VERSION ""

NS_ :

BS_:

BU_: DSAU vHS_M SHVU_RR DPSS AMP ICC RLPSM APSM RWPC RRHV RRPSM CGW_CCU APSS ATS RLHV FPM RDC PSM ASAU

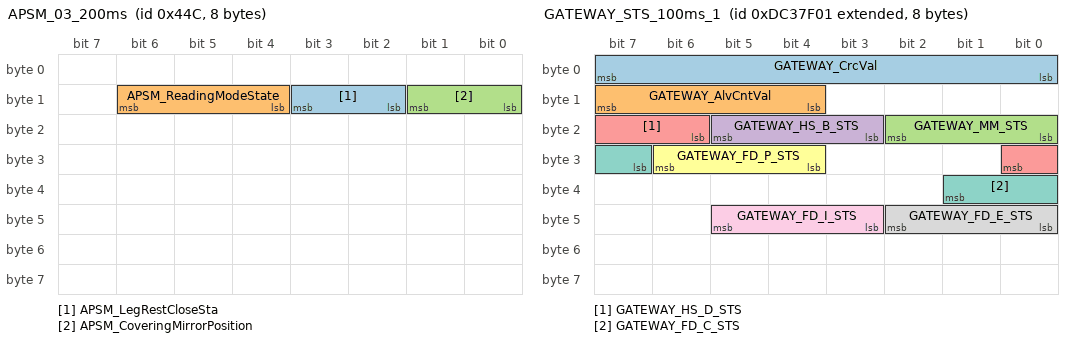
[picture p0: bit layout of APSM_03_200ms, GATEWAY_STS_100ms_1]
BO_ 1100 APSM_03_200ms: 8 APSM
 SG_ APSM_LegRestCloseSta : 10|2@1+ (1,0) [0|0] ""  RRPSM
 SG_ APSM_ReadingModeState : 12|3@1+ (1,0) [0|0] ""  RRPSM
 SG_ APSM_CoveringMirrorPosition : 8|2@1+ (1,0) [0|0] ""  CGW_CCU

BO_ 2378399489 GATEWAY_STS_100ms_1: 8 CGW_CCU
 SG_ GATEWAY_CrcVal : 0|8@1+ (1,0) [0|0] ""  vHS_M
 SG_ GATEWAY_AlvCntVal : 12|4@1+ (1,0) [0|0] ""  Vector__XXX
 SG_ GATEWAY_MM_STS : 16|3@1+ (1,0) [0|0] ""  Vector__XXX
 SG_ GATEWAY_HS_B_STS : 19|3@1+ (1,0) [0|0] ""  Vector__XXX
 SG_ GATEWAY_HS_D_STS : 22|3@1+ (1,0) [0|0] ""  Vector__XXX
 SG_ GATEWAY_FD_P_STS : 28|3@1+ (1,0) [0|0] ""  Vector__XXX
 SG_ GATEWAY_FD_C_STS : 31|3@1+ (1,0) [0|0] ""  Vector__XXX
 SG_ GATEWAY_FD_E_STS : 40|3@1+ (1,0) [0|0] ""  Vector__XXX
 SG_ GATEWAY_FD_I_STS : 43|3@1+ (1,0) [0|0] ""  Vector__XXX

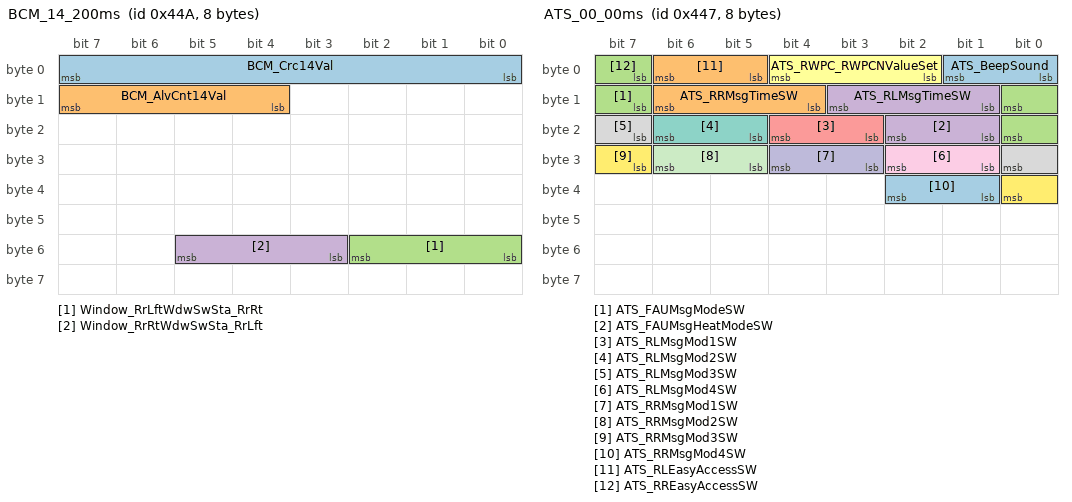
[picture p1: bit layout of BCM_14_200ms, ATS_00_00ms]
BO_ 1098 BCM_14_200ms: 8 CGW_CCU
 SG_ BCM_Crc14Val : 0|8@1+ (1,0) [0|0] ""  Vector__XXX
 SG_ BCM_AlvCnt14Val : 12|4@1+ (1,0) [0|0] ""  Vector__XXX
 SG_ Window_RrLftWdwSwSta_RrRt : 48|3@1+ (1,0) [0|0] ""  RDC
 SG_ Window_RrRtWdwSwSta_RrLft : 51|3@1+ (1,0) [0|0] ""  RDC

BO_ 1092 SMK_02_200ms: 8 CGW_CCU
 SG_ SMK_Crc2Val : 0|8@1+ (1,0) [0|0] ""  Vector__XXX
 SG_ SMK_AlvCnt2Val : 12|4@1+ (1,0) [0|0] ""  Vector__XXX
 SG_ SSB_StrtStpBtnSw1Sta : 16|2@1+ (1,0) [0|0] ""  Vector__XXX
 SG_ SSB_StrtStpBtnSw2Sta : 18|2@1+ (1,0) [0|0] ""  Vector__XXX
 SG_ SMK_TrmnlCtrlSta : 20|4@1+ (1,0) [0|0] ""  Vector__XXX
 SG_ SMK_TrmnlMngrSta : 24|5@1+ (1,0) [0|0] ""  FPM
 SG_ SMK_AuthSta : 29|3@1+ (1,0) [0|0] ""  PSM,APSM,RLPSM,RRPSM
 SG_ SMK_Ign1InSta : 32|2@1+ (1,0) [0|0] ""  Vector__XXX
 SG_ SMK_Ign1RlySta : 34|2@1+ (1,0) [0|0] ""  Vector__XXX
 SG_ SMK_Ign2InSta : 36|2@1+ (1,0) [0|0] ""  Vector__XXX
 SG_ SMK_Ign2RlySta : 38|2@1+ (1,0) [0|0] ""  Vector__XXX
 SG_ SMK_StrtFdbckSta : 40|2@1+ (1,0) [0|0] ""  Vector__XXX
 SG_ SMK_StrtrRlyOutSta : 42|2@1+ (1,0) [0|0] ""  Vector__XXX
 SG_ SMK_AccInSta : 44|2@1+ (1,0) [0|0] ""  Vector__XXX
 SG_ SMK_AccRlySta : 46|2@1+ (1,0) [0|0] ""  Vector__XXX
 SG_ SMK_CLUAccIndOnReq : 48|2@1+ (1,0) [0|0] ""  Vector__XXX
 SG_ SMK_TlEngRunSta : 56|2@1+ (1,0) [0|0] ""  PSM,APSM,RLPSM,RRPSM,RLHV,RRHV,SHVU_RR,DPSS,FPM,ATS,DSAU,ASAU
 SG_ SMK_TlCrnkModSta : 58|2@1+ (1,0) [0|0] ""  PSM,APSM,RLPSM,RRPSM,DPSS,ATS,DSAU,ASAU
 SG_ SMK_RmtKeyEngRunSta : 60|2@1+ (1,0) [0|0] ""  Vector__XXX

BO_ 1093 SMK_06_200ms: 8 CGW_CCU
 SG_ SMK_Crc6Val : 0|8@1+ (1,0) [0|0] ""  Vector__XXX
 SG_ SMK_AlvCnt6Val : 12|4@1+ (1,0) [0|0] ""  Vector__XXX
 SG_ Lamp_HzrdBlnkngSta : 16|3@1+ (1,0) [0|0] ""  Vector__XXX
 SG_ RSPA_LearntSta : 19|2@1+ (1,0) [0|0] ""  Vector__XXX
 SG_ Lamp_SmrtWlcmLtOnReq : 21|2@1+ (1,0) [0|0] ""  Vector__XXX
 SG_ Fob_BattStaInfo : 24|2@1+ (1,0) [0|0] ""  Vector__XXX
 SG_ Fob_FoundDrvWlcmArea : 26|2@1+ (1,0) [0|0] ""  Vector__XXX
 SG_ Fob_FoundAsstWlcmArea : 28|2@1+ (1,0) [0|0] ""  Vector__XXX
 SG_ Fob_FoundExtrnlArea : 30|2@1+ (1,0) [0|0] ""  Vector__XXX
 SG_ Fob_FoundIntArea : 32|2@1+ (1,0) [0|0] ""  Vector__XXX
 SG_ Fob_LearntSta : 34|2@1+ (1,0) [0|0] ""  Vector__XXX
 SG_ RSPA_RFSigErrSta : 36|2@1+ (1,0) [0|0] ""  Vector__XXX
 SG_ RSPA_CanErrSta : 38|2@1+ (1,0) [0|0] ""  Vector__XXX
 SG_ LFAnt_FltSta : 40|2@1+ (1,0) [0|0] ""  Vector__XXX
 SG_ LFAnt_SrchSta : 42|2@1+ (1,0) [0|0] ""  RWPC
 SG_ Auth_ISKLearnSta : 44|3@1+ (1,0) [0|0] ""  Vector__XXX
 SG_ RSPA_ModSta_SMK : 48|3@1+ (1,0) [0|0] ""  PSM
 SG_ RSPA_FobBattSta : 51|3@1+ (1,0) [0|0] ""  Vector__XXX
 SG_ Fob_BtnReleasedSta : 54|2@1+ (1,0) [0|0] ""  Vector__XXX
 SG_ USM_SmrtTrnkTlgtModSta : 56|3@1+ (1,0) [0|0] ""  Vector__XXX
 SG_ USM_WALModSta : 59|3@1+ (1,0) [0|0] ""  Vector__XXX
 SG_ Fob_FoundWlcmArea : 62|2@1+ (1,0) [0|0] ""  Vector__XXX

BO_ 1095 ATS_00_00ms: 8 ATS
 SG_ ATS_BeepSound : 0|2@1+ (1,0) [0|0] ""  AMP
 SG_ ATS_RRMsgTimeSW : 12|3@1+ (1,0) [0|0] ""  RLPSM,RRPSM
 SG_ ATS_FAUMsgModeSW : 15|2@1+ (1,0) [0|0] ""  APSM,ASAU,RLPSM,RRPSM
 SG_ ATS_FAUMsgHeatModeSW : 17|2@1+ (1,0) [0|0] ""  APSM,ASAU,RLPSM,RRPSM
 SG_ ATS_RLMsgMod1SW : 19|2@1+ (1,0) [0|0] ""  RLPSM
 SG_ ATS_RWPC_RWPCNValueSet : 2|3@1+ (1,0) [0|0] ""  RWPC
 SG_ ATS_RLMsgMod2SW : 21|2@1+ (1,0) [0|0] ""  RLPSM
 SG_ ATS_RLMsgMod3SW : 23|2@1+ (1,0) [0|0] ""  RLPSM
 SG_ ATS_RLMsgMod4SW : 25|2@1+ (1,0) [0|0] ""  RLPSM
 SG_ ATS_RRMsgMod1SW : 27|2@1+ (1,0) [0|0] ""  RLPSM
 SG_ ATS_RRMsgMod2SW : 29|2@1+ (1,0) [0|0] ""  RLPSM
 SG_ ATS_RRMsgMod3SW : 31|2@1+ (1,0) [0|0] ""  RLPSM
 SG_ ATS_RRMsgMod4SW : 33|2@1+ (1,0) [0|0] ""  RLPSM
 SG_ ATS_RLEasyAccessSW : 5|2@1+ (1,0) [0|0] ""  RLPSM
 SG_ ATS_RREasyAccessSW : 7|2@1+ (1,0) [0|0] ""  RRPSM
 SG_ ATS_RLMsgTimeSW : 9|3@1+ (1,0) [0|0] ""  RLPSM,RRPSM

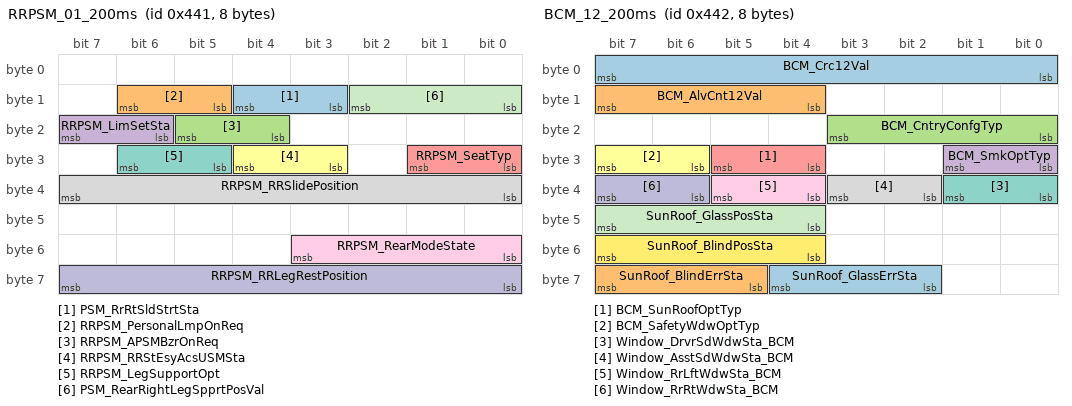
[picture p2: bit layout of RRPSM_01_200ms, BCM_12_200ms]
BO_ 1089 RRPSM_01_200ms: 8 RRPSM
 SG_ PSM_RrRtSldStrtSta : 11|2@1+ (1,0) [0|0] ""  APSM
 SG_ RRPSM_PersonalLmpOnReq : 13|2@1+ (1,0) [0|0] ""  ATS
 SG_ RRPSM_APSMBzrOnReq : 20|2@1+ (1,0) [0|0] ""  APSM,ATS
 SG_ RRPSM_LimSetSta : 22|2@1+ (1,0) [0|0] ""  ATS
 SG_ RRPSM_SeatTyp : 24|2@1+ (1,0) [0|0] ""  APSM,PSM
 SG_ RRPSM_RRStEsyAcsUSMSta : 27|2@1+ (1,0) [0|0] ""  ATS,CGW_CCU
 SG_ RRPSM_LegSupportOpt : 29|2@1+ (1,0) [0|0] ""  ATS,CGW_CCU
 SG_ RRPSM_RRSlidePosition : 32|8@1+ (1,0) [0|0] ""  APSM
 SG_ RRPSM_RearModeState : 48|4@1+ (1,0) [0|0] ""  APSM,ATS,RDC,CGW_CCU
 SG_ RRPSM_RRLegRestPosition : 56|8@1+ (1,0) [0|0] ""  APSM
 SG_ PSM_RearRightLegSpprtPosVal : 8|3@1+ (1,0) [0|0] ""  APSM

BO_ 1090 BCM_12_200ms: 8 CGW_CCU
 SG_ BCM_Crc12Val : 0|8@1+ (1,0) [0|0] ""  Vector__XXX
 SG_ BCM_AlvCnt12Val : 12|4@1+ (1,0) [0|0] ""  Vector__XXX
 SG_ BCM_CntryConfgTyp : 16|4@1+ (1,0) [0|0] ""  RWPC,PSM,APSM,RLPSM,RRPSM,SHVU_RR,RDC,DPSS,APSS,ATS
 SG_ BCM_SmkOptTyp : 24|2@1+ (1,0) [0|0] ""  Vector__XXX
 SG_ BCM_SunRoofOptTyp : 28|2@1+ (1,0) [0|0] ""  AMP,ATS
 SG_ BCM_SafetyWdwOptTyp : 30|2@1+ (1,0) [0|0] ""  Vector__XXX
 SG_ Window_DrvrSdWdwSta_BCM : 32|2@1+ (1,0) [0|0] ""  AMP
 SG_ Window_AsstSdWdwSta_BCM : 34|2@1+ (1,0) [0|0] ""  AMP
 SG_ Window_RrLftWdwSta_BCM : 36|2@1+ (1,0) [0|0] ""  RDC,AMP,ATS
 SG_ Window_RrRtWdwSta_BCM : 38|2@1+ (1,0) [0|0] ""  RDC,AMP,ATS
 SG_ SunRoof_GlassPosSta : 44|4@1+ (1,0) [0|0] ""  Vector__XXX
 SG_ SunRoof_BlindPosSta : 52|4@1+ (1,0) [0|0] ""  Vector__XXX
 SG_ SunRoof_GlassErrSta : 58|3@1+ (1,0) [0|0] ""  Vector__XXX
 SG_ SunRoof_BlindErrSta : 61|3@1+ (1,0) [0|0] ""  Vector__XXX

BO_ 2563128577 HU_AMP_P_01_1: 8 CGW_CCU
 SG_ AMP_SetMaxMainVolStep : 14|2@1+ (1,0) [0|0] ""  AMP

BO_ 2315420673 HU_FPM_E_04_1: 8 CGW_CCU
 SG_ AVN_Encrypted_Result4 : 0|64@1+ (1,0) [0|0] ""  FPM

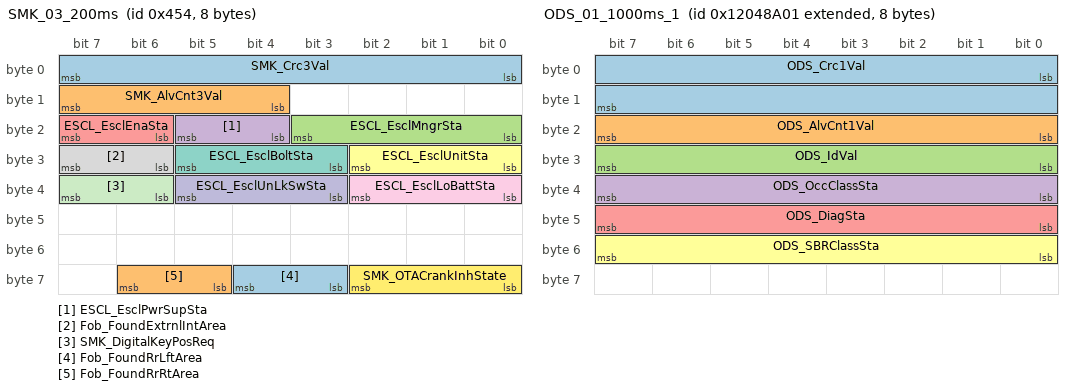
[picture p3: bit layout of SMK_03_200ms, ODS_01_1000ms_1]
BO_ 1108 SMK_03_200ms: 8 CGW_CCU
 SG_ SMK_Crc3Val : 0|8@1+ (1,0) [0|0] ""  Vector__XXX
 SG_ SMK_AlvCnt3Val : 12|4@1+ (1,0) [0|0] ""  Vector__XXX
 SG_ ESCL_EsclMngrSta : 16|4@1+ (1,0) [0|0] ""  Vector__XXX
 SG_ ESCL_EsclPwrSupSta : 20|2@1+ (1,0) [0|0] ""  Vector__XXX
 SG_ ESCL_EsclEnaSta : 22|2@1+ (1,0) [0|0] ""  Vector__XXX
 SG_ ESCL_EsclUnitSta : 24|3@1+ (1,0) [0|0] ""  Vector__XXX
 SG_ ESCL_EsclBoltSta : 27|3@1+ (1,0) [0|0] ""  Vector__XXX
 SG_ Fob_FoundExtrnlIntArea : 30|2@1+ (1,0) [0|0] ""  Vector__XXX
 SG_ ESCL_EsclLoBattSta : 32|3@1+ (1,0) [0|0] ""  Vector__XXX
 SG_ ESCL_EsclUnLkSwSta : 35|3@1+ (1,0) [0|0] ""  Vector__XXX
 SG_ SMK_DigitalKeyPosReq : 38|2@1+ (1,0) [0|0] ""  Vector__XXX
 SG_ SMK_OTACrankInhState : 56|3@1+ (1,0) [0|0] ""  AMP
 SG_ Fob_FoundRrLftArea : 59|2@1+ (1,0) [0|0] ""  Vector__XXX
 SG_ Fob_FoundRrRtArea : 61|2@1+ (1,0) [0|0] ""  Vector__XXX

BO_ 2449771009 ODS_01_1000ms_1: 8 CGW_CCU
 SG_ ODS_Crc1Val : 0|16@1+ (1,0) [0|0] ""  Vector__XXX
 SG_ ODS_AlvCnt1Val : 16|8@1+ (1,0) [0|0] ""  Vector__XXX
 SG_ ODS_IdVal : 24|8@1+ (1,0) [0|0] ""  Vector__XXX
 SG_ ODS_OccClassSta : 32|8@1+ (1,0) [0|0] ""  APSM,ATS
 SG_ ODS_DiagSta : 40|8@1+ (1,0) [0|0] ""  Vector__XXX
 SG_ ODS_SBRClassSta : 48|8@1+ (1,0) [0|0] ""  Vector__XXX

BO_ 2449771010 ODS_01_1000ms_2: 8 CGW_CCU

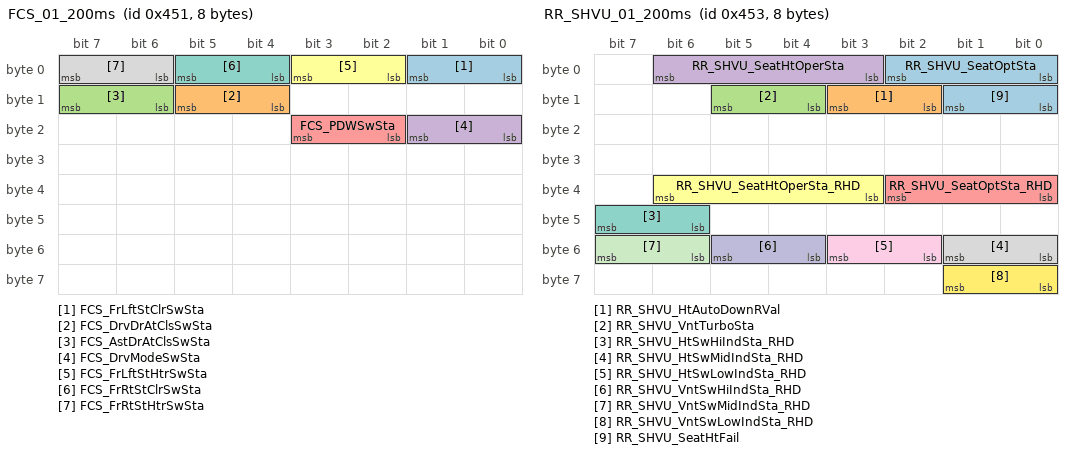
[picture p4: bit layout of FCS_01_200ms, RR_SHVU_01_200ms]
BO_ 1105 FCS_01_200ms: 8 CGW_CCU
 SG_ FCS_FrLftStClrSwSta : 0|2@1+ (1,0) [0|0] ""  PSM,APSM
 SG_ FCS_DrvDrAtClsSwSta : 12|2@1+ (1,0) [0|0] ""  Vector__XXX
 SG_ FCS_AstDrAtClsSwSta : 14|2@1+ (1,0) [0|0] ""  Vector__XXX
 SG_ FCS_DrvModeSwSta : 16|2@1+ (1,0) [0|0] ""  Vector__XXX
 SG_ FCS_PDWSwSta : 18|2@1+ (1,0) [0|0] ""  Vector__XXX
 SG_ FCS_FrLftStHtrSwSta : 2|2@1+ (1,0) [0|0] ""  PSM,APSM
 SG_ FCS_FrRtStClrSwSta : 4|2@1+ (1,0) [0|0] ""  PSM,APSM
 SG_ FCS_FrRtStHtrSwSta : 6|2@1+ (1,0) [0|0] ""  PSM,APSM

BO_ 1107 RR_SHVU_01_200ms: 8 SHVU_RR
 SG_ RR_SHVU_SeatOptSta : 0|3@1+ (1,0) [0|0] ""  ASAU,ATS,CGW_CCU,ATS,CGW_CCU
 SG_ RR_SHVU_HtAutoDownRVal : 10|2@1+ (1,0) [0|0] ""  ASAU,ATS,ASAU,ATS,CGW_CCU,CGW_CCU
 SG_ RR_SHVU_VntTurboSta : 12|2@1+ (1,0) [0|0] ""  ASAU,ATS,ASAU,ATS,CGW_CCU,CGW_CCU
 SG_ RR_SHVU_SeatHtOperSta : 3|4@1+ (1,0) [0|0] ""  APSM,ASAU,ATS,CGW_CCU,ASAU,ATS,CGW_CCU,ATS,CGW_CCU
 SG_ RR_SHVU_SeatOptSta_RHD : 32|3@1+ (1,0) [0|0] ""  ASAU,ATS,CGW_CCU,ATS,CGW_CCU
 SG_ RR_SHVU_SeatHtOperSta_RHD : 35|4@1+ (1,0) [0|0] ""  ASAU,ATS,CGW_CCU,ATS,CGW_CCU
 SG_ RR_SHVU_HtSwHiIndSta_RHD : 46|2@1+ (1,0) [0|0] ""  ASAU,ATS,CGW_CCU,ATS,CGW_CCU
 SG_ RR_SHVU_HtSwMidIndSta_RHD : 48|2@1+ (1,0) [0|0] ""  ASAU,ATS,CGW_CCU,ATS,CGW_CCU
 SG_ RR_SHVU_HtSwLowIndSta_RHD : 50|2@1+ (1,0) [0|0] ""  ASAU,ATS,CGW_CCU,ATS,CGW_CCU
 SG_ RR_SHVU_VntSwHiIndSta_RHD : 52|2@1+ (1,0) [0|0] ""  ASAU,ATS,CGW_CCU,ATS,CGW_CCU
 SG_ RR_SHVU_VntSwMidIndSta_RHD : 54|2@1+ (1,0) [0|0] ""  ASAU,ATS,CGW_CCU,ATS,CGW_CCU
 SG_ RR_SHVU_VntSwLowIndSta_RHD : 56|2@1+ (1,0) [0|0] ""  ASAU,ATS,CGW_CCU,ATS,CGW_CCU
 SG_ RR_SHVU_SeatHtFail : 8|2@1+ (1,0) [0|0] ""  ASAU,ATS,CGW_CCU,CGW_CCU

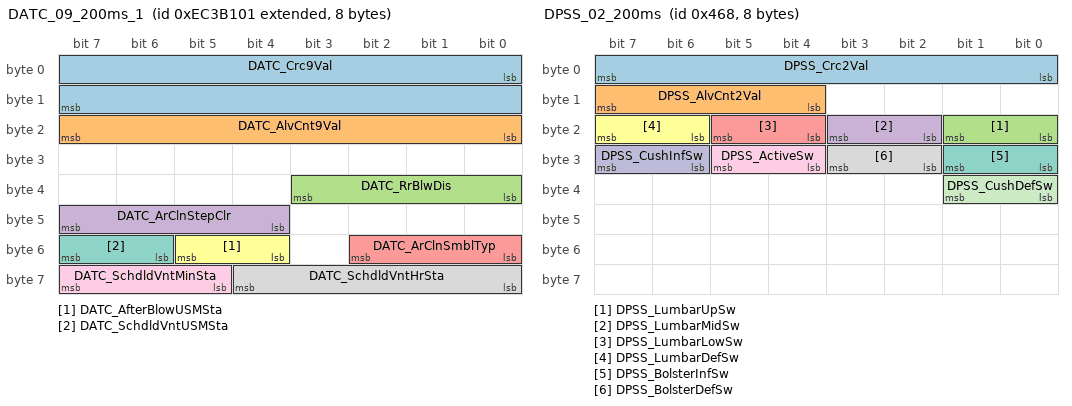
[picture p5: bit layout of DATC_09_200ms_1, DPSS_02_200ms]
BO_ 2395189505 DATC_09_200ms_1: 8 CGW_CCU
 SG_ DATC_Crc9Val : 0|16@1+ (1,0) [0|0] ""  Vector__XXX
 SG_ DATC_AlvCnt9Val : 16|8@1+ (1,0) [0|0] ""  Vector__XXX
 SG_ DATC_RrBlwDis : 32|4@1+ (1,0) [0|0] ""  ATS
 SG_ DATC_ArClnStepClr : 44|4@1+ (1,0) [0|0] ""  ATS
 SG_ DATC_ArClnSmblTyp : 48|3@1+ (1,0) [0|0] ""  ATS
 SG_ DATC_AfterBlowUSMSta : 52|2@1+ (1,0) [0|0] ""  Vector__XXX
 SG_ DATC_SchdldVntUSMSta : 54|2@1+ (1,0) [0|0] ""  Vector__XXX
 SG_ DATC_SchdldVntHrSta : 56|5@1+ (1,0) [0|0] ""  Vector__XXX
 SG_ DATC_SchdldVntMinSta : 61|3@1+ (1,0) [0|0] ""  Vector__XXX

BO_ 1128 DPSS_02_200ms: 8 DPSS
 SG_ DPSS_Crc2Val : 0|8@1+ (1,0) [0|0] ""  DSAU
 SG_ DPSS_AlvCnt2Val : 12|4@1+ (1,0) [0|0] ""  DSAU
 SG_ DPSS_LumbarUpSw : 16|2@1+ (1,0) [0|0] ""  DSAU
 SG_ DPSS_LumbarMidSw : 18|2@1+ (1,0) [0|0] ""  DSAU
 SG_ DPSS_LumbarLowSw : 20|2@1+ (1,0) [0|0] ""  DSAU
 SG_ DPSS_LumbarDefSw : 22|2@1+ (1,0) [0|0] ""  DSAU
 SG_ DPSS_BolsterInfSw : 24|2@1+ (1,0) [0|0] ""  DSAU
 SG_ DPSS_BolsterDefSw : 26|2@1+ (1,0) [0|0] ""  DSAU
 SG_ DPSS_ActiveSw : 28|2@1+ (1,0) [0|0] ""  DSAU
 SG_ DPSS_CushInfSw : 30|2@1+ (1,0) [0|0] ""  DSAU
 SG_ DPSS_CushDefSw : 32|2@1+ (1,0) [0|0] ""  DSAU

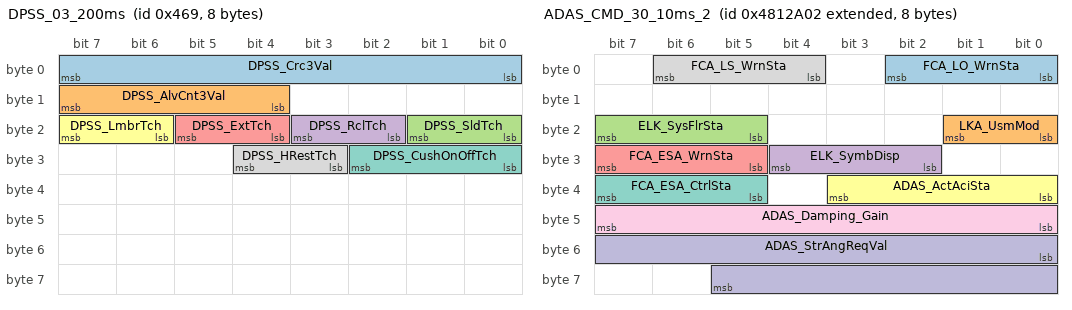
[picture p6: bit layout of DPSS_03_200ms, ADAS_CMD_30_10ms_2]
BO_ 1129 DPSS_03_200ms: 8 DPSS
 SG_ DPSS_Crc3Val : 0|8@1+ (1,0) [0|0] ""  CGW_CCU
 SG_ DPSS_AlvCnt3Val : 12|4@1+ (1,0) [0|0] ""  CGW_CCU
 SG_ DPSS_SldTch : 16|2@1+ (1,0) [0|0] ""  CGW_CCU
 SG_ DPSS_RclTch : 18|2@1+ (1,0) [0|0] ""  CGW_CCU
 SG_ DPSS_ExtTch : 20|2@1+ (1,0) [0|0] ""  CGW_CCU
 SG_ DPSS_LmbrTch : 22|2@1+ (1,0) [0|0] ""  CGW_CCU
 SG_ DPSS_CushOnOffTch : 24|3@1+ (1,0) [0|0] ""  CGW_CCU
 SG_ DPSS_HRestTch : 27|2@1+ (1,0) [0|0] ""  CGW_CCU

BO_ 2223057410 ADAS_CMD_30_10ms_2: 8 CGW_CCU
 SG_ FCA_LO_WrnSta : 0|3@1+ (1,0) [0|0] ""  Vector__XXX
 SG_ LKA_UsmMod : 16|2@1+ (1,0) [0|0] ""  Vector__XXX
 SG_ ELK_SysFlrSta : 21|3@1+ (1,0) [0|0] ""  Vector__XXX
 SG_ ELK_SymbDisp : 26|3@1+ (1,0) [0|0] ""  Vector__XXX
 SG_ FCA_ESA_WrnSta : 29|3@1+ (1,0) [0|0] ""  Vector__XXX
 SG_ ADAS_ActAciSta : 32|4@1+ (1,0) [0|0] ""  Vector__XXX
 SG_ FCA_ESA_CtrlSta : 37|3@1+ (1,0) [0|0] ""  Vector__XXX
 SG_ FCA_LS_WrnSta : 4|3@1+ (1,0) [0|0] ""  Vector__XXX
 SG_ ADAS_Damping_Gain : 40|8@1+ (1,0) [0|0] ""  Vector__XXX
 SG_ ADAS_StrAngReqVal : 48|14@1- (0.1,0) [0|0] "Deg"  Vector__XXX

BO_ 1127 DPSS_01_200ms: 8 DPSS
 SG_ DPSS_Crc1Val : 0|8@1+ (1,0) [0|0] ""  PSM
 SG_ DPSS_AlvCnt1Val : 12|4@1+ (1,0) [0|0] ""  PSM
 SG_ DPSS_StExtFwdMvBtn : 16|2@1+ (1,0) [0|0] ""  PSM
 SG_ DPSS_StExtBwdMvBtn : 18|2@1+ (1,0) [0|0] ""  PSM
 SG_ DPSS_StSldFwdMvBtn : 20|2@1+ (1,0) [0|0] ""  PSM,RLPSM
 SG_ DPSS_StSldBwdMvBtn : 24|2@1+ (1,0) [0|0] ""  PSM,RLPSM
 SG_ DPSS_StRclFwdMvBtn : 26|2@1+ (1,0) [0|0] ""  PSM,RLPSM
 SG_ DPSS_StRclBwdMvBtn : 28|2@1+ (1,0) [0|0] ""  PSM,RLPSM
 SG_ DPSS_StHgtUpMvBtn : 30|2@1+ (1,0) [0|0] ""  PSM,RLPSM
 SG_ DPSS_StHgtDnMvBtn : 32|2@1+ (1,0) [0|0] ""  PSM,RLPSM
 SG_ DPSS_StTltUpMvBtn : 34|2@1+ (1,0) [0|0] ""  PSM
 SG_ DPSS_StTltDnMvBtn : 36|2@1+ (1,0) [0|0] ""  PSM
 SG_ DPSS_StHRestUpMvBtn : 38|2@1+ (1,0) [0|0] ""  PSM
 SG_ DPSS_StHRestDnMvBtn : 40|2@1+ (1,0) [0|0] ""  PSM
 SG_ DPSS_StHRestFwdMvBtn : 42|2@1+ (1,0) [0|0] ""  PSM
 SG_ DPSS_StHRestBwdMvBtn : 44|2@1+ (1,0) [0|0] ""  PSM
 SG_ DPSS_StLegUpMvBtn : 46|2@1+ (1,0) [0|0] ""  PSM
 SG_ DPSS_StLegDnMvBtn : 48|2@1+ (1,0) [0|0] ""  PSM
 SG_ DPSS_StRlxModeBtn : 50|2@1+ (1,0) [0|0] ""  Vector__XXX
 SG_ DPSS_StRlxReturnBtn : 52|2@1+ (1,0) [0|0] ""  Vector__XXX
 SG_ DPSS_RlxStTltUpMvBtn : 54|2@1+ (1,0) [0|0] ""  Vector__XXX
 SG_ DPSS_RlxStTltDnMvBtn : 56|2@1+ (1,0) [0|0] ""  Vector__XXX

BO_ 1124 BCM_15_200ms: 8 CGW_CCU
 SG_ BCM_Crc15Val : 0|8@1+ (1,0) [0|0] ""  Vector__XXX
 SG_ BCM_AlvCnt15Val : 12|4@1+ (1,0) [0|0] ""  Vector__XXX
 SG_ Window_DrvrSdWdwActSta : 16|4@1+ (1,0) [0|0] ""  Vector__XXX
 SG_ Window_AsstSdWdwActSta : 20|4@1+ (1,0) [0|0] ""  Vector__XXX
 SG_ Window_RrLftWdwActSta : 24|4@1+ (1,0) [0|0] ""  Vector__XXX
 SG_ Window_RrRtWdwActSta : 28|4@1+ (1,0) [0|0] ""  Vector__XXX
 SG_ Window_DrvrSdWdwDetailOpnSta : 32|3@1+ (1,0) [0|0] ""  Vector__XXX
 SG_ Window_AsstSdWdwDetailOpnSta : 35|3@1+ (1,0) [0|0] ""  Vector__XXX
 SG_ Window_DrvrSdWdwErrAntPinch : 38|2@1+ (1,0) [0|0] ""  Vector__XXX
 SG_ Window_RrLftWdwDetailOpnSta : 40|3@1+ (1,0) [0|0] ""  Vector__XXX
 SG_ Window_RrRtWdwDetailOpnSta : 43|3@1+ (1,0) [0|0] ""  Vector__XXX
 SG_ Window_AsstSdWdwErrAntPinch : 46|2@1+ (1,0) [0|0] ""  Vector__XXX
 SG_ Window_RrLftWdwErrAntPinch : 48|2@1+ (1,0) [0|0] ""  Vector__XXX
 SG_ Window_RrRtWdwErrAntPinch : 50|2@1+ (1,0) [0|0] ""  Vector__XXX
 SG_ SunRoof_RrBlindPosSta : 52|4@1+ (1,0) [0|0] ""  ATS
 SG_ Window_RrLftWdwSwSta : 56|3@1+ (1,0) [0|0] ""  RDC
 SG_ Window_RrRtWdwSwSta : 59|3@1+ (1,0) [0|0] ""  RDC

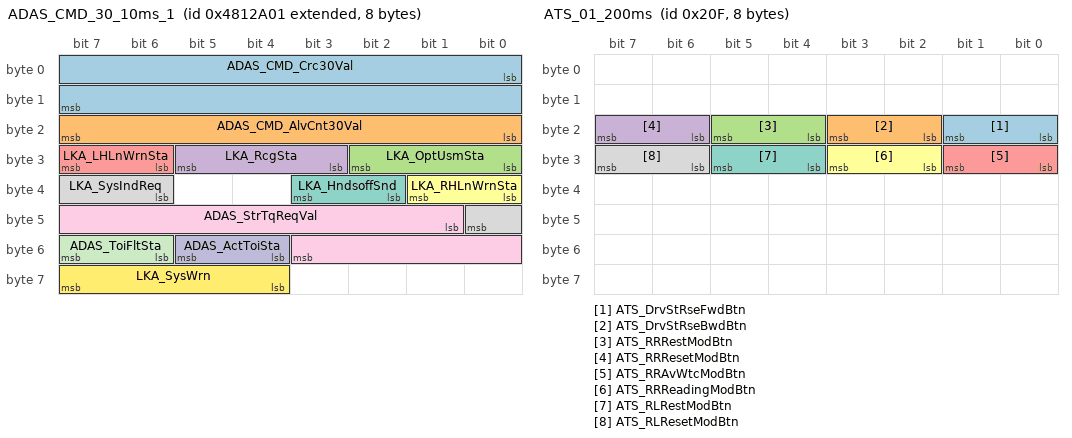
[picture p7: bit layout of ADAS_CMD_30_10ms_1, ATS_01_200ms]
BO_ 2223057409 ADAS_CMD_30_10ms_1: 8 CGW_CCU
 SG_ ADAS_CMD_Crc30Val : 0|16@1+ (1,0) [0|0] ""  Vector__XXX
 SG_ ADAS_CMD_AlvCnt30Val : 16|8@1+ (1,0) [0|0] ""  Vector__XXX
 SG_ LKA_OptUsmSta : 24|3@1+ (1,0) [0|0] ""  Vector__XXX
 SG_ LKA_RcgSta : 27|3@1+ (1,0) [0|0] ""  Vector__XXX
 SG_ LKA_LHLnWrnSta : 30|2@1+ (1,0) [0|0] ""  AMP,DSAU
 SG_ LKA_RHLnWrnSta : 32|2@1+ (1,0) [0|0] ""  AMP,DSAU
 SG_ LKA_HndsoffSnd : 34|2@1+ (1,0) [0|0] ""  AMP
 SG_ LKA_SysIndReq : 38|3@1+ (1,0) [0|0] ""  Vector__XXX
 SG_ ADAS_StrTqReqVal : 41|11@1+ (0.0078125,-8) [0|0] "Nm"  Vector__XXX
 SG_ ADAS_ActToiSta : 52|2@1+ (1,0) [0|0] ""  Vector__XXX
 SG_ ADAS_ToiFltSta : 54|2@1+ (1,0) [0|0] ""  Vector__XXX
 SG_ LKA_SysWrn : 60|4@1+ (1,0) [0|0] ""  Vector__XXX

BO_ 527 ATS_01_200ms: 8 ATS
 SG_ ATS_DrvStRseFwdBtn : 16|2@1+ (1,0) [0|0] ""  PSM
 SG_ ATS_DrvStRseBwdBtn : 18|2@1+ (1,0) [0|0] ""  PSM
 SG_ ATS_RRRestModBtn : 20|2@1+ (1,0) [0|0] ""  APSM,RRPSM
 SG_ ATS_RRResetModBtn : 22|2@1+ (1,0) [0|0] ""  APSM,RRPSM
 SG_ ATS_RRAvWtcModBtn : 24|2@1+ (1,0) [0|0] ""  APSM,RRPSM
 SG_ ATS_RRReadingModBtn : 26|2@1+ (1,0) [0|0] ""  APSM,RRPSM,CGW_CCU
 SG_ ATS_RLRestModBtn : 28|2@1+ (1,0) [0|0] ""  PSM,RLPSM
 SG_ ATS_RLResetModBtn : 30|2@1+ (1,0) [0|0] ""  PSM,RLPSM

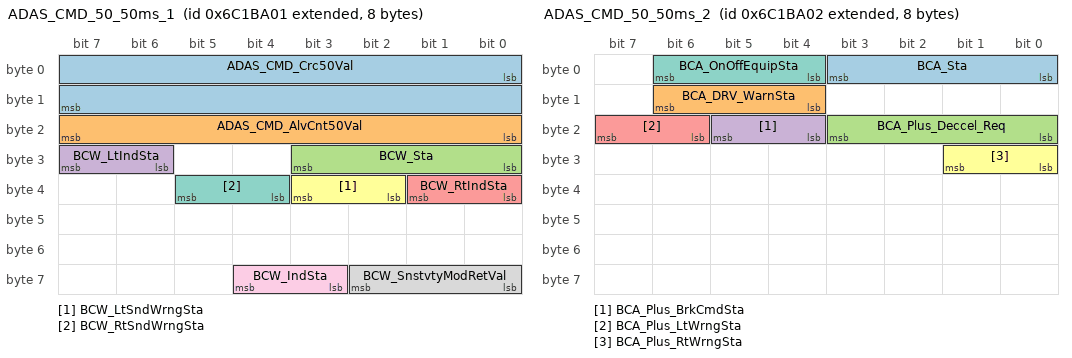
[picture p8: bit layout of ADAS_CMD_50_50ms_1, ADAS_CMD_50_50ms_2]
BO_ 2260843009 ADAS_CMD_50_50ms_1: 8 CGW_CCU
 SG_ ADAS_CMD_Crc50Val : 0|16@1+ (1,0) [0|0] ""  Vector__XXX
 SG_ ADAS_CMD_AlvCnt50Val : 16|8@1+ (1,0) [0|0] ""  Vector__XXX
 SG_ BCW_Sta : 24|4@1+ (1,0) [0|0] ""  Vector__XXX
 SG_ BCW_LtIndSta : 30|2@1+ (1,0) [0|0] ""  Vector__XXX
 SG_ BCW_RtIndSta : 32|2@1+ (1,0) [0|0] ""  Vector__XXX
 SG_ BCW_LtSndWrngSta : 34|2@1+ (1,0) [0|0] ""  AMP
 SG_ BCW_RtSndWrngSta : 36|2@1+ (1,0) [0|0] ""  AMP
 SG_ BCW_SnstvtyModRetVal : 56|3@1+ (1,0) [0|0] ""  Vector__XXX
 SG_ BCW_IndSta : 59|2@1+ (1,0) [0|0] ""  Vector__XXX

BO_ 2260843010 ADAS_CMD_50_50ms_2: 8 CGW_CCU
 SG_ BCA_Sta : 0|4@1+ (1,0) [0|0] ""  Vector__XXX
 SG_ BCA_DRV_WarnSta : 12|3@1+ (1,0) [0|0] ""  Vector__XXX
 SG_ BCA_Plus_Deccel_Req : 16|4@1+ (0.04,0) [0|0] "g"  Vector__XXX
 SG_ BCA_Plus_BrkCmdSta : 20|2@1+ (1,0) [0|0] ""  Vector__XXX
 SG_ BCA_Plus_LtWrngSta : 22|2@1+ (1,0) [0|0] ""  Vector__XXX
 SG_ BCA_Plus_RtWrngSta : 24|2@1+ (1,0) [0|0] ""  Vector__XXX
 SG_ BCA_OnOffEquipSta : 4|3@1+ (1,0) [0|0] ""  Vector__XXX

BO_ 2260843011 ADAS_CMD_50_50ms_3: 8 CGW_CCU
 SG_ OSMrrLamp_LtIndSta : 0|2@1+ (1,0) [0|0] ""  Vector__XXX
 SG_ OSMrrLamp_RtIndSta : 2|2@1+ (1,0) [0|0] ""  Vector__XXX

BO_ 1150 IAU_38_00ms: 8 CGW_CCU
 SG_ IAU2FPM_EncryptedData1 : 0|64@1+ (1,0) [0|0] ""  FPM

BO_TX_BU_ 1107 : SHVU_RR,RRHV,RRPSM;
CM_ BO_ 2223057409 "[P] Periodic";
CM_ SG_ 2223057409 ADAS_CMD_Crc30Val "ADAS_CMD_CyclicRedundancyCheck30Value";
CM_ SG_ 2223057409 ADAS_CMD_AlvCnt30Val "ADAS_CMD_AliveCounter30Value";
CM_ SG_ 2223057409 LKA_OptUsmSta "LKA_OptionUsmStatus ##2G##LDW_LKA - LKA11 - CF_LKA_Opt_USM";
CM_ SG_ 2223057409 LKA_RcgSta "LKA_RecognitionStatus ##2G##LDW_LKA - LKA11 - CF_LKA_LaneRecogState";
CM_ SG_ 2223057409 LKA_LHLnWrnSta "LKA_LHLaneWarningStatus ##2G##LDW_LKA - LKA11 - CF_LKA_LHWarning";
CM_ SG_ 2223057409 LKA_RHLnWrnSta "LKA_RHLaneWarningStatus ##2G##LDW_LKA - LKA11 - CF_LKA_RHWarning";
CM_ SG_ 2223057409 LKA_HndsoffSnd "LKA_HandsoffSound ##2G##LDW_LKA - LKA11 - CF_LKA_HandsOff_Snd";
CM_ SG_ 2223057409 LKA_SysIndReq "LKA_SystemIndicatorRequest ##2G##LDW_LKA - LKA11 - CF_LKA_SymbolState";
CM_ SG_ 2223057409 ADAS_StrTqReqVal "LKA_SteeringTorqueRequestValue ##2G##LDW_LKA - LKA11 - CR_LKA_StrToqReq";
CM_ SG_ 2223057409 ADAS_ActToiSta "ADAS_ActiveTorqueOverlayInterfaceStatus ##2G##LDW_LKA - LKA11 - CF_LKA_ActToi";
CM_ SG_ 2223057409 ADAS_ToiFltSta "ADAS_TorqueOverlayInterfaceFaultStatus ##2G##LDW_LKA - LKA11 - CF_LKA_ToiFlt";
CM_ SG_ 2223057409 LKA_SysWrn "LKA_Additional_Info";
CM_ BO_ 2223057410 "[P] Periodic";
CM_ SG_ 2223057410 FCA_LO_WrnSta "FCA_LO_WarningStatus";
CM_ SG_ 2223057410 LKA_UsmMod "LKA_USM Mode ##2G##LDW_LKA-LKA11-CF_LKA_USM_Mode";
CM_ SG_ 2223057410 ELK_SysFlrSta "ELK System Failure State";
CM_ SG_ 2223057410 ELK_SymbDisp "ELK Symbol Display";
CM_ SG_ 2223057410 FCA_ESA_WrnSta "FCA w/ ESA HMI";
CM_ SG_ 2223057410 ADAS_ActAciSta "ADAS_ActiveAngleControlInterfaceStatus";
CM_ SG_ 2223057410 FCA_ESA_CtrlSta "FCA w/ ESA Control Status";
CM_ SG_ 2223057410 FCA_LS_WrnSta "FCA_LS_WarningStatus";
CM_ SG_ 2223057410 ADAS_Damping_Gain "ADAS_Damping_Gain";
CM_ SG_ 2223057410 ADAS_StrAngReqVal "ADAS_SteeringAngleRequestValue";
CM_ BO_ 2260843009 "[P] Periodic";
CM_ SG_ 2260843009 ADAS_CMD_Crc50Val "ADAS_CMD_CyclicRedundancyCheck50Value ##2G##BCW - BCA11 - Check_Sum";
CM_ SG_ 2260843009 ADAS_CMD_AlvCnt50Val "ADAS_CMD_AliveCounter50Value ##2G##BCW - BCA11 - AliveCounter";
CM_ SG_ 2260843009 BCW_Sta "BCW_Status ##2G##BCW - BCW11 - CF_BCW_Stat";
CM_ SG_ 2260843009 BCW_LtIndSta "BCW_LeftIndicatorStatus ##2G##BCW - BCW11 - CF_BCW_IndLeft";
CM_ SG_ 2260843009 BCW_RtIndSta "BCW_RightIndicatorStatus ##2G##BCW - BCW11 - CF_BCW_IndRight";
CM_ SG_ 2260843009 BCW_LtSndWrngSta "BCW_LeftSoundWarningStatus ##2G##BCW - BCW11 - CF_FL_SndWan";
CM_ SG_ 2260843009 BCW_RtSndWrngSta "BCW_RightSoundWarningStatus ##2G##BCW - BCW11 - CF_FR_SndWan";
CM_ SG_ 2260843009 BCW_SnstvtyModRetVal "BCW_SensitivityModeReturnValue ##2G##BCW - BCW12 - CF_BCW_DrvSetState";
CM_ BO_ 2260843010 "[P] Periodic";
CM_ SG_ 2260843010 BCA_Sta "BCA_Status ##2G##BCW - BCA11 - CF_BCA_State";
CM_ SG_ 2260843010 BCA_DRV_WarnSta "BCA Driving Situation Warning Status";
CM_ SG_ 2260843010 BCA_Plus_Deccel_Req "BCA_Plus_Deccel_Requirement";
CM_ SG_ 2260843010 BCA_Plus_BrkCmdSta "BCA_Plus_BrakeCommandStatus";
CM_ SG_ 2260843010 BCA_Plus_LtWrngSta "BCA_Plus_LeftWarningStatus";
CM_ SG_ 2260843010 BCA_Plus_RtWrngSta "BCA_Plus_RightWarningStatus";
CM_ SG_ 2260843010 BCA_OnOffEquipSta "BCA_OnOffEquipmentStatus ##2G##BCW - BCW12 - CF_BCA_USM";
CM_ BO_ 2260843011 "[P] Periodic";
CM_ SG_ 2260843011 OSMrrLamp_LtIndSta "Left Outside Mirror Indicator Control Signal";
CM_ SG_ 2260843011 OSMrrLamp_RtIndSta "Right Outside Mirror Indicator Control Signal";
CM_ BO_ 1100 "[PE] Periodic and On Event";
CM_ SG_ 1100 APSM_LegRestCloseSta "Rear Leg Rest Close State";
CM_ SG_ 1100 APSM_CoveringMirrorPosition "CoveringMirrorPosition";
CM_ BO_ 1095 "[EC] On Event and On Change";
CM_ SG_ 1095 ATS_BeepSound "ATS to AMP BEEP sound trigger";
CM_ SG_ 1095 ATS_RRMsgTimeSW "Rear Right Massage Time Button";
CM_ SG_ 1095 ATS_FAUMsgModeSW "Rear Right Foot Massage Mode Button";
CM_ SG_ 1095 ATS_FAUMsgHeatModeSW "Rear Right Foot Massage Heat Mode Button";
CM_ SG_ 1095 ATS_RLMsgMod1SW "Rear Left Massage Mode 1 Button";
CM_ SG_ 1095 ATS_RWPC_RWPCNValueSet "Rear Wireless Phone Charger ON/OFF Request";
CM_ SG_ 1095 ATS_RLMsgMod2SW "Rear Left Massage Mode 2 Button";
CM_ SG_ 1095 ATS_RLMsgMod3SW "Rear Left Massage Mode 3 Button";
CM_ SG_ 1095 ATS_RLMsgMod4SW "Rear Left Massage Mode 4 Button";
CM_ SG_ 1095 ATS_RRMsgMod1SW "Rear Right Massage Mode 1 Button";
CM_ SG_ 1095 ATS_RRMsgMod2SW "Rear Right Massage Mode 2 Button";
CM_ SG_ 1095 ATS_RRMsgMod3SW "Rear Right Massage Mode 3 Button";
CM_ SG_ 1095 ATS_RRMsgMod4SW "Rear Right Massage Mode 4 Button";
CM_ SG_ 1095 ATS_RLEasyAccessSW "ATS touch command for seat easy access (For Rear Left)";
CM_ SG_ 1095 ATS_RREasyAccessSW "ATS touch command for seat easy access (For Rear Right)";
CM_ SG_ 1095 ATS_RLMsgTimeSW "Rear Left Massage Time Button";
CM_ BO_ 527 "[PE] Periodic and On Event";
CM_ SG_ 527 ATS_DrvStRseFwdBtn "Drive Seat  RSE Forward Touch Button";
CM_ SG_ 527 ATS_DrvStRseBwdBtn "Drive Seat  RSE Backward Touch Button";
CM_ SG_ 527 ATS_RRRestModBtn "Rear Right Rest Mode Touch Button";
CM_ SG_ 527 ATS_RRResetModBtn "Rear Right Return Mode Touch Button";
CM_ SG_ 527 ATS_RRAvWtcModBtn "Rear Right AV Watching Mode Touch Button";
CM_ SG_ 527 ATS_RRReadingModBtn "Rear Right Reading Mode Touch Button";
CM_ SG_ 527 ATS_RLRestModBtn "Rear Left Rest Mode Touch Button";
CM_ SG_ 527 ATS_RLResetModBtn "Rear Left Return Mode Touch Button";
CM_ BO_ 1090 "[PE] Periodic and On Event";
CM_ SG_ 1090 BCM_Crc12Val "BCM_CyclicRedundancyCheck12Value";
CM_ SG_ 1090 BCM_AlvCnt12Val "BCM_AliveCounter12Value";
CM_ SG_ 1090 BCM_CntryConfgTyp "BCM_CountryConfigurationType ##2G##BCM - BCMmsg17 - C_CountryCfg";
CM_ SG_ 1090 BCM_SmkOptTyp "BCM_SmkOptionType ##2G##BCM - BCMmsg17 - C_SMKOption";
CM_ SG_ 1090 BCM_SunRoofOptTyp "BCM_SunRoofOptionType";
CM_ SG_ 1090 BCM_SafetyWdwOptTyp "BCM_SafetyWindowOptionType";
CM_ SG_ 1090 Window_DrvrSdWdwSta_BCM "Window_DriverSideWindowStatus ##2G##BCM - BCMmsg22 - C_DrvWindowOpenState";
CM_ SG_ 1090 Window_AsstSdWdwSta_BCM "Window_AssistantSideWindowStatus ##2G##BCM - BCMmsg22 - C_AstWindowOpenState";
CM_ SG_ 1090 Window_RrLftWdwSta_BCM "Window_RearLeftWindowStatus ##2G##BCM - BCMmsg22 - C_RLWindowOpenState";
CM_ SG_ 1090 Window_RrRtWdwSta_BCM "Window_RearRightPowerWindowStatus ##2G##BCM - BCMmsg22 - C_RRWindowOpenState";
CM_ SG_ 1090 SunRoof_GlassPosSta "SunRoof_GlassPositionStatus";
CM_ SG_ 1090 SunRoof_BlindPosSta "SunRoof_BlindPositionStatus";
CM_ SG_ 1090 SunRoof_GlassErrSta "SunRoof_GlassErrorStatus";
CM_ SG_ 1090 SunRoof_BlindErrSta "SunRoof_BlindErrorStatus";
CM_ BO_ 1098 "[PE] Periodic and On Event";
CM_ SG_ 1098 BCM_Crc14Val "BCM_CyclicRedundancyCheck14Value";
CM_ SG_ 1098 BCM_AlvCnt14Val "BCM_AliveCounter14Value";
CM_ SG_ 1098 Window_RrRtWdwSwSta_RrLft "Windiw_ReaRightWindowSwitchStatus ##2G##BCM - BCMmsg26 - C_RRWdwSwState";
CM_ BO_ 1124 "[PE] Periodic and On Event";
CM_ SG_ 1124 BCM_Crc15Val "BCM_CyclicRedundancyCheck15Value";
CM_ SG_ 1124 BCM_AlvCnt15Val "BCM_AliveCounter15Value";
CM_ SG_ 1124 Window_DrvrSdWdwActSta "Window_DriverSideWindowActionStatus ##2G##BCM - BCMmsg25 - C_DrvWindowActState";
CM_ SG_ 1124 Window_AsstSdWdwActSta "Window_AssistantSideWindowActionStatus ##2G##BCM - BCMmsg25 - C_AstWindowActState";
CM_ SG_ 1124 Window_RrLftWdwActSta "Window_RearLeftWindowActionStatus ##2G##BCM - BCMmsg25 - C_RLWindowActState";
CM_ SG_ 1124 Window_RrRtWdwActSta "Window_RearRightWindowActionStatus ##2G##BCM - BCMmsg25 - C_RRWindowActState";
CM_ SG_ 1124 Window_DrvrSdWdwDetailOpnSta "Window_DriverSideWindowDetailOpenStatus ##2G##BCM - BCMmsg26 - C_DrvWdwDetailOpenState";
CM_ SG_ 1124 Window_AsstSdWdwDetailOpnSta "Window_AssistantSideWindowDetailOpenStatus ##2G##BCM - BCMmsg26 - C_AstWdwDetailOpenState";
CM_ SG_ 1124 Window_DrvrSdWdwErrAntPinch "Window_DriverSideWindowErrorAntiPinch ##2G##BCM - BCMmsg26 - C_DrvWdwErrAntiPinch";
CM_ SG_ 1124 Window_RrLftWdwDetailOpnSta "Window_RearLeftWindowDetailOpenStatus ##2G##BCM - BCMmsg26 - C_RLWdwDetailOpenState";
CM_ SG_ 1124 Window_RrRtWdwDetailOpnSta "Window_RearRightWindowDetailOpenStatus ##2G##BCM - BCMmsg26 - C_RRWdwDetailOpenState";
CM_ SG_ 1124 Window_AsstSdWdwErrAntPinch "Window_AssistantSideWindowErrorAntiPinch ##2G##BCM - BCMmsg26 - C_AstWdwErrAntiPinch";
CM_ SG_ 1124 Window_RrLftWdwErrAntPinch "Window_RearLeftWindowErrorAntiPinch ##2G##BCM - BCMmsg26 - C_RLWdwErrAntiPinch";
CM_ SG_ 1124 Window_RrRtWdwErrAntPinch "Window_RearRightWindowErrorAntiPinch ##2G##BCM - BCMmsg26 - C_RRWdwErrAntiPinch";
CM_ SG_ 1124 SunRoof_RrBlindPosSta "SunRoof_RearBlindPositionStatus";
CM_ SG_ 1124 Window_RrLftWdwSwSta "Windiw_RearLeftWindowSwitchStatus ##2G##BCM - BCMmsg26 - C_RLWdwSwState";
CM_ SG_ 1124 Window_RrRtWdwSwSta "Windiw_ReaRightWindowSwitchStatus ##2G##BCM - BCMmsg26 - C_RRWdwSwState";
CM_ BO_ 2395189505 "[PE] Periodic and On Event";
CM_ SG_ 2395189505 DATC_Crc9Val "DATC_CyclicRedundancyCheck9Value";
CM_ SG_ 2395189505 DATC_AlvCnt9Val "DATC_AliveCounter9Value";
CM_ SG_ 2395189505 DATC_RrBlwDis "DATC_RearBlowerDisplay";
CM_ SG_ 2395189505 DATC_ArClnStepClr "DATC_AirCleaningStepColor";
CM_ SG_ 2395189505 DATC_ArClnSmblTyp "DATC_AirCleaningSymbolType";
CM_ SG_ 2395189505 DATC_AfterBlowUSMSta "DATC_AfterBlowUSMStatus";
CM_ SG_ 2395189505 DATC_SchdldVntUSMSta "DATC_ScheduledVentilationUSMStatus";
CM_ SG_ 2395189505 DATC_SchdldVntHrSta "DATC_ScheduledVentilationHourStatus";
CM_ SG_ 2395189505 DATC_SchdldVntMinSta "DATC_ScheduledVentilationMinutesStatus";
CM_ BO_ 1127 "[PE] Periodic and On Event";
CM_ SG_ 1127 DPSS_Crc1Val "DPSS_CyclicRedundancyCheck1Value";
CM_ SG_ 1127 DPSS_AlvCnt1Val "DPSS_AliveCounter1Value";
CM_ SG_ 1127 DPSS_StExtFwdMvBtn "DPSS_ExtensionForwardMoveButton";
CM_ SG_ 1127 DPSS_StExtBwdMvBtn "DPSS_ExtensionBackwardMoveButton";
CM_ SG_ 1127 DPSS_StSldFwdMvBtn "DPSS_SlideForwardMoveButton";
CM_ SG_ 1127 DPSS_StSldBwdMvBtn "DPSS_SlideBackwardMoveButton";
CM_ SG_ 1127 DPSS_StRclFwdMvBtn "DPSS_ReclinerForwardMoveButton";
CM_ SG_ 1127 DPSS_StRclBwdMvBtn "DPSS_ReclinerBackwardMoveButton";
CM_ SG_ 1127 DPSS_StHgtUpMvBtn "DPSS_HeightUpMoveButton";
CM_ SG_ 1127 DPSS_StHgtDnMvBtn "DPSS_HeightDownMoveButton";
CM_ SG_ 1127 DPSS_StTltUpMvBtn "DPSS_TiltUpMoveButton";
CM_ SG_ 1127 DPSS_StTltDnMvBtn "DPSS_TiltDownMoveButton";
CM_ SG_ 1127 DPSS_StHRestUpMvBtn "DPSS_StHRestUpMvBtn";
CM_ SG_ 1127 DPSS_StHRestDnMvBtn "DPSS_StHRestDnMvBtn";
CM_ SG_ 1127 DPSS_StHRestFwdMvBtn "DPSS_StHRestFwdMvBtn";
CM_ SG_ 1127 DPSS_StHRestBwdMvBtn "DPSS_StHRestBwdMvBtn";
CM_ SG_ 1127 DPSS_StLegUpMvBtn "DPSS_LegUpMoveButton";
CM_ SG_ 1127 DPSS_StLegDnMvBtn "DPSS_LegDownMoveButton";
CM_ SG_ 1127 DPSS_StRlxModeBtn "DPSS_RelaxModeButton";
CM_ SG_ 1127 DPSS_StRlxReturnBtn "DPSS_RelaxReturnButton";
CM_ SG_ 1127 DPSS_RlxStTltUpMvBtn "DPSS_RelaxTiltUpMoveButton";
CM_ SG_ 1127 DPSS_RlxStTltDnMvBtn "DPSS_RelaxTiltDownMoveButton";
CM_ BO_ 1128 "[PE] Periodic and On Event";
CM_ SG_ 1128 DPSS_Crc2Val "DPSS_CyclicRedundancyCheck2Value";
CM_ SG_ 1128 DPSS_AlvCnt2Val "DPSS_AliveCounter2Value";
CM_ SG_ 1128 DPSS_LumbarUpSw "DPSS_LumbarUpMoveSwitch";
CM_ SG_ 1128 DPSS_LumbarMidSw "DPSS_LumbarMiddleSwitch";
CM_ SG_ 1128 DPSS_LumbarLowSw "DPSS_LumbarLowerSwitch";
CM_ SG_ 1128 DPSS_LumbarDefSw "DPSS_LumbarDeflationSwitch";
CM_ SG_ 1128 DPSS_BolsterInfSw "DPSS_BolsterInflationSwitch";
CM_ SG_ 1128 DPSS_BolsterDefSw "DPSS_BolsterDeflationSwitch";
CM_ SG_ 1128 DPSS_ActiveSw "DPSS_ActiveSwitch";
CM_ SG_ 1128 DPSS_CushInfSw "DPSS_Cush Support Inflation Switch";
CM_ SG_ 1128 DPSS_CushDefSw "DPSS_Cush Support Deflation Switch";
CM_ BO_ 1129 "[PE] Periodic and On Event";
CM_ SG_ 1129 DPSS_Crc3Val "DPSS_CyclicRedundancyCheck3Value";
CM_ SG_ 1129 DPSS_AlvCnt3Val "DPSS_AliveCounter3Value";
CM_ SG_ 1129 DPSS_SldTch "DPSS_SlideTouch";
CM_ SG_ 1129 DPSS_RclTch "DPSS_ReclinerTouch";
CM_ SG_ 1129 DPSS_ExtTch "DPSS_ExtensionTouch";
CM_ SG_ 1129 DPSS_LmbrTch "DPSS_LumbarTouch";
CM_ SG_ 1129 DPSS_CushOnOffTch "DPSS_CushOnOffTouch";
CM_ SG_ 1129 DPSS_HRestTch "DPSS_HeadResetTouch";
CM_ BO_ 1105 "[PE] Periodic and On Event";
CM_ SG_ 1105 FCS_FrLftStClrSwSta "FCS_FrontLeftSeatCoolerSwitchStatus";
CM_ SG_ 1105 FCS_FrLftStHtrSwSta "FCS_FrontLeftSeatHeaterSwitchStatus";
CM_ SG_ 1105 FCS_FrRtStClrSwSta "FCS_FrontRightSeatCoolerSwitchStatus";
CM_ SG_ 1105 FCS_FrRtStHtrSwSta "FCS_FrontRightSeatHeaterSwitchStatus";
CM_ BO_ 2378399489 "[P] Periodic";
CM_ SG_ 2378399489 GATEWAY_CrcVal "GATEWAY_CyclicRedundancyCheckValue";
CM_ SG_ 2378399489 GATEWAY_AlvCntVal "GATEWAY_AliveCounterValue";
CM_ BO_ 2563128577 "[P] Periodic";
CM_ SG_ 2563128577 AMP_SetMaxMainVolStep "Command for Set AMP’s Main Volume max step";
CM_ BO_ 2315420673 "[EC] On Event and On Change";
CM_ BO_ 1150 "[EC] On Event and On Change";
CM_ SG_ 1150 IAU2FPM_EncryptedData1 "This signal is for a send enrypted result of IAU.";
CM_ BO_ 2449771009 "[P] Periodic";
CM_ SG_ 2449771009 ODS_Crc1Val "ODS_CyclicRedundancyCheck1Value";
CM_ SG_ 2449771009 ODS_AlvCnt1Val "ODS_AliveCounter1Value";
CM_ SG_ 2449771009 ODS_IdVal "ODS_IdValue ##2G##ODS - ODS13 - CR_Ods_ID";
CM_ SG_ 2449771009 ODS_OccClassSta "ODS_OccupantClassificationStatus ##2G##ODS - ODS11 - CR_Wcs_ClassStat";
CM_ SG_ 2449771009 ODS_DiagSta "ODS_SelfDiagnosticStatus ##2G##ODS - ODS11 - CR_Wcs_ErrStat";
CM_ SG_ 2449771009 ODS_SBRClassSta "ODS_SBRClassSta";
CM_ BO_ 2449771010 "[P] Periodic";
CM_ BO_ 1089 "[PE] Periodic and On Event";
CM_ SG_ 1089 PSM_RrRtSldStrtSta "PSM_RearRightSlidingStartStatus";
CM_ SG_ 1089 RRPSM_PersonalLmpOnReq "RL PERSONAL LAMP ON/OFF REQUEST";
CM_ SG_ 1089 RRPSM_APSMBzrOnReq "APSM buzzer on command";
CM_ SG_ 1089 RRPSM_LimSetSta "RRPSM  limit setting";
CM_ SG_ 1089 RRPSM_RRStEsyAcsUSMSta "USM_MovingValue";
CM_ SG_ 1089 RRPSM_LegSupportOpt "Leg Support Option Signal";
CM_ SG_ 1089 PSM_RearRightLegSpprtPosVal "PSM_RearRightLegSpportPositionValue";
CM_ BO_ 1107 "[PE] Periodic and On Event";
CM_ SG_ 1107 RR_SHVU_SeatOptSta "Rear RH Seat Heater/Vent option info";
CM_ SG_ 1107 RR_SHVU_HtAutoDownRVal "Rear RH Seat Heater AutoDown R Value";
CM_ SG_ 1107 RR_SHVU_VntTurboSta "Rear RH Seat Vent Turbo Mode Status";
CM_ SG_ 1107 RR_SHVU_SeatHtOperSta "Rear RH Seat Heater/Vent current operation state";
CM_ SG_ 1107 RR_SHVU_SeatOptSta_RHD "Rear RH Seat Heater/Vent option info";
CM_ SG_ 1107 RR_SHVU_SeatHtOperSta_RHD "Rear RH Seat Heater/Vent current operation state";
CM_ SG_ 1107 RR_SHVU_HtSwHiIndSta_RHD "Rear Right_Seat Heater Switch High Indicator Status";
CM_ SG_ 1107 RR_SHVU_HtSwMidIndSta_RHD "Rear Left_Seat Heater Switch Mid Indicator Status";
CM_ SG_ 1107 RR_SHVU_HtSwLowIndSta_RHD "Rear Right_Seat Heater Switch Low Indicator Status";
CM_ SG_ 1107 RR_SHVU_VntSwHiIndSta_RHD "Rear Right Seat Vent Switch High Indicator Status";
CM_ SG_ 1107 RR_SHVU_VntSwMidIndSta_RHD "Rear Right Seat Vent Switch Mid Indicator Status";
CM_ SG_ 1107 RR_SHVU_VntSwLowIndSta_RHD "Rear Right Seat Vent Switch Low Indicator Status";
CM_ SG_ 1107 RR_SHVU_SeatHtFail "Rear RH Seat Heater/Vent FailSafe State";
CM_ BO_ 1092 "[PE] Periodic and On Event";
CM_ SG_ 1092 SMK_Crc2Val "SMK_CyclicRedundancyCheck2Value";
CM_ SG_ 1092 SMK_AlvCnt2Val "SMK_AliveCounter2Value";
CM_ SG_ 1092 SSB_StrtStpBtnSw1Sta "SSB_StartStopButtonSwitch1Status ##2G##SMK - SMKmsg19 - C_SSBSW1";
CM_ SG_ 1092 SSB_StrtStpBtnSw2Sta "SSB_StartStopButtonSwitch2Status ##2G##SMK - SMKmsg19 - C_SSBSW2";
CM_ SG_ 1092 SMK_TrmnlCtrlSta "SMK_TerminalControlStatus ##2G##SMK - SMKmsg19 - C_TerminalControlState";
CM_ SG_ 1092 SMK_TrmnlMngrSta "SMK_TerminalManagerStatus ##2G##SMK - SMKmsg19 - C_TerminalsManagerState";
CM_ SG_ 1092 SMK_AuthSta "SMK_AuthentificationStatus ##2G##SMK - SMKmsg18 - C_AuthState";
CM_ SG_ 1092 SMK_Ign1InSta "SMK_Ign1InputStatus ##2G##SMK - SMKmsg19 - C_Ign1SMK";
CM_ SG_ 1092 SMK_Ign1RlySta "SMK_Ign1RelayStatus ##2G##SMK - SMKmsg19 - C_Ign1RelayState";
CM_ SG_ 1092 SMK_Ign2InSta "SMK_Ign2InputStatus ##2G##SMK - SMKmsg19 - C_Ign2SMK";
CM_ SG_ 1092 SMK_Ign2RlySta "SMK_Ign2RelayStatus ##2G##SMK - SMKmsg19 - C_Ign2RelayState";
CM_ SG_ 1092 SMK_StrtFdbckSta "SMK_StartFeedbackStatus ##2G##SMK - SMKmsg19 - C_StartFeedback";
CM_ SG_ 1092 SMK_StrtrRlyOutSta "SMK_StarterRelayOutputStatus ##2G##SMK - SMKmsg18 - C_StarterRlyState";
CM_ SG_ 1092 SMK_AccInSta "SMK_AccInputStatus ##2G##SMK - SMKmsg19 - C_AccSMK";
CM_ SG_ 1092 SMK_AccRlySta "SMK_AccRelayStatus ##2G##SMK - SMKmsg19 - C_AccRelayStatus";
CM_ SG_ 1092 SMK_CLUAccIndOnReq "SMK_ClusterACCIndicatorOnRequest ##2G##SMK - SMKmsg19 - C_AccINDforCLU";
CM_ SG_ 1092 SMK_TlEngRunSta "SMK_TeleEngineRunStatus ##2G##SMK - SMKmsg18 - C_SMKTeleEngineRunning";
CM_ SG_ 1092 SMK_TlCrnkModSta "SMK_TeleCrankingModeStatus ##2G##SMK - SMKmsg18 - C_SMKTeleCrankingState";
CM_ SG_ 1092 SMK_RmtKeyEngRunSta "SMK_RemoteKeyEngineRunStatus";
CM_ BO_ 1108 "[PE] Periodic and On Event";
CM_ SG_ 1108 SMK_Crc3Val "SMK_CyclicRedundancyCheck3Value";
CM_ SG_ 1108 SMK_AlvCnt3Val "SMK_AliveCounter3Value";
CM_ SG_ 1108 ESCL_EsclMngrSta "ESCL_EsclManagerStatus ##2G##SMK - SMKmsg19 - C_EsclManagerState";
CM_ SG_ 1108 ESCL_EsclPwrSupSta "ESCL_EsclPowerSupplyStatus ##2G##SMK - SMKmsg19 - C_EsclPowerSupplystatus";
CM_ SG_ 1108 ESCL_EsclEnaSta "ESCL_EsclEnableStatus ##2G##SMK - SMKmsg19 - C_EsclEnableStatus";
CM_ SG_ 1108 ESCL_EsclUnitSta "ESCL_EsclUnitStatus ##2G##SMK - SMKmsg19 - C_EsclUnitStatus";
CM_ SG_ 1108 ESCL_EsclBoltSta "ESCL_EsclBoltStatus ##2G##SMK - SMKmsg19 - C_EsclBoltStatus";
CM_ SG_ 1108 ESCL_EsclLoBattSta "ESCL_EsclLowBatteryStatus ##2G##SMK - SMKmsg19 - C_EsclLowBat";
CM_ SG_ 1108 ESCL_EsclUnLkSwSta "ESCL_UnLockSwitchStatus ##2G##SMK - SMKmsg19 - C_EsclUnlock";
CM_ BO_ 1093 "[PE] Periodic and On Event";
CM_ SG_ 1093 SMK_Crc6Val "SMK_CyclicRedundancyCheck6Value";
CM_ SG_ 1093 SMK_AlvCnt6Val "SMK_AliveCounter6Value";
CM_ SG_ 1093 Lamp_HzrdBlnkngSta "Lamp_HazardBlinkingStatus ##2G##SMK - SMKmsg17 - C_HazardFromSMK";
CM_ SG_ 1093 Lamp_SmrtWlcmLtOnReq "Lamp_SmartWelcomeLightOnRequest ##2G##SMK - SMKmsg17 - C_WlightOn";
CM_ SG_ 1093 Fob_BattStaInfo "Fob_BatteryStatusInformation ##2G##SMK - SMKmsg17 - C_FOBBatteryStatusInfo";
CM_ SG_ 1093 Fob_FoundDrvWlcmArea "Fob_FoundDriverWelcomeArea ##2G##SMK - SMKmsg17 - C_WelcomeFobFoundDrv";
CM_ SG_ 1093 Fob_FoundAsstWlcmArea "Fob_FoundAssistWelcomeArea ##2G##SMK - SMKmsg17 - C_WelcomeFobFoundAst";
CM_ SG_ 1093 Fob_FoundExtrnlArea "Fob_FoundExternalArea ##2G##SMK - SMKmsg18 - C_ExtFobPos";
CM_ SG_ 1093 Fob_FoundIntArea "Fob_FoundInternalArea ##2G##SMK - SMKmsg18 - C_IntFobPos";
CM_ SG_ 1093 Fob_LearntSta "Fob_LearntStatus ##2G##SMK - SMKmsg18 - C_FobLearntState";
CM_ SG_ 1093 RSPA_RFSigErrSta "RSPA_RFSignalErrorState";
CM_ SG_ 1093 RSPA_CanErrSta "RSPA_CANErrorState";
CM_ SG_ 1093 LFAnt_FltSta "LFAntenna_FaultSatus ##2G##SMK - SMKmsg18 - C_LFANTState";
CM_ SG_ 1093 LFAnt_SrchSta "LFAntenna_SearchingStatus ##2G##SMK - SMKmsg19 - C_LFSearchingOn";
CM_ SG_ 1093 Auth_ISKLearnSta "Fob_FoundAssistWelcomeArea ##2G##SMK - SMKmsg178 - C_IBUISKLearnState";
CM_ SG_ 1093 RSPA_ModSta_SMK "RSPA_ModeStatus ##2G##SMK - SMKmsg18 - C_SMKRSPAMode";
CM_ SG_ 1093 RSPA_FobBattSta "RSPA_FobBatteryStatus ##2G##SMK - SMKmsg18 - C_FobBATState";
CM_ SG_ 1093 USM_SmrtTrnkTlgtModSta "USM_SmartTunkTailgateModeStatus ##2G##SMK - SMKmsg20 - C_HfreeTrunkTgRValue";
CM_ SG_ 1093 USM_WALModSta "USM_WalkAwayLockModeStatus ##2G##SMK - SMKmsg20 - C_WALRValue";
CM_ SG_ 1093 Fob_FoundWlcmArea "Fob_FoundWlcmArea ##2G##SMK - SMKmsg17 -C_FobFoundWlcmArea";
BA_DEF_ BO_ "DiagState" ENUM "No","Yes" ;
BA_DEF_ BO_ "DiagResponse" ENUM "No","Yes" ;
BA_DEF_ BO_ "DiagRequest" ENUM "No","Yes" ;
BA_DEF_ BO_ "TpMessage" ENUM "No","Yes" ;
BA_DEF_ BO_ "UsrMsgIDSforwardDeviation" INT 0 100 ;
BA_DEF_ BO_ "UsrMsgIDSbackwardDeviation" INT 50 1000 ;
BA_DEF_ "BusType" STRING ;
BA_DEF_ "DBName" STRING ;
BA_DEF_ "Baudrate" INT 50000 1000000 ;
BA_DEF_ "GenEnvVarEndingDsp" STRING ;
BA_DEF_ "GenEnvVarEndingSnd" STRING ;
BA_DEF_ "GenEnvVarPrefix" STRING ;
BA_DEF_ "GenNWMApBusSleep" STRING ;
BA_DEF_ "GenNWMApCanNormal" STRING ;
BA_DEF_ "GenNWMApCanOff" STRING ;
BA_DEF_ "GenNWMApCanOn" STRING ;
BA_DEF_ "GenNWMApCanSleep" STRING ;
BA_DEF_ "GenNWMApCanWakeUp" STRING ;
BA_DEF_ "GenNWMGotoMode_Awake" STRING ;
BA_DEF_ "GenNWMGotoMode_BusSleep" STRING ;
BA_DEF_ "GenNWMSleepTime" INT 1375 1650 ;
BA_DEF_ "GenNWMTalkNM" STRING ;
BA_DEF_ "Manufacturer" STRING ;
BA_DEF_ "NmBaseAddress" HEX 0 2047 ;
BA_DEF_ "NmMessageCount" INT 0 128 ;
BA_DEF_ "NmType" STRING ;
BA_DEF_ "SamplePointMax" INT 50 85 ;
BA_DEF_ "SamplePointMin" INT 55 85 ;
BA_DEF_ "SyncJumpWidthMax" INT 1 8 ;
BA_DEF_ "SyncJumpWidthMin" INT 1 4 ;
BA_DEF_ "VersionDay" INT 1 31 ;
BA_DEF_ "VersionMonth" INT 1 12 ;
BA_DEF_ "VersionNumber" INT 0 999999 ;
BA_DEF_ "VersionNumberInternal" INT 0 9999 ;
BA_DEF_ "VersionWeek" INT 1 53 ;
BA_DEF_ "VersionYear" INT 0 9999 ;
BA_DEF_ BU_ "NmStationAddress" HEX 0 127 ;
BA_DEF_ BU_ "NmNode" ENUM "No","Yes" ;
BA_DEF_ BU_ "GenNodSleepTime" INT 1375 1650 ;
BA_DEF_ BU_ "ILUsed" ENUM "No","Yes" ;
BA_DEF_ BU_ "NmCAN" INT 1 2 ;
BA_DEF_ BU_ "NodeLayerModules" STRING ;
BA_DEF_ BU_ "NWM_Knoten" ENUM "No","Yes" ;
BA_DEF_ BO_ "GenMsgCycleTime" INT 0 2000 ;
BA_DEF_ BO_ "GenMsgStartDelayTime" INT 0 2000 ;
BA_DEF_ BO_ "GenMsgSendType" ENUM "Cyclic","NoMsgSendType" ;
BA_DEF_ BO_ "GenMsgCycleTimeFast" INT 0 500 ;
BA_DEF_ BO_ "GenMsgDelayTime" INT 0 20 ;
BA_DEF_ BO_ "GenMsgILSupport" ENUM "No","Yes" ;
BA_DEF_ BO_ "GenMsgNrOfRepetition" INT 0 3 ;
BA_DEF_ BO_ "NmMessage" ENUM "No","Yes" ;
BA_DEF_ BO_ "NWM-Botschaft" ENUM "No","Yes" ;
BA_DEF_ BO_ "TpTxIndex" INT 0 255 ;
BA_DEF_ BO_ "VFrameFormat" ENUM "StandardCAN","ExtendedCAN","reserved","reserved","reserved","reserved","reserved","reserved","reserved","reserved","reserved","reserved","reserved","reserved","StandardCAN_FD","ExtendedCAN_FD" ;
BA_DEF_ SG_ "UserSigValidity" ENUM "B+","ACC","IG","IG1","IG2","IG3","IG1 or IG2","IG1 or IG3","Undef" ;
BA_DEF_ SG_ "TimeoutValue" STRING ;
BA_DEF_ SG_ "UsrSigPurpose" ENUM "Undef","FN","DIAG","DIAG(Req)","DIAG(Res)","DIAG(Phy)","DEV","CCP(Req)","CCP(Res)","NM","TP" ;
BA_DEF_ SG_ "GenSigStartValue" INT 0 1215752192 ;
BA_DEF_ SG_ "NetworkRequest" ENUM "Yes","No" ;
BA_DEF_ SG_ "NetworkRequestHoldingTime" INT 0 65535 ;
BA_DEF_ SG_ "Description" STRING ;
BA_DEF_ SG_ "Version" STRING ;
BA_DEF_ SG_ "GenSigEnvVarType" ENUM "Int","Float","Undef" ;
BA_DEF_ SG_ "GenSigSendType" ENUM "Cyclic","OnWrite","OnWriteWithRepetition","OnChange","OnChangeWithRepetition","IfActive","IfActiveWithRepetition","NoSigSendType","OnChangeAndIfActive","OnChangeAndIfActiveWithRepetition" ;
BA_DEF_ SG_ "GwSigLatencyTime" INT 0 65536 ;
BA_DEF_ SG_ "GwSigMissingSourceType" ENUM "Undef","OldValue","DefaultValue","InitialValue" ;
BA_DEF_ SG_ "NWM-WakeupAllowed" ENUM "<n.a.>" ;
BA_DEF_ SG_ "RoutingFactor" INT 1 1215752192 ;
BA_DEF_REL_ BU_SG_REL_ "GenSigTimeoutTime" INT 0 7000 ;
BA_DEF_DEF_ "DiagState" "No" ;
BA_DEF_DEF_ "DiagResponse" "No" ;
BA_DEF_DEF_ "DiagRequest" "No" ;
BA_DEF_DEF_ "TpMessage" "No" ;
BA_DEF_DEF_ "UsrMsgIDSforwardDeviation" 10 ;
BA_DEF_DEF_ "UsrMsgIDSbackwardDeviation" 100 ;
BA_DEF_DEF_ "BusType" "CAN" ;
BA_DEF_DEF_ "DBName" "" ;
BA_DEF_DEF_ "Baudrate" 500000 ;
BA_DEF_DEF_ "GenEnvVarEndingDsp" "Dsp_" ;
BA_DEF_DEF_ "GenEnvVarEndingSnd" "_" ;
BA_DEF_DEF_ "GenEnvVarPrefix" "Env" ;
BA_DEF_DEF_ "GenNWMApBusSleep" "AppNmCanBusSleep()" ;
BA_DEF_DEF_ "GenNWMApCanNormal" "AppNmCanNormal()" ;
BA_DEF_DEF_ "GenNWMApCanOff" "ApplCanOffline()" ;
BA_DEF_DEF_ "GenNWMApCanOn" "ApplCanOnline()" ;
BA_DEF_DEF_ "GenNWMApCanSleep" "ApplNmCanSleep()" ;
BA_DEF_DEF_ "GenNWMApCanWakeUp" "ApplCanWakeUp()" ;
BA_DEF_DEF_ "GenNWMGotoMode_Awake" "GotoMode_Awake()" ;
BA_DEF_DEF_ "GenNWMGotoMode_BusSleep" "GotoMode_BusSleep()" ;
BA_DEF_DEF_ "GenNWMSleepTime" 1500 ;
BA_DEF_DEF_ "GenNWMTalkNM" "TalkNM()" ;
BA_DEF_DEF_ "Manufacturer" "HMC" ;
BA_DEF_DEF_ "NmBaseAddress" 1280 ;
BA_DEF_DEF_ "NmMessageCount" 128 ;
BA_DEF_DEF_ "NmType" "Vector" ;
BA_DEF_DEF_ "SamplePointMax" 80 ;
BA_DEF_DEF_ "SamplePointMin" 80 ;
BA_DEF_DEF_ "SyncJumpWidthMax" 3 ;
BA_DEF_DEF_ "SyncJumpWidthMin" 2 ;
BA_DEF_DEF_ "VersionDay" 1 ;
BA_DEF_DEF_ "VersionMonth" 1 ;
BA_DEF_DEF_ "VersionNumber" 0 ;
BA_DEF_DEF_ "VersionNumberInternal" 0 ;
BA_DEF_DEF_ "VersionWeek" 1 ;
BA_DEF_DEF_ "VersionYear" 0 ;
BA_DEF_DEF_ "NmStationAddress" 0 ;
BA_DEF_DEF_ "NmNode" "Yes" ;
BA_DEF_DEF_ "GenNodSleepTime" 1500 ;
BA_DEF_DEF_ "ILUsed" "Yes" ;
BA_DEF_DEF_ "NmCAN" 1 ;
BA_DEF_DEF_ "NodeLayerModules" "oseknm01.dll,CANoeILNLVector.dll" ;
BA_DEF_DEF_ "NWM_Knoten" "Yes" ;
BA_DEF_DEF_ "GenMsgCycleTime" 200 ;
BA_DEF_DEF_ "GenMsgStartDelayTime" 0 ;
BA_DEF_DEF_ "GenMsgSendType" "NoMsgSendType" ;
BA_DEF_DEF_ "GenMsgCycleTimeFast" 40 ;
BA_DEF_DEF_ "GenMsgDelayTime" 20 ;
BA_DEF_DEF_ "GenMsgILSupport" "Yes" ;
BA_DEF_DEF_ "GenMsgNrOfRepetition" 3 ;
BA_DEF_DEF_ "NmMessage" "No" ;
BA_DEF_DEF_ "NWM-Botschaft" "No" ;
BA_DEF_DEF_ "TpTxIndex" 0 ;
BA_DEF_DEF_ "VFrameFormat" "StandardCAN" ;
BA_DEF_DEF_ "UserSigValidity" "IG" ;
BA_DEF_DEF_ "TimeoutValue" "" ;
BA_DEF_DEF_ "UsrSigPurpose" "FN" ;
BA_DEF_DEF_ "GenSigStartValue" 0 ;
BA_DEF_DEF_ "NetworkRequest" "No" ;
BA_DEF_DEF_ "NetworkRequestHoldingTime" 0 ;
BA_DEF_DEF_ "Description" "" ;
BA_DEF_DEF_ "Version" "" ;
BA_DEF_DEF_ "GenSigEnvVarType" "Undef" ;
BA_DEF_DEF_ "GenSigSendType" "NoSigSendType" ;
BA_DEF_DEF_ "GwSigLatencyTime" 40 ;
BA_DEF_DEF_ "GwSigMissingSourceType" "Undef" ;
BA_DEF_DEF_ "NWM-WakeupAllowed" "<n.a.>" ;
BA_DEF_DEF_ "RoutingFactor" 1 ;
BA_DEF_DEF_REL_ "GenSigTimeoutTime" 500 ;
BA_ "DBName" "CAN";
BA_ "VersionYear" 1;
BA_ "VersionNumber" 210903;
BA_ "NmStationAddress" BU_ CGW_CCU 112;
BA_ "NmStationAddress" BU_ APSM 9;
BA_ "NmStationAddress" BU_ ATS 80;
BA_ "NmStationAddress" BU_ PSM 6;
BA_ "NmStationAddress" BU_ RLPSM 28;
BA_ "NmStationAddress" BU_ RRPSM 29;
BA_ "NmStationAddress" BU_ AMP 96;
BA_ "GenMsgSendType" BO_ 2223057409 0;
BA_ "GenMsgCycleTime" BO_ 2223057409 10;
BA_ "GenMsgCycleTimeFast" BO_ 2223057409 0;
BA_ "GenMsgNrOfRepetition" BO_ 2223057409 0;
BA_ "GenMsgDelayTime" BO_ 2223057409 0;
BA_ "VFrameFormat" BO_ 2223057409 1;
BA_ "Description" SG_ 2223057409 ADAS_CMD_Crc30Val "The data area for CRC calculation is based on the data length (DLC) of the message DB.

The CRC shall be calculated over the entire data block (excluding the CRC bytes) including the user data, alive counter and Data ID

 

- CRC Polynomial (0x1021) , Initial Value : 0xFFFF, XOR value : 0x0000, Data ID : Message ID + 0xF800 

- The initial value is for CRC calculation and the message should be sent with the calculated result value. 

- The mathematical expression to 16 bit CRC polynomial is given here. G(x) = x16 + x12 + x5 + 1";
BA_ "GenSigStartValue" SG_ 2223057409 ADAS_CMD_Crc30Val 65535;
BA_ "UserSigValidity" SG_ 2223057409 ADAS_CMD_Crc30Val 3;
BA_ "RoutingFactor" SG_ 2223057409 ADAS_CMD_Crc30Val 5;
BA_ "Version" SG_ 2223057409 ADAS_CMD_Crc30Val "18.11.08";
BA_ "Description" SG_ 2223057409 ADAS_CMD_AlvCnt30Val "For the first transmission request for a data element the counter shall be initialized with 0 and shall be incremented by 1 for every subsequent send request. 

When the counter reaches the maximum value(0xFF), then it shall restart with 0 for the next send request";
BA_ "UserSigValidity" SG_ 2223057409 ADAS_CMD_AlvCnt30Val 3;
BA_ "RoutingFactor" SG_ 2223057409 ADAS_CMD_AlvCnt30Val 5;
BA_ "Version" SG_ 2223057409 ADAS_CMD_AlvCnt30Val "18.11.08";
BA_ "UserSigValidity" SG_ 2223057409 LKA_OptUsmSta 3;
BA_ "RoutingFactor" SG_ 2223057409 LKA_OptUsmSta 5;
BA_ "Version" SG_ 2223057409 LKA_OptUsmSta "17.12.02";
BA_ "UserSigValidity" SG_ 2223057409 LKA_RcgSta 3;
BA_ "RoutingFactor" SG_ 2223057409 LKA_RcgSta 5;
BA_ "Version" SG_ 2223057409 LKA_RcgSta "18.10.12";
BA_ "NmStationAddress" BU_ DSAU 89;
BA_ "UserSigValidity" SG_ 2223057409 LKA_LHLnWrnSta 3;
BA_ "RoutingFactor" SG_ 2223057409 LKA_LHLnWrnSta 5;
BA_ "Version" SG_ 2223057409 LKA_LHLnWrnSta "19.02.05";
BA_ "UserSigValidity" SG_ 2223057409 LKA_RHLnWrnSta 3;
BA_ "RoutingFactor" SG_ 2223057409 LKA_RHLnWrnSta 5;
BA_ "Version" SG_ 2223057409 LKA_RHLnWrnSta "19.02.05";
BA_ "UserSigValidity" SG_ 2223057409 LKA_HndsoffSnd 3;
BA_ "RoutingFactor" SG_ 2223057409 LKA_HndsoffSnd 5;
BA_ "Version" SG_ 2223057409 LKA_HndsoffSnd "17.12.02";
BA_ "UserSigValidity" SG_ 2223057409 LKA_SysIndReq 3;
BA_ "RoutingFactor" SG_ 2223057409 LKA_SysIndReq 5;
BA_ "Version" SG_ 2223057409 LKA_SysIndReq "17.12.02";
BA_ "Description" SG_ 2223057409 ADAS_StrTqReqVal "This is the driver torque overlay demand value. A negative value represents a torque that would accelerate the steering wheel in a clockwise direction. This signal is always zero whilst the TOI is inactive.";
BA_ "GenSigStartValue" SG_ 2223057409 ADAS_StrTqReqVal 1024;
BA_ "UserSigValidity" SG_ 2223057409 ADAS_StrTqReqVal 3;
BA_ "RoutingFactor" SG_ 2223057409 ADAS_StrTqReqVal 5;
BA_ "Version" SG_ 2223057409 ADAS_StrTqReqVal "21.01.08";
BA_ "Description" SG_ 2223057409 ADAS_ActToiSta "This is a flag that is set to 1 when requesting the steering to activate the torque overlay interface (TOI).  This must be done before an attempt is made to request non-zero steering torque overlay.";
BA_ "UserSigValidity" SG_ 2223057409 ADAS_ActToiSta 3;
BA_ "RoutingFactor" SG_ 2223057409 ADAS_ActToiSta 5;
BA_ "Version" SG_ 2223057409 ADAS_ActToiSta "21.01.08";
BA_ "Description" SG_ 2223057409 ADAS_ToiFltSta "This fault flag is set when a fault in the LKA system has been detected by the LKA ECU such that LKA can no longer function. CAN failures, internal video ECU failures, hard-wired component (e.g. master switch) failures and other system logic failures are all reported by this flag. Failures reported by the MDPS are not looped back through this flag.";
BA_ "UserSigValidity" SG_ 2223057409 ADAS_ToiFltSta 3;
BA_ "RoutingFactor" SG_ 2223057409 ADAS_ToiFltSta 5;
BA_ "Version" SG_ 2223057409 ADAS_ToiFltSta "18.12.07";
BA_ "Description" SG_ 2223057409 LKA_SysWrn "A signal that provides additional information on the operation of the LKA system for the HMI to display to the driver. This includes additional fault information, reasons for unavailability of the system and additional warnings like the hands-off warning. Some of the information may be displayed for short periods, whilst others like the hands-off warning may be displayed for longer periods.";
BA_ "UserSigValidity" SG_ 2223057409 LKA_SysWrn 3;
BA_ "RoutingFactor" SG_ 2223057409 LKA_SysWrn 5;
BA_ "Version" SG_ 2223057409 LKA_SysWrn "18.10.09";
BA_ "GenMsgSendType" BO_ 2223057410 0;
BA_ "GenMsgCycleTime" BO_ 2223057410 10;
BA_ "GenMsgCycleTimeFast" BO_ 2223057410 0;
BA_ "GenMsgNrOfRepetition" BO_ 2223057410 0;
BA_ "GenMsgDelayTime" BO_ 2223057410 0;
BA_ "VFrameFormat" BO_ 2223057410 1;
BA_ "Description" SG_ 2223057410 FCA_LO_WrnSta "This signal indicates FCA-LO warning for display and sound.";
BA_ "UserSigValidity" SG_ 2223057410 FCA_LO_WrnSta 3;
BA_ "RoutingFactor" SG_ 2223057410 FCA_LO_WrnSta 5;
BA_ "Version" SG_ 2223057410 FCA_LO_WrnSta "17.11.00";
BA_ "Description" SG_ 2223057410 LKA_UsmMod "This signal indicates LKA USM Mode";
BA_ "UserSigValidity" SG_ 2223057410 LKA_UsmMod 3;
BA_ "RoutingFactor" SG_ 2223057410 LKA_UsmMod 5;
BA_ "Version" SG_ 2223057410 LKA_UsmMod "19.05.00";
BA_ "Description" SG_ 2223057410 ELK_SysFlrSta "ELK 작동 제한, 고장 팝업 신호";
BA_ "UserSigValidity" SG_ 2223057410 ELK_SysFlrSta 3;
BA_ "RoutingFactor" SG_ 2223057410 ELK_SysFlrSta 5;
BA_ "Version" SG_ 2223057410 ELK_SysFlrSta "20.09.00";
BA_ "Description" SG_ 2223057410 ELK_SymbDisp "This signal describes warning symbol about ELK system (FCA-LO/LS, w/ ESA).";
BA_ "UserSigValidity" SG_ 2223057410 ELK_SymbDisp 3;
BA_ "RoutingFactor" SG_ 2223057410 ELK_SymbDisp 5;
BA_ "Version" SG_ 2223057410 ELK_SymbDisp "20.12.04";
BA_ "Description" SG_ 2223057410 FCA_ESA_WrnSta "FCA w/ ESA HMI";
BA_ "UserSigValidity" SG_ 2223057410 FCA_ESA_WrnSta 3;
BA_ "RoutingFactor" SG_ 2223057410 FCA_ESA_WrnSta 5;
BA_ "Version" SG_ 2223057410 FCA_ESA_WrnSta "18.08.06";
BA_ "Description" SG_ 2223057410 ADAS_ActAciSta "State for angle control";
BA_ "UserSigValidity" SG_ 2223057410 ADAS_ActAciSta 3;
BA_ "RoutingFactor" SG_ 2223057410 ADAS_ActAciSta 5;
BA_ "Version" SG_ 2223057410 ADAS_ActAciSta "21.04.02";
BA_ "Description" SG_ 2223057410 FCA_ESA_CtrlSta "FCA w/ ESA Control Status for ECS Control";
BA_ "UserSigValidity" SG_ 2223057410 FCA_ESA_CtrlSta 3;
BA_ "RoutingFactor" SG_ 2223057410 FCA_ESA_CtrlSta 5;
BA_ "Version" SG_ 2223057410 FCA_ESA_CtrlSta "18.10.00";
BA_ "Description" SG_ 2223057410 FCA_LS_WrnSta "This signal indicates FCA-LS warning for display and sound.";
BA_ "UserSigValidity" SG_ 2223057410 FCA_LS_WrnSta 3;
BA_ "RoutingFactor" SG_ 2223057410 FCA_LS_WrnSta 5;
BA_ "Version" SG_ 2223057410 FCA_LS_WrnSta "17.11.00";
BA_ "Description" SG_ 2223057410 ADAS_Damping_Gain "ADAS Damping Gain for MDPS";
BA_ "GenSigStartValue" SG_ 2223057410 ADAS_Damping_Gain 100;
BA_ "UserSigValidity" SG_ 2223057410 ADAS_Damping_Gain 3;
BA_ "RoutingFactor" SG_ 2223057410 ADAS_Damping_Gain 5;
BA_ "Version" SG_ 2223057410 ADAS_Damping_Gain "18.12.01";
BA_ "Description" SG_ 2223057410 ADAS_StrAngReqVal "Request angle control value";
BA_ "UserSigValidity" SG_ 2223057410 ADAS_StrAngReqVal 3;
BA_ "RoutingFactor" SG_ 2223057410 ADAS_StrAngReqVal 5;
BA_ "Version" SG_ 2223057410 ADAS_StrAngReqVal "19.08.05";
BA_ "GenMsgSendType" BO_ 2260843009 0;
BA_ "GenMsgCycleTime" BO_ 2260843009 150;
BA_ "GenMsgCycleTimeFast" BO_ 2260843009 0;
BA_ "GenMsgNrOfRepetition" BO_ 2260843009 0;
BA_ "VFrameFormat" BO_ 2260843009 1;
BA_ "Description" SG_ 2260843009 ADAS_CMD_Crc50Val "The data area for CRC calculation is based on the data length (DLC) of the message DB.

The CRC shall be calculated over the entire data block (excluding the CRC bytes) including the user data, alive counter and Data ID

 

- CRC Polynomial (0x1021) , Initial Value : 0xFFFF, XOR value : 0x0000, Data ID : Message ID + 0xF800 

- The initial value is for CRC calculation and the message should be sent with the calculated result value. 

- The mathematical expression to 16 bit CRC polynomial is given here. G(x) = x16 + x12 + x5 + 1";
BA_ "GenSigStartValue" SG_ 2260843009 ADAS_CMD_Crc50Val 65535;
BA_ "UserSigValidity" SG_ 2260843009 ADAS_CMD_Crc50Val 3;
BA_ "RoutingFactor" SG_ 2260843009 ADAS_CMD_Crc50Val 3;
BA_ "Version" SG_ 2260843009 ADAS_CMD_Crc50Val "20.04.02";
BA_ "Description" SG_ 2260843009 ADAS_CMD_AlvCnt50Val "For the first transmission request for a data element the counter shall be initialized with 0 and shall be incremented by 1 for every subsequent send request. 

When the counter reaches the maximum value(0xFF), then it shall restart with 0 for the next send request";
BA_ "UserSigValidity" SG_ 2260843009 ADAS_CMD_AlvCnt50Val 3;
BA_ "RoutingFactor" SG_ 2260843009 ADAS_CMD_AlvCnt50Val 3;
BA_ "Version" SG_ 2260843009 ADAS_CMD_AlvCnt50Val "20.04.02";
BA_ "Description" SG_ 2260843009 BCW_Sta "This signal indicates the status of BCW";
BA_ "UserSigValidity" SG_ 2260843009 BCW_Sta 3;
BA_ "RoutingFactor" SG_ 2260843009 BCW_Sta 3;
BA_ "Version" SG_ 2260843009 BCW_Sta "20.03.06";
BA_ "Description" SG_ 2260843009 BCW_LtIndSta "This signal Indicates BCW Warning Indicator mode for Left side";
BA_ "UserSigValidity" SG_ 2260843009 BCW_LtIndSta 3;
BA_ "RoutingFactor" SG_ 2260843009 BCW_LtIndSta 3;
BA_ "Version" SG_ 2260843009 BCW_LtIndSta "21.01.08";
BA_ "Description" SG_ 2260843009 BCW_RtIndSta "This signal Indicates BCW Warning Indicator mode for Right side";
BA_ "UserSigValidity" SG_ 2260843009 BCW_RtIndSta 3;
BA_ "RoutingFactor" SG_ 2260843009 BCW_RtIndSta 3;
BA_ "Version" SG_ 2260843009 BCW_RtIndSta "21.01.08";
BA_ "Description" SG_ 2260843009 BCW_LtSndWrngSta "This signal indicates BCW Sound Warning for Front Left Speaker";
BA_ "UserSigValidity" SG_ 2260843009 BCW_LtSndWrngSta 3;
BA_REL_ "GenSigTimeoutTime" BU_SG_REL_ AMP SG_ 2260843009 BCW_LtSndWrngSta 1500;
BA_ "RoutingFactor" SG_ 2260843009 BCW_LtSndWrngSta 3;
BA_ "Version" SG_ 2260843009 BCW_LtSndWrngSta "20.03.06";
BA_ "Description" SG_ 2260843009 BCW_RtSndWrngSta "This signal indicates BCW Sound Warning for Front Right Speaker";
BA_ "UserSigValidity" SG_ 2260843009 BCW_RtSndWrngSta 3;
BA_REL_ "GenSigTimeoutTime" BU_SG_REL_ AMP SG_ 2260843009 BCW_RtSndWrngSta 1500;
BA_ "RoutingFactor" SG_ 2260843009 BCW_RtSndWrngSta 3;
BA_ "Version" SG_ 2260843009 BCW_RtSndWrngSta "20.03.06";
BA_ "Description" SG_ 2260843009 BCW_SnstvtyModRetVal "This signal indicates the selected sensitive mode of BCW warning";
BA_ "UserSigValidity" SG_ 2260843009 BCW_SnstvtyModRetVal 3;
BA_ "RoutingFactor" SG_ 2260843009 BCW_SnstvtyModRetVal 3;
BA_ "Version" SG_ 2260843009 BCW_SnstvtyModRetVal "20.03.06";
BA_ "Description" SG_ 2260843009 BCW_IndSta "OS Mirror Indicator Failure";
BA_ "UserSigValidity" SG_ 2260843009 BCW_IndSta 3;
BA_ "RoutingFactor" SG_ 2260843009 BCW_IndSta 3;
BA_ "Version" SG_ 2260843009 BCW_IndSta "20.03.06";
BA_ "GenMsgSendType" BO_ 2260843010 0;
BA_ "GenMsgCycleTime" BO_ 2260843010 150;
BA_ "GenMsgCycleTimeFast" BO_ 2260843010 0;
BA_ "GenMsgNrOfRepetition" BO_ 2260843010 0;
BA_ "VFrameFormat" BO_ 2260843010 1;
BA_ "Description" SG_ 2260843010 BCA_Sta "This signal indicates the status of BCA";
BA_ "UserSigValidity" SG_ 2260843010 BCA_Sta 3;
BA_ "RoutingFactor" SG_ 2260843010 BCA_Sta 3;
BA_ "Version" SG_ 2260843010 BCA_Sta "20.03.06";
BA_ "Description" SG_ 2260843010 BCA_DRV_WarnSta "This signal indicate the warning status for BCA-R with Differential Brake";
BA_ "UserSigValidity" SG_ 2260843010 BCA_DRV_WarnSta 3;
BA_ "RoutingFactor" SG_ 2260843010 BCA_DRV_WarnSta 3;
BA_ "Version" SG_ 2260843010 BCA_DRV_WarnSta "20.09.00";
BA_ "Description" SG_ 2260843010 BCA_Plus_Deccel_Req "This value is defined the time to stop the vehicle.





(PH) = 0.04 * (Hex)g";
BA_ "UserSigValidity" SG_ 2260843010 BCA_Plus_Deccel_Req 3;
BA_ "RoutingFactor" SG_ 2260843010 BCA_Plus_Deccel_Req 3;
BA_ "Version" SG_ 2260843010 BCA_Plus_Deccel_Req "20.03.06";
BA_ "Description" SG_ 2260843010 BCA_Plus_BrkCmdSta "BCA_Plus Function Brake Command";
BA_ "UserSigValidity" SG_ 2260843010 BCA_Plus_BrkCmdSta 3;
BA_ "RoutingFactor" SG_ 2260843010 BCA_Plus_BrkCmdSta 3;
BA_ "Version" SG_ 2260843010 BCA_Plus_BrkCmdSta "20.03.06";
BA_ "Description" SG_ 2260843010 BCA_Plus_LtWrngSta "This signal Indicates BCA_Plus Warning state for HMI(Cluster)";
BA_ "UserSigValidity" SG_ 2260843010 BCA_Plus_LtWrngSta 3;
BA_ "RoutingFactor" SG_ 2260843010 BCA_Plus_LtWrngSta 3;
BA_ "Version" SG_ 2260843010 BCA_Plus_LtWrngSta "20.03.06";
BA_ "Description" SG_ 2260843010 BCA_Plus_RtWrngSta "This signal Indicates BCA_Plus Warning state for HMI";
BA_ "UserSigValidity" SG_ 2260843010 BCA_Plus_RtWrngSta 3;
BA_ "RoutingFactor" SG_ 2260843010 BCA_Plus_RtWrngSta 3;
BA_ "Version" SG_ 2260843010 BCA_Plus_RtWrngSta "20.03.06";
BA_ "Description" SG_ 2260843010 BCA_OnOffEquipSta "This signal indicates the on/off status of BCA";
BA_ "UserSigValidity" SG_ 2260843010 BCA_OnOffEquipSta 3;
BA_ "RoutingFactor" SG_ 2260843010 BCA_OnOffEquipSta 3;
BA_ "Version" SG_ 2260843010 BCA_OnOffEquipSta "20.03.06";
BA_ "GenMsgSendType" BO_ 2260843011 0;
BA_ "GenMsgCycleTime" BO_ 2260843011 150;
BA_ "GenMsgCycleTimeFast" BO_ 2260843011 0;
BA_ "GenMsgNrOfRepetition" BO_ 2260843011 0;
BA_ "VFrameFormat" BO_ 2260843011 1;
BA_ "Description" SG_ 2260843011 OSMrrLamp_LtIndSta "This signal indicates the on/off status of BCA";
BA_ "UserSigValidity" SG_ 2260843011 OSMrrLamp_LtIndSta 3;
BA_ "RoutingFactor" SG_ 2260843011 OSMrrLamp_LtIndSta 3;
BA_ "Version" SG_ 2260843011 OSMrrLamp_LtIndSta "20.08.07";
BA_ "Description" SG_ 2260843011 OSMrrLamp_RtIndSta "This signal indicates the on/off status of BCA";
BA_ "UserSigValidity" SG_ 2260843011 OSMrrLamp_RtIndSta 3;
BA_ "RoutingFactor" SG_ 2260843011 OSMrrLamp_RtIndSta 3;
BA_ "Version" SG_ 2260843011 OSMrrLamp_RtIndSta "20.08.07";
BA_ "NmNode" BU_ vHS_M 0;
BA_ "NmStationAddress" BU_ ASAU 83;
BA_ "GenMsgSendType" BO_ 1100 0;
BA_ "GenSigSendType" SG_ 1100 APSM_LegRestCloseSta 4;
BA_ "UserSigValidity" SG_ 1100 APSM_LegRestCloseSta 0;
BA_REL_ "GenSigTimeoutTime" BU_SG_REL_ RRPSM SG_ 1100 APSM_LegRestCloseSta 1500;
BA_ "NetworkRequest" SG_ 1100 APSM_LegRestCloseSta 0;
BA_ "NetworkRequestHoldingTime" SG_ 1100 APSM_LegRestCloseSta 5000;
BA_ "Version" SG_ 1100 APSM_LegRestCloseSta "21.07.05";
BA_ "Description" SG_ 1100 APSM_ReadingModeState "APSM move state for Reading Mode";
BA_ "GenSigSendType" SG_ 1100 APSM_ReadingModeState 4;
BA_ "UserSigValidity" SG_ 1100 APSM_ReadingModeState 0;
BA_REL_ "GenSigTimeoutTime" BU_SG_REL_ RRPSM SG_ 1100 APSM_ReadingModeState 1500;
BA_ "NetworkRequest" SG_ 1100 APSM_ReadingModeState 0;
BA_ "NetworkRequestHoldingTime" SG_ 1100 APSM_ReadingModeState 5000;
BA_ "Version" SG_ 1100 APSM_ReadingModeState "21.08.04";
BA_ "GenSigSendType" SG_ 1100 APSM_CoveringMirrorPosition 4;
BA_ "UserSigValidity" SG_ 1100 APSM_CoveringMirrorPosition 0;
BA_REL_ "GenSigTimeoutTime" BU_SG_REL_ CGW_CCU SG_ 1100 APSM_CoveringMirrorPosition 1500;
BA_ "NetworkRequest" SG_ 1100 APSM_CoveringMirrorPosition 0;
BA_ "NetworkRequestHoldingTime" SG_ 1100 APSM_CoveringMirrorPosition 5000;
BA_ "Version" SG_ 1100 APSM_CoveringMirrorPosition "21.01.03";
BA_ "NmStationAddress" BU_ APSS 66;
BA_ "GenMsgCycleTime" BO_ 1095 0;
BA_ "Description" SG_ 1095 ATS_BeepSound "ATS to AMP BEEP sound trigger";
BA_ "GenSigSendType" SG_ 1095 ATS_BeepSound 4;
BA_ "UserSigValidity" SG_ 1095 ATS_BeepSound 3;
BA_REL_ "GenSigTimeoutTime" BU_SG_REL_ AMP SG_ 1095 ATS_BeepSound 0;
BA_ "RoutingFactor" SG_ 1095 ATS_BeepSound 0;
BA_ "Version" SG_ 1095 ATS_BeepSound "20.03.00";
BA_ "Description" SG_ 1095 ATS_RRMsgTimeSW "Rear Right Massage Time Button";
BA_ "GenSigSendType" SG_ 1095 ATS_RRMsgTimeSW 4;
BA_ "UserSigValidity" SG_ 1095 ATS_RRMsgTimeSW 3;
BA_REL_ "GenSigTimeoutTime" BU_SG_REL_ RLPSM SG_ 1095 ATS_RRMsgTimeSW 0;
BA_REL_ "GenSigTimeoutTime" BU_SG_REL_ RRPSM SG_ 1095 ATS_RRMsgTimeSW 0;
BA_ "RoutingFactor" SG_ 1095 ATS_RRMsgTimeSW 0;
BA_ "Version" SG_ 1095 ATS_RRMsgTimeSW "20.07.01";
BA_ "Description" SG_ 1095 ATS_FAUMsgModeSW "Rear Right Foot Massage Mode Button";
BA_ "GenSigSendType" SG_ 1095 ATS_FAUMsgModeSW 4;
BA_ "UserSigValidity" SG_ 1095 ATS_FAUMsgModeSW 3;
BA_REL_ "GenSigTimeoutTime" BU_SG_REL_ APSM SG_ 1095 ATS_FAUMsgModeSW 0;
BA_REL_ "GenSigTimeoutTime" BU_SG_REL_ ASAU SG_ 1095 ATS_FAUMsgModeSW 0;
BA_REL_ "GenSigTimeoutTime" BU_SG_REL_ RLPSM SG_ 1095 ATS_FAUMsgModeSW 0;
BA_REL_ "GenSigTimeoutTime" BU_SG_REL_ RRPSM SG_ 1095 ATS_FAUMsgModeSW 0;
BA_ "RoutingFactor" SG_ 1095 ATS_FAUMsgModeSW 0;
BA_ "Version" SG_ 1095 ATS_FAUMsgModeSW "20.07.01";
BA_ "Description" SG_ 1095 ATS_FAUMsgHeatModeSW "Rear Right Foot Massage Heat Mode Button";
BA_ "GenSigSendType" SG_ 1095 ATS_FAUMsgHeatModeSW 4;
BA_ "UserSigValidity" SG_ 1095 ATS_FAUMsgHeatModeSW 3;
BA_REL_ "GenSigTimeoutTime" BU_SG_REL_ APSM SG_ 1095 ATS_FAUMsgHeatModeSW 0;
BA_REL_ "GenSigTimeoutTime" BU_SG_REL_ ASAU SG_ 1095 ATS_FAUMsgHeatModeSW 0;
BA_REL_ "GenSigTimeoutTime" BU_SG_REL_ RLPSM SG_ 1095 ATS_FAUMsgHeatModeSW 0;
BA_REL_ "GenSigTimeoutTime" BU_SG_REL_ RRPSM SG_ 1095 ATS_FAUMsgHeatModeSW 0;
BA_ "RoutingFactor" SG_ 1095 ATS_FAUMsgHeatModeSW 0;
BA_ "Version" SG_ 1095 ATS_FAUMsgHeatModeSW "20.07.01";
BA_ "Description" SG_ 1095 ATS_RLMsgMod1SW "Rear Left Massage Mode 1 Button";
BA_ "GenSigSendType" SG_ 1095 ATS_RLMsgMod1SW 4;
BA_ "UserSigValidity" SG_ 1095 ATS_RLMsgMod1SW 3;
BA_REL_ "GenSigTimeoutTime" BU_SG_REL_ RLPSM SG_ 1095 ATS_RLMsgMod1SW 0;
BA_ "RoutingFactor" SG_ 1095 ATS_RLMsgMod1SW 0;
BA_ "Version" SG_ 1095 ATS_RLMsgMod1SW "20.12.05";
BA_ "NmStationAddress" BU_ RWPC 31;
BA_ "Description" SG_ 1095 ATS_RWPC_RWPCNValueSet "Rear Wireless Phone Charger ON/OFF Request";
BA_ "GenSigSendType" SG_ 1095 ATS_RWPC_RWPCNValueSet 4;
BA_ "UserSigValidity" SG_ 1095 ATS_RWPC_RWPCNValueSet 3;
BA_REL_ "GenSigTimeoutTime" BU_SG_REL_ RWPC SG_ 1095 ATS_RWPC_RWPCNValueSet 0;
BA_ "RoutingFactor" SG_ 1095 ATS_RWPC_RWPCNValueSet 0;
BA_ "Version" SG_ 1095 ATS_RWPC_RWPCNValueSet "20.03.00";
BA_ "Description" SG_ 1095 ATS_RLMsgMod2SW "Rear Left Massage Mode 2 Button";
BA_ "GenSigSendType" SG_ 1095 ATS_RLMsgMod2SW 4;
BA_ "UserSigValidity" SG_ 1095 ATS_RLMsgMod2SW 3;
BA_REL_ "GenSigTimeoutTime" BU_SG_REL_ RLPSM SG_ 1095 ATS_RLMsgMod2SW 0;
BA_ "RoutingFactor" SG_ 1095 ATS_RLMsgMod2SW 0;
BA_ "Version" SG_ 1095 ATS_RLMsgMod2SW "20.12.05";
BA_ "Description" SG_ 1095 ATS_RLMsgMod3SW "Rear Left Massage Mode 3 Button";
BA_ "GenSigSendType" SG_ 1095 ATS_RLMsgMod3SW 4;
BA_ "UserSigValidity" SG_ 1095 ATS_RLMsgMod3SW 3;
BA_REL_ "GenSigTimeoutTime" BU_SG_REL_ RLPSM SG_ 1095 ATS_RLMsgMod3SW 0;
BA_ "RoutingFactor" SG_ 1095 ATS_RLMsgMod3SW 0;
BA_ "Version" SG_ 1095 ATS_RLMsgMod3SW "20.12.05";
BA_ "Description" SG_ 1095 ATS_RLMsgMod4SW "Rear Left Massage Mode 4 Button";
BA_ "GenSigSendType" SG_ 1095 ATS_RLMsgMod4SW 4;
BA_ "UserSigValidity" SG_ 1095 ATS_RLMsgMod4SW 3;
BA_REL_ "GenSigTimeoutTime" BU_SG_REL_ RLPSM SG_ 1095 ATS_RLMsgMod4SW 0;
BA_ "RoutingFactor" SG_ 1095 ATS_RLMsgMod4SW 0;
BA_ "Version" SG_ 1095 ATS_RLMsgMod4SW "20.12.05";
BA_ "Description" SG_ 1095 ATS_RRMsgMod1SW "Rear Right Massage Mode 1 Button";
BA_ "GenSigSendType" SG_ 1095 ATS_RRMsgMod1SW 4;
BA_ "UserSigValidity" SG_ 1095 ATS_RRMsgMod1SW 3;
BA_REL_ "GenSigTimeoutTime" BU_SG_REL_ RLPSM SG_ 1095 ATS_RRMsgMod1SW 0;
BA_ "RoutingFactor" SG_ 1095 ATS_RRMsgMod1SW 0;
BA_ "Version" SG_ 1095 ATS_RRMsgMod1SW "20.12.05";
BA_ "Description" SG_ 1095 ATS_RRMsgMod2SW "Rear Right Massage Mode 2 Button";
BA_ "GenSigSendType" SG_ 1095 ATS_RRMsgMod2SW 4;
BA_ "UserSigValidity" SG_ 1095 ATS_RRMsgMod2SW 3;
BA_REL_ "GenSigTimeoutTime" BU_SG_REL_ RLPSM SG_ 1095 ATS_RRMsgMod2SW 0;
BA_ "RoutingFactor" SG_ 1095 ATS_RRMsgMod2SW 0;
BA_ "Version" SG_ 1095 ATS_RRMsgMod2SW "20.12.05";
BA_ "Description" SG_ 1095 ATS_RRMsgMod3SW "Rear Right Massage Mode 3 Button";
BA_ "GenSigSendType" SG_ 1095 ATS_RRMsgMod3SW 4;
BA_ "UserSigValidity" SG_ 1095 ATS_RRMsgMod3SW 3;
BA_REL_ "GenSigTimeoutTime" BU_SG_REL_ RLPSM SG_ 1095 ATS_RRMsgMod3SW 0;
BA_ "RoutingFactor" SG_ 1095 ATS_RRMsgMod3SW 0;
BA_ "Version" SG_ 1095 ATS_RRMsgMod3SW "20.12.05";
BA_ "Description" SG_ 1095 ATS_RRMsgMod4SW "Rear Right Massage Mode 4 Button";
BA_ "GenSigSendType" SG_ 1095 ATS_RRMsgMod4SW 4;
BA_ "UserSigValidity" SG_ 1095 ATS_RRMsgMod4SW 3;
BA_REL_ "GenSigTimeoutTime" BU_SG_REL_ RLPSM SG_ 1095 ATS_RRMsgMod4SW 0;
BA_ "RoutingFactor" SG_ 1095 ATS_RRMsgMod4SW 0;
BA_ "Version" SG_ 1095 ATS_RRMsgMod4SW "20.12.05";
BA_ "Description" SG_ 1095 ATS_RLEasyAccessSW "ATS touch command for seat easy access (For Rear Left)";
BA_ "GenSigSendType" SG_ 1095 ATS_RLEasyAccessSW 4;
BA_ "UserSigValidity" SG_ 1095 ATS_RLEasyAccessSW 3;
BA_REL_ "GenSigTimeoutTime" BU_SG_REL_ RLPSM SG_ 1095 ATS_RLEasyAccessSW 0;
BA_ "RoutingFactor" SG_ 1095 ATS_RLEasyAccessSW 0;
BA_ "Version" SG_ 1095 ATS_RLEasyAccessSW "20.05.02";
BA_ "Description" SG_ 1095 ATS_RREasyAccessSW "ATS touch command for seat easy access (For Rear Right)";
BA_ "GenSigSendType" SG_ 1095 ATS_RREasyAccessSW 4;
BA_ "UserSigValidity" SG_ 1095 ATS_RREasyAccessSW 3;
BA_REL_ "GenSigTimeoutTime" BU_SG_REL_ RRPSM SG_ 1095 ATS_RREasyAccessSW 0;
BA_ "RoutingFactor" SG_ 1095 ATS_RREasyAccessSW 0;
BA_ "Version" SG_ 1095 ATS_RREasyAccessSW "20.05.02";
BA_ "Description" SG_ 1095 ATS_RLMsgTimeSW "Rear Left Massage Time Button";
BA_ "GenSigSendType" SG_ 1095 ATS_RLMsgTimeSW 4;
BA_ "UserSigValidity" SG_ 1095 ATS_RLMsgTimeSW 3;
BA_REL_ "GenSigTimeoutTime" BU_SG_REL_ RLPSM SG_ 1095 ATS_RLMsgTimeSW 0;
BA_REL_ "GenSigTimeoutTime" BU_SG_REL_ RRPSM SG_ 1095 ATS_RLMsgTimeSW 0;
BA_ "RoutingFactor" SG_ 1095 ATS_RLMsgTimeSW 0;
BA_ "Version" SG_ 1095 ATS_RLMsgTimeSW "20.07.01";
BA_ "GenMsgSendType" BO_ 527 0;
BA_ "Description" SG_ 527 ATS_DrvStRseFwdBtn "운전석 모니터 각도 조절 전방 이동";
BA_ "GenSigSendType" SG_ 527 ATS_DrvStRseFwdBtn 4;
BA_ "UserSigValidity" SG_ 527 ATS_DrvStRseFwdBtn 3;
BA_REL_ "GenSigTimeoutTime" BU_SG_REL_ PSM SG_ 527 ATS_DrvStRseFwdBtn 1500;
BA_ "NetworkRequest" SG_ 527 ATS_DrvStRseFwdBtn 0;
BA_ "NetworkRequestHoldingTime" SG_ 527 ATS_DrvStRseFwdBtn 5000;
BA_ "Version" SG_ 527 ATS_DrvStRseFwdBtn "19.09.02";
BA_ "Description" SG_ 527 ATS_DrvStRseBwdBtn "운전석 모니터 각도 조절 후방 이동";
BA_ "GenSigSendType" SG_ 527 ATS_DrvStRseBwdBtn 4;
BA_ "UserSigValidity" SG_ 527 ATS_DrvStRseBwdBtn 3;
BA_REL_ "GenSigTimeoutTime" BU_SG_REL_ PSM SG_ 527 ATS_DrvStRseBwdBtn 1500;
BA_ "NetworkRequest" SG_ 527 ATS_DrvStRseBwdBtn 0;
BA_ "NetworkRequestHoldingTime" SG_ 527 ATS_DrvStRseBwdBtn 5000;
BA_ "Version" SG_ 527 ATS_DrvStRseBwdBtn "19.09.02";
BA_ "Description" SG_ 527 ATS_RRRestModBtn "후석 RH REST 모드 작동";
BA_ "GenSigSendType" SG_ 527 ATS_RRRestModBtn 4;
BA_ "UserSigValidity" SG_ 527 ATS_RRRestModBtn 3;
BA_REL_ "GenSigTimeoutTime" BU_SG_REL_ APSM SG_ 527 ATS_RRRestModBtn 1500;
BA_REL_ "GenSigTimeoutTime" BU_SG_REL_ RRPSM SG_ 527 ATS_RRRestModBtn 1500;
BA_ "NetworkRequest" SG_ 527 ATS_RRRestModBtn 0;
BA_ "NetworkRequestHoldingTime" SG_ 527 ATS_RRRestModBtn 5000;
BA_ "Version" SG_ 527 ATS_RRRestModBtn "19.09.02";
BA_ "Description" SG_ 527 ATS_RRResetModBtn "후석 RH RETURN 모드 작동";
BA_ "GenSigSendType" SG_ 527 ATS_RRResetModBtn 4;
BA_ "UserSigValidity" SG_ 527 ATS_RRResetModBtn 3;
BA_REL_ "GenSigTimeoutTime" BU_SG_REL_ APSM SG_ 527 ATS_RRResetModBtn 1500;
BA_REL_ "GenSigTimeoutTime" BU_SG_REL_ RRPSM SG_ 527 ATS_RRResetModBtn 1500;
BA_ "NetworkRequest" SG_ 527 ATS_RRResetModBtn 0;
BA_ "NetworkRequestHoldingTime" SG_ 527 ATS_RRResetModBtn 5000;
BA_ "Version" SG_ 527 ATS_RRResetModBtn "19.09.02";
BA_ "Description" SG_ 527 ATS_RRAvWtcModBtn "후석 RH AVN 모드 작동";
BA_ "GenSigSendType" SG_ 527 ATS_RRAvWtcModBtn 4;
BA_ "UserSigValidity" SG_ 527 ATS_RRAvWtcModBtn 3;
BA_REL_ "GenSigTimeoutTime" BU_SG_REL_ APSM SG_ 527 ATS_RRAvWtcModBtn 1500;
BA_REL_ "GenSigTimeoutTime" BU_SG_REL_ RRPSM SG_ 527 ATS_RRAvWtcModBtn 1500;
BA_ "NetworkRequest" SG_ 527 ATS_RRAvWtcModBtn 0;
BA_ "NetworkRequestHoldingTime" SG_ 527 ATS_RRAvWtcModBtn 5000;
BA_ "Version" SG_ 527 ATS_RRAvWtcModBtn "19.09.02";
BA_ "Description" SG_ 527 ATS_RRReadingModBtn "후석 RH READING 모드 작동";
BA_ "GenSigSendType" SG_ 527 ATS_RRReadingModBtn 4;
BA_ "UserSigValidity" SG_ 527 ATS_RRReadingModBtn 3;
BA_REL_ "GenSigTimeoutTime" BU_SG_REL_ APSM SG_ 527 ATS_RRReadingModBtn 1500;
BA_REL_ "GenSigTimeoutTime" BU_SG_REL_ RRPSM SG_ 527 ATS_RRReadingModBtn 1500;
BA_REL_ "GenSigTimeoutTime" BU_SG_REL_ CGW_CCU SG_ 527 ATS_RRReadingModBtn 1500;
BA_ "NetworkRequest" SG_ 527 ATS_RRReadingModBtn 0;
BA_ "NetworkRequestHoldingTime" SG_ 527 ATS_RRReadingModBtn 5000;
BA_ "Version" SG_ 527 ATS_RRReadingModBtn "19.09.02";
BA_ "Description" SG_ 527 ATS_RLRestModBtn "후석 LH REST 모드 작동";
BA_ "GenSigSendType" SG_ 527 ATS_RLRestModBtn 4;
BA_ "UserSigValidity" SG_ 527 ATS_RLRestModBtn 3;
BA_REL_ "GenSigTimeoutTime" BU_SG_REL_ PSM SG_ 527 ATS_RLRestModBtn 1500;
BA_REL_ "GenSigTimeoutTime" BU_SG_REL_ RLPSM SG_ 527 ATS_RLRestModBtn 1500;
BA_ "NetworkRequest" SG_ 527 ATS_RLRestModBtn 0;
BA_ "NetworkRequestHoldingTime" SG_ 527 ATS_RLRestModBtn 5000;
BA_ "Version" SG_ 527 ATS_RLRestModBtn "19.09.02";
BA_ "Description" SG_ 527 ATS_RLResetModBtn "후석 LH RETURN 모드 작동";
BA_ "GenSigSendType" SG_ 527 ATS_RLResetModBtn 4;
BA_ "UserSigValidity" SG_ 527 ATS_RLResetModBtn 3;
BA_REL_ "GenSigTimeoutTime" BU_SG_REL_ PSM SG_ 527 ATS_RLResetModBtn 1500;
BA_REL_ "GenSigTimeoutTime" BU_SG_REL_ RLPSM SG_ 527 ATS_RLResetModBtn 1500;
BA_ "NetworkRequest" SG_ 527 ATS_RLResetModBtn 0;
BA_ "NetworkRequestHoldingTime" SG_ 527 ATS_RLResetModBtn 5000;
BA_ "Version" SG_ 527 ATS_RLResetModBtn "19.09.02";
BA_ "NmStationAddress" BU_ RLHV 52;
BA_ "NmStationAddress" BU_ RRHV 53;
BA_ "NmStationAddress" BU_ RDC 47;
BA_ "NmStationAddress" BU_ SHVU_RR 43;
BA_ "NmStationAddress" BU_ DPSS 57;
BA_ "GenMsgSendType" BO_ 1090 0;
BA_ "Description" SG_ 1090 BCM_Crc12Val "The data area for CRC calculation is based on the data length (DLC) of the message DB.

The CRC shall be calculated over the entire data block (excluding the CRC bytes) including the user data, alive counter and Data ID 

 

- CRC Polynomial (0x1D) , Initial Value : 0x00, XOR value : 0xFF, Data ID Mode : Both, Data ID : Message ID + 0xF800 

- The initial value is for CRC calculation and the message should be sent with the calculated result value. 

The mathematical expression to 8 bit CRC polynomial is given here. G(x) = x8 + x4 + x3 + x2 + 1";
BA_ "GenSigSendType" SG_ 1090 BCM_Crc12Val 4;
BA_ "GenSigStartValue" SG_ 1090 BCM_Crc12Val 255;
BA_ "UserSigValidity" SG_ 1090 BCM_Crc12Val 0;
BA_ "Version" SG_ 1090 BCM_Crc12Val "18.11.08";
BA_ "Description" SG_ 1090 BCM_AlvCnt12Val "For the first transmission request for a data element the counter shall be initialized with 0 and shall be incremented by 1

for every subsequent send request. When the counter reaches the maximum value(0xE), then it shall restart with 0 for the next send request";
BA_ "GenSigSendType" SG_ 1090 BCM_AlvCnt12Val 4;
BA_ "UserSigValidity" SG_ 1090 BCM_AlvCnt12Val 0;
BA_ "Version" SG_ 1090 BCM_AlvCnt12Val "18.11.08";
BA_ "GenSigSendType" SG_ 1090 BCM_CntryConfgTyp 4;
BA_ "UserSigValidity" SG_ 1090 BCM_CntryConfgTyp 0;
BA_REL_ "GenSigTimeoutTime" BU_SG_REL_ RWPC SG_ 1090 BCM_CntryConfgTyp 1500;
BA_REL_ "GenSigTimeoutTime" BU_SG_REL_ PSM SG_ 1090 BCM_CntryConfgTyp 1500;
BA_REL_ "GenSigTimeoutTime" BU_SG_REL_ APSM SG_ 1090 BCM_CntryConfgTyp 1500;
BA_REL_ "GenSigTimeoutTime" BU_SG_REL_ RLPSM SG_ 1090 BCM_CntryConfgTyp 1500;
BA_REL_ "GenSigTimeoutTime" BU_SG_REL_ RRPSM SG_ 1090 BCM_CntryConfgTyp 1500;
BA_REL_ "GenSigTimeoutTime" BU_SG_REL_ SHVU_RR SG_ 1090 BCM_CntryConfgTyp 1500;
BA_REL_ "GenSigTimeoutTime" BU_SG_REL_ RDC SG_ 1090 BCM_CntryConfgTyp 1500;
BA_REL_ "GenSigTimeoutTime" BU_SG_REL_ DPSS SG_ 1090 BCM_CntryConfgTyp 1500;
BA_REL_ "GenSigTimeoutTime" BU_SG_REL_ APSS SG_ 1090 BCM_CntryConfgTyp 1500;
BA_REL_ "GenSigTimeoutTime" BU_SG_REL_ ATS SG_ 1090 BCM_CntryConfgTyp 1500;
BA_ "NetworkRequest" SG_ 1090 BCM_CntryConfgTyp 0;
BA_ "NetworkRequestHoldingTime" SG_ 1090 BCM_CntryConfgTyp 5000;
BA_ "Version" SG_ 1090 BCM_CntryConfgTyp "17.12.00";
BA_ "Description" SG_ 1090 BCM_SmkOptTyp "-(Old)C_PICOption";
BA_ "GenSigSendType" SG_ 1090 BCM_SmkOptTyp 4;
BA_ "UserSigValidity" SG_ 1090 BCM_SmkOptTyp 0;
BA_ "NetworkRequest" SG_ 1090 BCM_SmkOptTyp 0;
BA_ "NetworkRequestHoldingTime" SG_ 1090 BCM_SmkOptTyp 5000;
BA_ "Version" SG_ 1090 BCM_SmkOptTyp "17.12.00";
BA_ "Description" SG_ 1090 BCM_SunRoofOptTyp "Option Signal for Sunroof system

(C_SunroofOpt)";
BA_ "GenSigSendType" SG_ 1090 BCM_SunRoofOptTyp 4;
BA_ "UserSigValidity" SG_ 1090 BCM_SunRoofOptTyp 0;
BA_REL_ "GenSigTimeoutTime" BU_SG_REL_ AMP SG_ 1090 BCM_SunRoofOptTyp 1500;
BA_REL_ "GenSigTimeoutTime" BU_SG_REL_ ATS SG_ 1090 BCM_SunRoofOptTyp 1500;
BA_ "Version" SG_ 1090 BCM_SunRoofOptTyp "18.09.00";
BA_ "Description" SG_ 1090 BCM_SafetyWdwOptTyp "Option Signal for Safety Window system

(C_SafetyWDWOpt)";
BA_ "GenSigSendType" SG_ 1090 BCM_SafetyWdwOptTyp 4;
BA_ "UserSigValidity" SG_ 1090 BCM_SafetyWdwOptTyp 0;
BA_ "Version" SG_ 1090 BCM_SafetyWdwOptTyp "18.09.00";
BA_ "GenSigSendType" SG_ 1090 Window_DrvrSdWdwSta_BCM 4;
BA_ "UserSigValidity" SG_ 1090 Window_DrvrSdWdwSta_BCM 0;
BA_REL_ "GenSigTimeoutTime" BU_SG_REL_ AMP SG_ 1090 Window_DrvrSdWdwSta_BCM 1500;
BA_ "NetworkRequest" SG_ 1090 Window_DrvrSdWdwSta_BCM 0;
BA_ "NetworkRequestHoldingTime" SG_ 1090 Window_DrvrSdWdwSta_BCM 5000;
BA_ "Version" SG_ 1090 Window_DrvrSdWdwSta_BCM "17.12.00";
BA_ "Description" SG_ 1090 Window_AsstSdWdwSta_BCM "-(Old)C_AstWdwStat";
BA_ "GenSigSendType" SG_ 1090 Window_AsstSdWdwSta_BCM 4;
BA_ "UserSigValidity" SG_ 1090 Window_AsstSdWdwSta_BCM 0;
BA_REL_ "GenSigTimeoutTime" BU_SG_REL_ AMP SG_ 1090 Window_AsstSdWdwSta_BCM 1500;
BA_ "NetworkRequest" SG_ 1090 Window_AsstSdWdwSta_BCM 0;
BA_ "NetworkRequestHoldingTime" SG_ 1090 Window_AsstSdWdwSta_BCM 5000;
BA_ "Version" SG_ 1090 Window_AsstSdWdwSta_BCM "17.12.00";
BA_ "Description" SG_ 1090 Window_RrLftWdwSta_BCM "-(Old)C_RLWdwSta";
BA_ "GenSigSendType" SG_ 1090 Window_RrLftWdwSta_BCM 4;
BA_ "UserSigValidity" SG_ 1090 Window_RrLftWdwSta_BCM 0;
BA_REL_ "GenSigTimeoutTime" BU_SG_REL_ RDC SG_ 1090 Window_RrLftWdwSta_BCM 1500;
BA_REL_ "GenSigTimeoutTime" BU_SG_REL_ AMP SG_ 1090 Window_RrLftWdwSta_BCM 1500;
BA_REL_ "GenSigTimeoutTime" BU_SG_REL_ ATS SG_ 1090 Window_RrLftWdwSta_BCM 1500;
BA_ "NetworkRequest" SG_ 1090 Window_RrLftWdwSta_BCM 0;
BA_ "NetworkRequestHoldingTime" SG_ 1090 Window_RrLftWdwSta_BCM 5000;
BA_ "Version" SG_ 1090 Window_RrLftWdwSta_BCM "17.12.00";
BA_ "Description" SG_ 1090 Window_RrRtWdwSta_BCM "-(Old)C_RRWdwStat";
BA_ "GenSigSendType" SG_ 1090 Window_RrRtWdwSta_BCM 4;
BA_ "UserSigValidity" SG_ 1090 Window_RrRtWdwSta_BCM 0;
BA_REL_ "GenSigTimeoutTime" BU_SG_REL_ RDC SG_ 1090 Window_RrRtWdwSta_BCM 1500;
BA_REL_ "GenSigTimeoutTime" BU_SG_REL_ AMP SG_ 1090 Window_RrRtWdwSta_BCM 1500;
BA_REL_ "GenSigTimeoutTime" BU_SG_REL_ ATS SG_ 1090 Window_RrRtWdwSta_BCM 1500;
BA_ "NetworkRequest" SG_ 1090 Window_RrRtWdwSta_BCM 0;
BA_ "NetworkRequestHoldingTime" SG_ 1090 Window_RrRtWdwSta_BCM 5000;
BA_ "Version" SG_ 1090 Window_RrRtWdwSta_BCM "17.12.00";
BA_ "Description" SG_ 1090 SunRoof_GlassPosSta "This signal indicates Sunroof Glass Open/Close Status

(C_GlassPositionState)";
BA_ "GenSigSendType" SG_ 1090 SunRoof_GlassPosSta 4;
BA_ "GenSigStartValue" SG_ 1090 SunRoof_GlassPosSta 15;
BA_ "UserSigValidity" SG_ 1090 SunRoof_GlassPosSta 0;
BA_ "Version" SG_ 1090 SunRoof_GlassPosSta "18.09.00";
BA_ "Description" SG_ 1090 SunRoof_BlindPosSta "This signal indicates Sunroof Blind Open/Close Status

(C_BlindPositionState)";
BA_ "GenSigSendType" SG_ 1090 SunRoof_BlindPosSta 4;
BA_ "GenSigStartValue" SG_ 1090 SunRoof_BlindPosSta 15;
BA_ "UserSigValidity" SG_ 1090 SunRoof_BlindPosSta 0;
BA_ "Version" SG_ 1090 SunRoof_BlindPosSta "18.09.00";
BA_ "Description" SG_ 1090 SunRoof_GlassErrSta "This signal indicates Sunroof Glass error Status

(C_GlassErrorState)";
BA_ "GenSigSendType" SG_ 1090 SunRoof_GlassErrSta 4;
BA_ "UserSigValidity" SG_ 1090 SunRoof_GlassErrSta 0;
BA_ "Version" SG_ 1090 SunRoof_GlassErrSta "18.09.00";
BA_ "Description" SG_ 1090 SunRoof_BlindErrSta "This signal indicates Sunroof Blind error Status

(C_BlindErrorState)";
BA_ "GenSigSendType" SG_ 1090 SunRoof_BlindErrSta 4;
BA_ "UserSigValidity" SG_ 1090 SunRoof_BlindErrSta 0;
BA_ "Version" SG_ 1090 SunRoof_BlindErrSta "18.09.00";
BA_ "GenMsgSendType" BO_ 1098 0;
BA_ "Description" SG_ 1098 BCM_Crc14Val "The data area for CRC calculation is based on the data length (DLC) of the message DB.

The CRC shall be calculated over the entire data block (excluding the CRC bytes) including the user data, alive counter and Data ID 

 

- CRC Polynomial (0x1D) , Initial Value : 0x00, XOR value : 0xFF, Data ID Mode : Both, Data ID : Message ID + 0xF800 

- The initial value is for CRC calculation and the message should be sent with the calculated result value. 

The mathematical expression to 8 bit CRC polynomial is given here. G(x) = x8 + x4 + x3 + x2 + 1";
BA_ "GenSigSendType" SG_ 1098 BCM_Crc14Val 4;
BA_ "GenSigStartValue" SG_ 1098 BCM_Crc14Val 255;
BA_ "UserSigValidity" SG_ 1098 BCM_Crc14Val 0;
BA_ "Version" SG_ 1098 BCM_Crc14Val "18.11.08";
BA_ "Description" SG_ 1098 BCM_AlvCnt14Val "For the first transmission request for a data element the counter shall be initialized with 0 and shall be incremented by 1

for every subsequent send request. When the counter reaches the maximum value(0xE), then it shall restart with 0 for the next send request";
BA_ "GenSigSendType" SG_ 1098 BCM_AlvCnt14Val 4;
BA_ "UserSigValidity" SG_ 1098 BCM_AlvCnt14Val 0;
BA_ "Version" SG_ 1098 BCM_AlvCnt14Val "18.11.08";
BA_ "Description" SG_ 1098 Window_RrLftWdwSwSta_RrRt "Rear Left Window Switch Status from Rear Right Safety Power Window ECU";
BA_ "GenSigSendType" SG_ 1098 Window_RrLftWdwSwSta_RrRt 4;
BA_ "UserSigValidity" SG_ 1098 Window_RrLftWdwSwSta_RrRt 0;
BA_REL_ "GenSigTimeoutTime" BU_SG_REL_ RDC SG_ 1098 Window_RrLftWdwSwSta_RrRt 1500;
BA_ "NetworkRequest" SG_ 1098 Window_RrLftWdwSwSta_RrRt 0;
BA_ "NetworkRequestHoldingTime" SG_ 1098 Window_RrLftWdwSwSta_RrRt 5000;
BA_ "Version" SG_ 1098 Window_RrLftWdwSwSta_RrRt "19.11.04";
BA_ "Description" SG_ 1098 Window_RrRtWdwSwSta_RrLft "Rear Right Window Switch Status from Rear Left Safety Power Window ECU";
BA_ "GenSigSendType" SG_ 1098 Window_RrRtWdwSwSta_RrLft 4;
BA_ "UserSigValidity" SG_ 1098 Window_RrRtWdwSwSta_RrLft 0;
BA_REL_ "GenSigTimeoutTime" BU_SG_REL_ RDC SG_ 1098 Window_RrRtWdwSwSta_RrLft 1500;
BA_ "NetworkRequest" SG_ 1098 Window_RrRtWdwSwSta_RrLft 0;
BA_ "NetworkRequestHoldingTime" SG_ 1098 Window_RrRtWdwSwSta_RrLft 5000;
BA_ "Version" SG_ 1098 Window_RrRtWdwSwSta_RrLft "19.11.04";
BA_ "GenMsgSendType" BO_ 1124 0;
BA_ "Description" SG_ 1124 BCM_Crc15Val "The data area for CRC calculation is based on the data length (DLC) of the message DB.

The CRC shall be calculated over the entire data block (excluding the CRC bytes) including the user data, alive counter and Data ID 

 

- CRC Polynomial (0x1D) , Initial Value : 0x00, XOR value : 0xFF, Data ID Mode : Both, Data ID : Message ID + 0xF800 

- The initial value is for CRC calculation and the message should be sent with the calculated result value. 

The mathematical expression to 8 bit CRC polynomial is given here. G(x) = x8 + x4 + x3 + x2 + 1";
BA_ "GenSigSendType" SG_ 1124 BCM_Crc15Val 4;
BA_ "GenSigStartValue" SG_ 1124 BCM_Crc15Val 255;
BA_ "UserSigValidity" SG_ 1124 BCM_Crc15Val 0;
BA_ "Version" SG_ 1124 BCM_Crc15Val "18.11.08";
BA_ "Description" SG_ 1124 BCM_AlvCnt15Val "For the first transmission request for a data element the counter shall be initialized with 0 and shall be incremented by 1

for every subsequent send request. When the counter reaches the maximum value(0xE), then it shall restart with 0 for the next send request";
BA_ "GenSigSendType" SG_ 1124 BCM_AlvCnt15Val 4;
BA_ "UserSigValidity" SG_ 1124 BCM_AlvCnt15Val 0;
BA_ "Version" SG_ 1124 BCM_AlvCnt15Val "18.11.08";
BA_ "Description" SG_ 1124 Window_DrvrSdWdwActSta "This signal indicates DRV Window Action Status";
BA_ "GenSigSendType" SG_ 1124 Window_DrvrSdWdwActSta 4;
BA_ "GenSigStartValue" SG_ 1124 Window_DrvrSdWdwActSta 15;
BA_ "UserSigValidity" SG_ 1124 Window_DrvrSdWdwActSta 0;
BA_ "NetworkRequest" SG_ 1124 Window_DrvrSdWdwActSta 0;
BA_ "NetworkRequestHoldingTime" SG_ 1124 Window_DrvrSdWdwActSta 5000;
BA_ "Version" SG_ 1124 Window_DrvrSdWdwActSta "18.02.01";
BA_ "Description" SG_ 1124 Window_AsstSdWdwActSta "This signal indicates AST Window Action Status";
BA_ "GenSigSendType" SG_ 1124 Window_AsstSdWdwActSta 4;
BA_ "GenSigStartValue" SG_ 1124 Window_AsstSdWdwActSta 15;
BA_ "UserSigValidity" SG_ 1124 Window_AsstSdWdwActSta 0;
BA_ "NetworkRequest" SG_ 1124 Window_AsstSdWdwActSta 0;
BA_ "NetworkRequestHoldingTime" SG_ 1124 Window_AsstSdWdwActSta 5000;
BA_ "Version" SG_ 1124 Window_AsstSdWdwActSta "18.02.01";
BA_ "Description" SG_ 1124 Window_RrLftWdwActSta "This signal indicates RL Window Action Status";
BA_ "GenSigSendType" SG_ 1124 Window_RrLftWdwActSta 4;
BA_ "GenSigStartValue" SG_ 1124 Window_RrLftWdwActSta 15;
BA_ "UserSigValidity" SG_ 1124 Window_RrLftWdwActSta 0;
BA_ "NetworkRequest" SG_ 1124 Window_RrLftWdwActSta 0;
BA_ "NetworkRequestHoldingTime" SG_ 1124 Window_RrLftWdwActSta 5000;
BA_ "Version" SG_ 1124 Window_RrLftWdwActSta "18.02.01";
BA_ "Description" SG_ 1124 Window_RrRtWdwActSta "This signal indicates RR Window Action Status";
BA_ "GenSigSendType" SG_ 1124 Window_RrRtWdwActSta 4;
BA_ "GenSigStartValue" SG_ 1124 Window_RrRtWdwActSta 15;
BA_ "UserSigValidity" SG_ 1124 Window_RrRtWdwActSta 0;
BA_ "NetworkRequest" SG_ 1124 Window_RrRtWdwActSta 0;
BA_ "NetworkRequestHoldingTime" SG_ 1124 Window_RrRtWdwActSta 5000;
BA_ "Version" SG_ 1124 Window_RrRtWdwActSta "18.02.01";
BA_ "Description" SG_ 1124 Window_DrvrSdWdwDetailOpnSta "This signal indicates DRV Window Open/Close Detail Status";
BA_ "GenSigSendType" SG_ 1124 Window_DrvrSdWdwDetailOpnSta 4;
BA_ "GenSigStartValue" SG_ 1124 Window_DrvrSdWdwDetailOpnSta 7;
BA_ "UserSigValidity" SG_ 1124 Window_DrvrSdWdwDetailOpnSta 0;
BA_ "NetworkRequest" SG_ 1124 Window_DrvrSdWdwDetailOpnSta 0;
BA_ "NetworkRequestHoldingTime" SG_ 1124 Window_DrvrSdWdwDetailOpnSta 5000;
BA_ "Version" SG_ 1124 Window_DrvrSdWdwDetailOpnSta "18.02.01";
BA_ "Description" SG_ 1124 Window_AsstSdWdwDetailOpnSta "This signal indicates AST Window Open/Close Detail Status";
BA_ "GenSigSendType" SG_ 1124 Window_AsstSdWdwDetailOpnSta 4;
BA_ "GenSigStartValue" SG_ 1124 Window_AsstSdWdwDetailOpnSta 7;
BA_ "UserSigValidity" SG_ 1124 Window_AsstSdWdwDetailOpnSta 0;
BA_ "NetworkRequest" SG_ 1124 Window_AsstSdWdwDetailOpnSta 0;
BA_ "NetworkRequestHoldingTime" SG_ 1124 Window_AsstSdWdwDetailOpnSta 5000;
BA_ "Version" SG_ 1124 Window_AsstSdWdwDetailOpnSta "18.02.01";
BA_ "Description" SG_ 1124 Window_DrvrSdWdwErrAntPinch "The DRV Window state whether Calibrated or not";
BA_ "GenSigSendType" SG_ 1124 Window_DrvrSdWdwErrAntPinch 4;
BA_ "GenSigStartValue" SG_ 1124 Window_DrvrSdWdwErrAntPinch 1;
BA_ "UserSigValidity" SG_ 1124 Window_DrvrSdWdwErrAntPinch 0;
BA_ "NetworkRequest" SG_ 1124 Window_DrvrSdWdwErrAntPinch 0;
BA_ "NetworkRequestHoldingTime" SG_ 1124 Window_DrvrSdWdwErrAntPinch 5000;
BA_ "Version" SG_ 1124 Window_DrvrSdWdwErrAntPinch "18.02.01";
BA_ "Description" SG_ 1124 Window_RrLftWdwDetailOpnSta "This signal indicates RL Window Open/Close Detail Status";
BA_ "GenSigSendType" SG_ 1124 Window_RrLftWdwDetailOpnSta 4;
BA_ "GenSigStartValue" SG_ 1124 Window_RrLftWdwDetailOpnSta 7;
BA_ "UserSigValidity" SG_ 1124 Window_RrLftWdwDetailOpnSta 0;
BA_ "NetworkRequest" SG_ 1124 Window_RrLftWdwDetailOpnSta 0;
BA_ "NetworkRequestHoldingTime" SG_ 1124 Window_RrLftWdwDetailOpnSta 5000;
BA_ "Version" SG_ 1124 Window_RrLftWdwDetailOpnSta "18.02.01";
BA_ "Description" SG_ 1124 Window_RrRtWdwDetailOpnSta "This signal indicates RR Window Open/Close Detail Status";
BA_ "GenSigSendType" SG_ 1124 Window_RrRtWdwDetailOpnSta 4;
BA_ "GenSigStartValue" SG_ 1124 Window_RrRtWdwDetailOpnSta 7;
BA_ "UserSigValidity" SG_ 1124 Window_RrRtWdwDetailOpnSta 0;
BA_ "NetworkRequest" SG_ 1124 Window_RrRtWdwDetailOpnSta 0;
BA_ "NetworkRequestHoldingTime" SG_ 1124 Window_RrRtWdwDetailOpnSta 5000;
BA_ "Version" SG_ 1124 Window_RrRtWdwDetailOpnSta "18.02.01";
BA_ "Description" SG_ 1124 Window_AsstSdWdwErrAntPinch "The AST Window state whether Calibrated or not";
BA_ "GenSigSendType" SG_ 1124 Window_AsstSdWdwErrAntPinch 4;
BA_ "GenSigStartValue" SG_ 1124 Window_AsstSdWdwErrAntPinch 1;
BA_ "UserSigValidity" SG_ 1124 Window_AsstSdWdwErrAntPinch 0;
BA_ "NetworkRequest" SG_ 1124 Window_AsstSdWdwErrAntPinch 0;
BA_ "NetworkRequestHoldingTime" SG_ 1124 Window_AsstSdWdwErrAntPinch 5000;
BA_ "Version" SG_ 1124 Window_AsstSdWdwErrAntPinch "18.02.01";
BA_ "Description" SG_ 1124 Window_RrLftWdwErrAntPinch "The RL Window state whether Calibrated or not";
BA_ "GenSigSendType" SG_ 1124 Window_RrLftWdwErrAntPinch 4;
BA_ "GenSigStartValue" SG_ 1124 Window_RrLftWdwErrAntPinch 1;
BA_ "UserSigValidity" SG_ 1124 Window_RrLftWdwErrAntPinch 0;
BA_ "NetworkRequest" SG_ 1124 Window_RrLftWdwErrAntPinch 0;
BA_ "NetworkRequestHoldingTime" SG_ 1124 Window_RrLftWdwErrAntPinch 5000;
BA_ "Version" SG_ 1124 Window_RrLftWdwErrAntPinch "18.02.01";
BA_ "Description" SG_ 1124 Window_RrRtWdwErrAntPinch "The RR Window state whether Calibrated or not";
BA_ "GenSigSendType" SG_ 1124 Window_RrRtWdwErrAntPinch 4;
BA_ "GenSigStartValue" SG_ 1124 Window_RrRtWdwErrAntPinch 1;
BA_ "UserSigValidity" SG_ 1124 Window_RrRtWdwErrAntPinch 0;
BA_ "NetworkRequest" SG_ 1124 Window_RrRtWdwErrAntPinch 0;
BA_ "NetworkRequestHoldingTime" SG_ 1124 Window_RrRtWdwErrAntPinch 5000;
BA_ "Version" SG_ 1124 Window_RrRtWdwErrAntPinch "18.02.01";
BA_ "Description" SG_ 1124 SunRoof_RrBlindPosSta "This signal indicates Rear Sunroof Blind Open/Close Status";
BA_ "GenSigSendType" SG_ 1124 SunRoof_RrBlindPosSta 4;
BA_ "GenSigStartValue" SG_ 1124 SunRoof_RrBlindPosSta 15;
BA_ "UserSigValidity" SG_ 1124 SunRoof_RrBlindPosSta 0;
BA_REL_ "GenSigTimeoutTime" BU_SG_REL_ ATS SG_ 1124 SunRoof_RrBlindPosSta 1500;
BA_ "Version" SG_ 1124 SunRoof_RrBlindPosSta "20.01.01";
BA_ "Description" SG_ 1124 Window_RrLftWdwSwSta "Rear Left Window Switch Status from Rear Left Safety Power Window ECU";
BA_ "GenSigSendType" SG_ 1124 Window_RrLftWdwSwSta 4;
BA_ "UserSigValidity" SG_ 1124 Window_RrLftWdwSwSta 0;
BA_REL_ "GenSigTimeoutTime" BU_SG_REL_ RDC SG_ 1124 Window_RrLftWdwSwSta 1500;
BA_ "NetworkRequest" SG_ 1124 Window_RrLftWdwSwSta 0;
BA_ "NetworkRequestHoldingTime" SG_ 1124 Window_RrLftWdwSwSta 5000;
BA_ "Version" SG_ 1124 Window_RrLftWdwSwSta "18.03.04";
BA_ "Description" SG_ 1124 Window_RrRtWdwSwSta "Rear Right Window Switch Status from Rear RightSafety Power Window ECU";
BA_ "GenSigSendType" SG_ 1124 Window_RrRtWdwSwSta 4;
BA_ "UserSigValidity" SG_ 1124 Window_RrRtWdwSwSta 0;
BA_REL_ "GenSigTimeoutTime" BU_SG_REL_ RDC SG_ 1124 Window_RrRtWdwSwSta 1500;
BA_ "NetworkRequest" SG_ 1124 Window_RrRtWdwSwSta 0;
BA_ "NetworkRequestHoldingTime" SG_ 1124 Window_RrRtWdwSwSta 5000;
BA_ "Version" SG_ 1124 Window_RrRtWdwSwSta "18.03.04";
BA_ "NmStationAddress" BU_ FPM 79;
BA_ "NmStationAddress" BU_ ICC 87;
BA_ "GenMsgSendType" BO_ 2395189505 0;
BA_ "VFrameFormat" BO_ 2395189505 1;
BA_ "Description" SG_ 2395189505 DATC_Crc9Val "The data area for CRC calculation is based on the data length (DLC) of the message DB.

The CRC shall be calculated over the entire data block (excluding the CRC bytes) including the user data, alive counter and Data ID

 

- CRC Polynomial (0x1021) , Initial Value : 0xFFFF, XOR value : 0x0000, Data ID : Message ID + 0xF800 

- The initial value is for CRC calculation and the message should be sent with the calculated result value. 

- The mathematical expression to 16 bit CRC polynomial is given here. G(x) = x16 + x12 + x5 + 1";
BA_ "GenSigSendType" SG_ 2395189505 DATC_Crc9Val 4;
BA_ "GenSigStartValue" SG_ 2395189505 DATC_Crc9Val 65535;
BA_ "UserSigValidity" SG_ 2395189505 DATC_Crc9Val 3;
BA_ "Version" SG_ 2395189505 DATC_Crc9Val "18.11.08";
BA_ "Description" SG_ 2395189505 DATC_AlvCnt9Val "For the first transmission request for a data element the counter shall be initialized with 0 and shall be incremented by 1 for every subsequent send request. 

When the counter reaches the maximum value(0xFF), then it shall restart with 0 for the next send request";
BA_ "GenSigSendType" SG_ 2395189505 DATC_AlvCnt9Val 4;
BA_ "UserSigValidity" SG_ 2395189505 DATC_AlvCnt9Val 3;
BA_ "Version" SG_ 2395189505 DATC_AlvCnt9Val "18.11.08";
BA_ "GenSigSendType" SG_ 2395189505 DATC_RrBlwDis 4;
BA_ "UserSigValidity" SG_ 2395189505 DATC_RrBlwDis 7;
BA_REL_ "GenSigTimeoutTime" BU_SG_REL_ ATS SG_ 2395189505 DATC_RrBlwDis 1500;
BA_ "Version" SG_ 2395189505 DATC_RrBlwDis "19.05.04";
BA_ "Description" SG_ 2395189505 DATC_ArClnStepClr "This signal indicate the information about Color of AirCleaning Symbol displaying in the AVN";
BA_ "GenSigSendType" SG_ 2395189505 DATC_ArClnStepClr 4;
BA_ "UserSigValidity" SG_ 2395189505 DATC_ArClnStepClr 7;
BA_REL_ "GenSigTimeoutTime" BU_SG_REL_ ATS SG_ 2395189505 DATC_ArClnStepClr 1500;
BA_ "Version" SG_ 2395189505 DATC_ArClnStepClr "19.02.03";
BA_ "Description" SG_ 2395189505 DATC_ArClnSmblTyp "This signal indicate the feature of Air Cleaning Symbol displaying in AVN";
BA_ "GenSigSendType" SG_ 2395189505 DATC_ArClnSmblTyp 4;
BA_ "UserSigValidity" SG_ 2395189505 DATC_ArClnSmblTyp 7;
BA_REL_ "GenSigTimeoutTime" BU_SG_REL_ ATS SG_ 2395189505 DATC_ArClnSmblTyp 1500;
BA_ "Version" SG_ 2395189505 DATC_ArClnSmblTyp "18.12.08";
BA_ "Description" SG_ 2395189505 DATC_AfterBlowUSMSta "This signal indicate activation status of USM setting menu about After Blow.";
BA_ "GenSigSendType" SG_ 2395189505 DATC_AfterBlowUSMSta 4;
BA_ "UserSigValidity" SG_ 2395189505 DATC_AfterBlowUSMSta 7;
BA_ "Version" SG_ 2395189505 DATC_AfterBlowUSMSta "19.10.06";
BA_ "Description" SG_ 2395189505 DATC_SchdldVntUSMSta "This signal indicate activation status of USM setting menu about Scheduled Ventilation";
BA_ "GenSigSendType" SG_ 2395189505 DATC_SchdldVntUSMSta 4;
BA_ "UserSigValidity" SG_ 2395189505 DATC_SchdldVntUSMSta 7;
BA_ "Version" SG_ 2395189505 DATC_SchdldVntUSMSta "19.08.08";
BA_ "Description" SG_ 2395189505 DATC_SchdldVntHrSta "This signal indicates the value corresponding to 'hour' among the set time values of the scheduled ventilation USM";
BA_ "GenSigSendType" SG_ 2395189505 DATC_SchdldVntHrSta 4;
BA_ "UserSigValidity" SG_ 2395189505 DATC_SchdldVntHrSta 7;
BA_ "Version" SG_ 2395189505 DATC_SchdldVntHrSta "19.08.08";
BA_ "Description" SG_ 2395189505 DATC_SchdldVntMinSta "This signal indicates the value corresponding to 'minutes' among the set time values of the scheduled ventilation USM.";
BA_ "GenSigSendType" SG_ 2395189505 DATC_SchdldVntMinSta 4;
BA_ "UserSigValidity" SG_ 2395189505 DATC_SchdldVntMinSta 7;
BA_ "Version" SG_ 2395189505 DATC_SchdldVntMinSta "19.08.08";
BA_ "GenMsgSendType" BO_ 1127 0;
BA_ "Description" SG_ 1127 DPSS_Crc1Val "The data area for CRC calculation is based on the data length (DLC) of the message DB.

The CRC shall be calculated over the entire data block (excluding the CRC bytes) including the user data, alive counter and Data ID 

 

- CRC Polynomial (0x1D) , Initial Value : 0x00, XOR value : 0xFF, Data ID Mode : Both, Data ID : Message ID + 0xF800 

- The initial value is for CRC calculation and the message should be sent with the calculated result value. 

The mathematical expression to 8 bit CRC polynomial is given here. G(x) = x8 + x4 + x3 + x2 + 1";
BA_ "GenSigSendType" SG_ 1127 DPSS_Crc1Val 4;
BA_ "GenSigStartValue" SG_ 1127 DPSS_Crc1Val 255;
BA_ "UserSigValidity" SG_ 1127 DPSS_Crc1Val 0;
BA_REL_ "GenSigTimeoutTime" BU_SG_REL_ PSM SG_ 1127 DPSS_Crc1Val 1500;
BA_ "Version" SG_ 1127 DPSS_Crc1Val "19.01.01";
BA_ "Description" SG_ 1127 DPSS_AlvCnt1Val "For the first transmission request for a data element the counter shall be initialized with 0 and shall be incremented by 1

for every subsequent send request. When the counter reaches the maximum value(0xE), then it shall restart with 0 for the next send request";
BA_ "GenSigSendType" SG_ 1127 DPSS_AlvCnt1Val 4;
BA_ "UserSigValidity" SG_ 1127 DPSS_AlvCnt1Val 0;
BA_REL_ "GenSigTimeoutTime" BU_SG_REL_ PSM SG_ 1127 DPSS_AlvCnt1Val 1500;
BA_ "Version" SG_ 1127 DPSS_AlvCnt1Val "19.01.01";
BA_ "Description" SG_ 1127 DPSS_StExtFwdMvBtn "운전석 쿠션 익스텐션 포워드 버튼";
BA_ "GenSigSendType" SG_ 1127 DPSS_StExtFwdMvBtn 4;
BA_ "UserSigValidity" SG_ 1127 DPSS_StExtFwdMvBtn 0;
BA_REL_ "GenSigTimeoutTime" BU_SG_REL_ PSM SG_ 1127 DPSS_StExtFwdMvBtn 1500;
BA_ "NetworkRequest" SG_ 1127 DPSS_StExtFwdMvBtn 0;
BA_ "NetworkRequestHoldingTime" SG_ 1127 DPSS_StExtFwdMvBtn 5000;
BA_ "Version" SG_ 1127 DPSS_StExtFwdMvBtn "20.03.01";
BA_ "Description" SG_ 1127 DPSS_StExtBwdMvBtn "운전석 쿠션 익스텐션 백워드 버튼";
BA_ "GenSigSendType" SG_ 1127 DPSS_StExtBwdMvBtn 4;
BA_ "UserSigValidity" SG_ 1127 DPSS_StExtBwdMvBtn 0;
BA_REL_ "GenSigTimeoutTime" BU_SG_REL_ PSM SG_ 1127 DPSS_StExtBwdMvBtn 1500;
BA_ "NetworkRequest" SG_ 1127 DPSS_StExtBwdMvBtn 0;
BA_ "NetworkRequestHoldingTime" SG_ 1127 DPSS_StExtBwdMvBtn 5000;
BA_ "Version" SG_ 1127 DPSS_StExtBwdMvBtn "20.03.01";
BA_ "Description" SG_ 1127 DPSS_StSldFwdMvBtn "운전석 슬라이드 포워드 버튼";
BA_ "GenSigSendType" SG_ 1127 DPSS_StSldFwdMvBtn 4;
BA_ "UserSigValidity" SG_ 1127 DPSS_StSldFwdMvBtn 0;
BA_REL_ "GenSigTimeoutTime" BU_SG_REL_ PSM SG_ 1127 DPSS_StSldFwdMvBtn 1500;
BA_REL_ "GenSigTimeoutTime" BU_SG_REL_ RLPSM SG_ 1127 DPSS_StSldFwdMvBtn 1500;
BA_ "NetworkRequest" SG_ 1127 DPSS_StSldFwdMvBtn 0;
BA_ "NetworkRequestHoldingTime" SG_ 1127 DPSS_StSldFwdMvBtn 5000;
BA_ "Version" SG_ 1127 DPSS_StSldFwdMvBtn "20.03.01";
BA_ "Description" SG_ 1127 DPSS_StSldBwdMvBtn "운전석 슬라이드 백워드 버튼";
BA_ "GenSigSendType" SG_ 1127 DPSS_StSldBwdMvBtn 4;
BA_ "UserSigValidity" SG_ 1127 DPSS_StSldBwdMvBtn 0;
BA_REL_ "GenSigTimeoutTime" BU_SG_REL_ PSM SG_ 1127 DPSS_StSldBwdMvBtn 1500;
BA_REL_ "GenSigTimeoutTime" BU_SG_REL_ RLPSM SG_ 1127 DPSS_StSldBwdMvBtn 1500;
BA_ "NetworkRequest" SG_ 1127 DPSS_StSldBwdMvBtn 0;
BA_ "NetworkRequestHoldingTime" SG_ 1127 DPSS_StSldBwdMvBtn 5000;
BA_ "Version" SG_ 1127 DPSS_StSldBwdMvBtn "20.03.01";
BA_ "Description" SG_ 1127 DPSS_StRclFwdMvBtn "운전석 리클라이너 포워드 버튼";
BA_ "GenSigSendType" SG_ 1127 DPSS_StRclFwdMvBtn 4;
BA_ "UserSigValidity" SG_ 1127 DPSS_StRclFwdMvBtn 0;
BA_REL_ "GenSigTimeoutTime" BU_SG_REL_ PSM SG_ 1127 DPSS_StRclFwdMvBtn 1500;
BA_REL_ "GenSigTimeoutTime" BU_SG_REL_ RLPSM SG_ 1127 DPSS_StRclFwdMvBtn 1500;
BA_ "NetworkRequest" SG_ 1127 DPSS_StRclFwdMvBtn 0;
BA_ "NetworkRequestHoldingTime" SG_ 1127 DPSS_StRclFwdMvBtn 5000;
BA_ "Version" SG_ 1127 DPSS_StRclFwdMvBtn "20.03.01";
BA_ "Description" SG_ 1127 DPSS_StRclBwdMvBtn "운전석 리클라이너 백워드 버튼";
BA_ "GenSigSendType" SG_ 1127 DPSS_StRclBwdMvBtn 4;
BA_ "UserSigValidity" SG_ 1127 DPSS_StRclBwdMvBtn 0;
BA_REL_ "GenSigTimeoutTime" BU_SG_REL_ PSM SG_ 1127 DPSS_StRclBwdMvBtn 1500;
BA_REL_ "GenSigTimeoutTime" BU_SG_REL_ RLPSM SG_ 1127 DPSS_StRclBwdMvBtn 1500;
BA_ "NetworkRequest" SG_ 1127 DPSS_StRclBwdMvBtn 0;
BA_ "NetworkRequestHoldingTime" SG_ 1127 DPSS_StRclBwdMvBtn 5000;
BA_ "Version" SG_ 1127 DPSS_StRclBwdMvBtn "20.03.01";
BA_ "Description" SG_ 1127 DPSS_StHgtUpMvBtn "운전석 하이트 업 버튼";
BA_ "GenSigSendType" SG_ 1127 DPSS_StHgtUpMvBtn 4;
BA_ "UserSigValidity" SG_ 1127 DPSS_StHgtUpMvBtn 0;
BA_REL_ "GenSigTimeoutTime" BU_SG_REL_ PSM SG_ 1127 DPSS_StHgtUpMvBtn 1500;
BA_REL_ "GenSigTimeoutTime" BU_SG_REL_ RLPSM SG_ 1127 DPSS_StHgtUpMvBtn 1500;
BA_ "NetworkRequest" SG_ 1127 DPSS_StHgtUpMvBtn 0;
BA_ "NetworkRequestHoldingTime" SG_ 1127 DPSS_StHgtUpMvBtn 5000;
BA_ "Version" SG_ 1127 DPSS_StHgtUpMvBtn "20.03.01";
BA_ "Description" SG_ 1127 DPSS_StHgtDnMvBtn "운전석 하이트 다운 버튼";
BA_ "GenSigSendType" SG_ 1127 DPSS_StHgtDnMvBtn 4;
BA_ "UserSigValidity" SG_ 1127 DPSS_StHgtDnMvBtn 0;
BA_REL_ "GenSigTimeoutTime" BU_SG_REL_ PSM SG_ 1127 DPSS_StHgtDnMvBtn 1500;
BA_REL_ "GenSigTimeoutTime" BU_SG_REL_ RLPSM SG_ 1127 DPSS_StHgtDnMvBtn 1500;
BA_ "NetworkRequest" SG_ 1127 DPSS_StHgtDnMvBtn 0;
BA_ "NetworkRequestHoldingTime" SG_ 1127 DPSS_StHgtDnMvBtn 5000;
BA_ "Version" SG_ 1127 DPSS_StHgtDnMvBtn "20.03.01";
BA_ "Description" SG_ 1127 DPSS_StTltUpMvBtn "운전석 틸트 업 버튼";
BA_ "GenSigSendType" SG_ 1127 DPSS_StTltUpMvBtn 4;
BA_ "UserSigValidity" SG_ 1127 DPSS_StTltUpMvBtn 0;
BA_REL_ "GenSigTimeoutTime" BU_SG_REL_ PSM SG_ 1127 DPSS_StTltUpMvBtn 1500;
BA_ "NetworkRequest" SG_ 1127 DPSS_StTltUpMvBtn 0;
BA_ "NetworkRequestHoldingTime" SG_ 1127 DPSS_StTltUpMvBtn 5000;
BA_ "Version" SG_ 1127 DPSS_StTltUpMvBtn "20.03.01";
BA_ "Description" SG_ 1127 DPSS_StTltDnMvBtn "운전석 틸트 다운 버튼";
BA_ "GenSigSendType" SG_ 1127 DPSS_StTltDnMvBtn 4;
BA_ "UserSigValidity" SG_ 1127 DPSS_StTltDnMvBtn 0;
BA_REL_ "GenSigTimeoutTime" BU_SG_REL_ PSM SG_ 1127 DPSS_StTltDnMvBtn 1500;
BA_ "NetworkRequest" SG_ 1127 DPSS_StTltDnMvBtn 0;
BA_ "NetworkRequestHoldingTime" SG_ 1127 DPSS_StTltDnMvBtn 5000;
BA_ "Version" SG_ 1127 DPSS_StTltDnMvBtn "20.03.01";
BA_ "Description" SG_ 1127 DPSS_StHRestUpMvBtn "운전석 헤드레스트 UP 버튼";
BA_ "GenSigSendType" SG_ 1127 DPSS_StHRestUpMvBtn 4;
BA_ "UserSigValidity" SG_ 1127 DPSS_StHRestUpMvBtn 0;
BA_REL_ "GenSigTimeoutTime" BU_SG_REL_ PSM SG_ 1127 DPSS_StHRestUpMvBtn 1500;
BA_ "NetworkRequest" SG_ 1127 DPSS_StHRestUpMvBtn 0;
BA_ "NetworkRequestHoldingTime" SG_ 1127 DPSS_StHRestUpMvBtn 5000;
BA_ "Version" SG_ 1127 DPSS_StHRestUpMvBtn "20.03.01";
BA_ "Description" SG_ 1127 DPSS_StHRestDnMvBtn "운전석 헤드레스트 DOWN 버튼";
BA_ "GenSigSendType" SG_ 1127 DPSS_StHRestDnMvBtn 4;
BA_ "UserSigValidity" SG_ 1127 DPSS_StHRestDnMvBtn 0;
BA_REL_ "GenSigTimeoutTime" BU_SG_REL_ PSM SG_ 1127 DPSS_StHRestDnMvBtn 1500;
BA_ "NetworkRequest" SG_ 1127 DPSS_StHRestDnMvBtn 0;
BA_ "NetworkRequestHoldingTime" SG_ 1127 DPSS_StHRestDnMvBtn 5000;
BA_ "Version" SG_ 1127 DPSS_StHRestDnMvBtn "20.03.01";
BA_ "Description" SG_ 1127 DPSS_StHRestFwdMvBtn "운전석 헤드레스트 FWD 버튼";
BA_ "GenSigSendType" SG_ 1127 DPSS_StHRestFwdMvBtn 4;
BA_ "UserSigValidity" SG_ 1127 DPSS_StHRestFwdMvBtn 0;
BA_REL_ "GenSigTimeoutTime" BU_SG_REL_ PSM SG_ 1127 DPSS_StHRestFwdMvBtn 1500;
BA_ "NetworkRequest" SG_ 1127 DPSS_StHRestFwdMvBtn 0;
BA_ "NetworkRequestHoldingTime" SG_ 1127 DPSS_StHRestFwdMvBtn 5000;
BA_ "Version" SG_ 1127 DPSS_StHRestFwdMvBtn "20.03.01";
BA_ "Description" SG_ 1127 DPSS_StHRestBwdMvBtn "운전석 헤드레스트 BWD 버튼";
BA_ "GenSigSendType" SG_ 1127 DPSS_StHRestBwdMvBtn 4;
BA_ "UserSigValidity" SG_ 1127 DPSS_StHRestBwdMvBtn 0;
BA_REL_ "GenSigTimeoutTime" BU_SG_REL_ PSM SG_ 1127 DPSS_StHRestBwdMvBtn 1500;
BA_ "NetworkRequest" SG_ 1127 DPSS_StHRestBwdMvBtn 0;
BA_ "NetworkRequestHoldingTime" SG_ 1127 DPSS_StHRestBwdMvBtn 5000;
BA_ "Version" SG_ 1127 DPSS_StHRestBwdMvBtn "20.03.01";
BA_ "Description" SG_ 1127 DPSS_StLegUpMvBtn "운전석 레그레스트 업 버튼";
BA_ "GenSigSendType" SG_ 1127 DPSS_StLegUpMvBtn 4;
BA_ "UserSigValidity" SG_ 1127 DPSS_StLegUpMvBtn 0;
BA_REL_ "GenSigTimeoutTime" BU_SG_REL_ PSM SG_ 1127 DPSS_StLegUpMvBtn 1500;
BA_ "NetworkRequest" SG_ 1127 DPSS_StLegUpMvBtn 0;
BA_ "NetworkRequestHoldingTime" SG_ 1127 DPSS_StLegUpMvBtn 5000;
BA_ "Version" SG_ 1127 DPSS_StLegUpMvBtn "20.03.01";
BA_ "Description" SG_ 1127 DPSS_StLegDnMvBtn "운전석 레그레스트 다운 버튼";
BA_ "GenSigSendType" SG_ 1127 DPSS_StLegDnMvBtn 4;
BA_ "UserSigValidity" SG_ 1127 DPSS_StLegDnMvBtn 0;
BA_REL_ "GenSigTimeoutTime" BU_SG_REL_ PSM SG_ 1127 DPSS_StLegDnMvBtn 1500;
BA_ "NetworkRequest" SG_ 1127 DPSS_StLegDnMvBtn 0;
BA_ "NetworkRequestHoldingTime" SG_ 1127 DPSS_StLegDnMvBtn 5000;
BA_ "Version" SG_ 1127 DPSS_StLegDnMvBtn "20.03.01";
BA_ "Description" SG_ 1127 DPSS_StRlxModeBtn "운전석 릴렉스 모드 버튼";
BA_ "GenSigSendType" SG_ 1127 DPSS_StRlxModeBtn 4;
BA_ "UserSigValidity" SG_ 1127 DPSS_StRlxModeBtn 0;
BA_ "NetworkRequest" SG_ 1127 DPSS_StRlxModeBtn 0;
BA_ "NetworkRequestHoldingTime" SG_ 1127 DPSS_StRlxModeBtn 5000;
BA_ "Version" SG_ 1127 DPSS_StRlxModeBtn "20.03.01";
BA_ "Description" SG_ 1127 DPSS_StRlxReturnBtn "운전석 릴렉스 리턴 버튼";
BA_ "GenSigSendType" SG_ 1127 DPSS_StRlxReturnBtn 4;
BA_ "UserSigValidity" SG_ 1127 DPSS_StRlxReturnBtn 0;
BA_ "NetworkRequest" SG_ 1127 DPSS_StRlxReturnBtn 0;
BA_ "NetworkRequestHoldingTime" SG_ 1127 DPSS_StRlxReturnBtn 5000;
BA_ "Version" SG_ 1127 DPSS_StRlxReturnBtn "20.03.01";
BA_ "Description" SG_ 1127 DPSS_RlxStTltUpMvBtn "운전석 릴렉스 틸트 업 버튼";
BA_ "GenSigSendType" SG_ 1127 DPSS_RlxStTltUpMvBtn 4;
BA_ "UserSigValidity" SG_ 1127 DPSS_RlxStTltUpMvBtn 0;
BA_ "NetworkRequest" SG_ 1127 DPSS_RlxStTltUpMvBtn 0;
BA_ "NetworkRequestHoldingTime" SG_ 1127 DPSS_RlxStTltUpMvBtn 5000;
BA_ "Version" SG_ 1127 DPSS_RlxStTltUpMvBtn "20.03.01";
BA_ "Description" SG_ 1127 DPSS_RlxStTltDnMvBtn "운전석 릴렉스 틸트 다운 버튼";
BA_ "GenSigSendType" SG_ 1127 DPSS_RlxStTltDnMvBtn 4;
BA_ "UserSigValidity" SG_ 1127 DPSS_RlxStTltDnMvBtn 0;
BA_ "NetworkRequest" SG_ 1127 DPSS_RlxStTltDnMvBtn 0;
BA_ "NetworkRequestHoldingTime" SG_ 1127 DPSS_RlxStTltDnMvBtn 5000;
BA_ "Version" SG_ 1127 DPSS_RlxStTltDnMvBtn "20.03.01";
BA_ "GenMsgSendType" BO_ 1128 0;
BA_ "Description" SG_ 1128 DPSS_Crc2Val "The data area for CRC calculation is based on the data length (DLC) of the message DB.

The CRC shall be calculated over the entire data block (excluding the CRC bytes) including the user data, alive counter and Data ID 

 

- CRC Polynomial (0x1D) , Initial Value : 0x00, XOR value : 0xFF, Data ID Mode : Both, Data ID : Message ID + 0xF800 

- The initial value is for CRC calculation and the message should be sent with the calculated result value. 

The mathematical expression to 8 bit CRC polynomial is given here. G(x) = x8 + x4 + x3 + x2 + 1";
BA_ "GenSigSendType" SG_ 1128 DPSS_Crc2Val 4;
BA_ "GenSigStartValue" SG_ 1128 DPSS_Crc2Val 255;
BA_ "UserSigValidity" SG_ 1128 DPSS_Crc2Val 0;
BA_REL_ "GenSigTimeoutTime" BU_SG_REL_ DSAU SG_ 1128 DPSS_Crc2Val 1500;
BA_ "Version" SG_ 1128 DPSS_Crc2Val "19.01.01";
BA_ "Description" SG_ 1128 DPSS_AlvCnt2Val "For the first transmission request for a data element the counter shall be initialized with 0 and shall be incremented by 1

for every subsequent send request. When the counter reaches the maximum value(0xE), then it shall restart with 0 for the next send request";
BA_ "GenSigSendType" SG_ 1128 DPSS_AlvCnt2Val 4;
BA_ "UserSigValidity" SG_ 1128 DPSS_AlvCnt2Val 0;
BA_REL_ "GenSigTimeoutTime" BU_SG_REL_ DSAU SG_ 1128 DPSS_AlvCnt2Val 1500;
BA_ "Version" SG_ 1128 DPSS_AlvCnt2Val "19.01.01";
BA_ "Description" SG_ 1128 DPSS_LumbarUpSw "운전석 럼버 업 스위치";
BA_ "GenSigSendType" SG_ 1128 DPSS_LumbarUpSw 4;
BA_ "UserSigValidity" SG_ 1128 DPSS_LumbarUpSw 0;
BA_REL_ "GenSigTimeoutTime" BU_SG_REL_ DSAU SG_ 1128 DPSS_LumbarUpSw 1500;
BA_ "NetworkRequest" SG_ 1128 DPSS_LumbarUpSw 0;
BA_ "NetworkRequestHoldingTime" SG_ 1128 DPSS_LumbarUpSw 5000;
BA_ "Version" SG_ 1128 DPSS_LumbarUpSw "20.03.01";
BA_ "Description" SG_ 1128 DPSS_LumbarMidSw "운전석 럼버 미들 스위치";
BA_ "GenSigSendType" SG_ 1128 DPSS_LumbarMidSw 4;
BA_ "UserSigValidity" SG_ 1128 DPSS_LumbarMidSw 0;
BA_REL_ "GenSigTimeoutTime" BU_SG_REL_ DSAU SG_ 1128 DPSS_LumbarMidSw 1500;
BA_ "NetworkRequest" SG_ 1128 DPSS_LumbarMidSw 0;
BA_ "NetworkRequestHoldingTime" SG_ 1128 DPSS_LumbarMidSw 5000;
BA_ "Version" SG_ 1128 DPSS_LumbarMidSw "20.03.01";
BA_ "Description" SG_ 1128 DPSS_LumbarLowSw "운전석 럼버 하단 버튼";
BA_ "GenSigSendType" SG_ 1128 DPSS_LumbarLowSw 4;
BA_ "UserSigValidity" SG_ 1128 DPSS_LumbarLowSw 0;
BA_REL_ "GenSigTimeoutTime" BU_SG_REL_ DSAU SG_ 1128 DPSS_LumbarLowSw 1500;
BA_ "NetworkRequest" SG_ 1128 DPSS_LumbarLowSw 0;
BA_ "NetworkRequestHoldingTime" SG_ 1128 DPSS_LumbarLowSw 5000;
BA_ "Version" SG_ 1128 DPSS_LumbarLowSw "20.03.01";
BA_ "Description" SG_ 1128 DPSS_LumbarDefSw "운전석 럼버 디플레이션 버튼";
BA_ "GenSigSendType" SG_ 1128 DPSS_LumbarDefSw 4;
BA_ "UserSigValidity" SG_ 1128 DPSS_LumbarDefSw 0;
BA_REL_ "GenSigTimeoutTime" BU_SG_REL_ DSAU SG_ 1128 DPSS_LumbarDefSw 1500;
BA_ "NetworkRequest" SG_ 1128 DPSS_LumbarDefSw 0;
BA_ "NetworkRequestHoldingTime" SG_ 1128 DPSS_LumbarDefSw 5000;
BA_ "Version" SG_ 1128 DPSS_LumbarDefSw "20.03.01";
BA_ "Description" SG_ 1128 DPSS_BolsterInfSw "운전석 볼스터 흡기 버튼";
BA_ "GenSigSendType" SG_ 1128 DPSS_BolsterInfSw 4;
BA_ "UserSigValidity" SG_ 1128 DPSS_BolsterInfSw 0;
BA_REL_ "GenSigTimeoutTime" BU_SG_REL_ DSAU SG_ 1128 DPSS_BolsterInfSw 1500;
BA_ "NetworkRequest" SG_ 1128 DPSS_BolsterInfSw 0;
BA_ "NetworkRequestHoldingTime" SG_ 1128 DPSS_BolsterInfSw 5000;
BA_ "Version" SG_ 1128 DPSS_BolsterInfSw "20.03.01";
BA_ "Description" SG_ 1128 DPSS_BolsterDefSw "운전석 볼스터 배기 버튼";
BA_ "GenSigSendType" SG_ 1128 DPSS_BolsterDefSw 4;
BA_ "UserSigValidity" SG_ 1128 DPSS_BolsterDefSw 0;
BA_REL_ "GenSigTimeoutTime" BU_SG_REL_ DSAU SG_ 1128 DPSS_BolsterDefSw 1500;
BA_ "NetworkRequest" SG_ 1128 DPSS_BolsterDefSw 0;
BA_ "NetworkRequestHoldingTime" SG_ 1128 DPSS_BolsterDefSw 5000;
BA_ "Version" SG_ 1128 DPSS_BolsterDefSw "20.03.01";
BA_ "Description" SG_ 1128 DPSS_ActiveSw "운전석 쿠션 볼스터 조절 스위치";
BA_ "GenSigSendType" SG_ 1128 DPSS_ActiveSw 4;
BA_ "UserSigValidity" SG_ 1128 DPSS_ActiveSw 0;
BA_REL_ "GenSigTimeoutTime" BU_SG_REL_ DSAU SG_ 1128 DPSS_ActiveSw 1500;
BA_ "NetworkRequest" SG_ 1128 DPSS_ActiveSw 0;
BA_ "NetworkRequestHoldingTime" SG_ 1128 DPSS_ActiveSw 5000;
BA_ "Version" SG_ 1128 DPSS_ActiveSw "20.03.01";
BA_ "Description" SG_ 1128 DPSS_CushInfSw "운전석 쿠션공압조절 흡기 버튼";
BA_ "GenSigSendType" SG_ 1128 DPSS_CushInfSw 4;
BA_ "UserSigValidity" SG_ 1128 DPSS_CushInfSw 0;
BA_REL_ "GenSigTimeoutTime" BU_SG_REL_ DSAU SG_ 1128 DPSS_CushInfSw 1500;
BA_ "NetworkRequest" SG_ 1128 DPSS_CushInfSw 0;
BA_ "NetworkRequestHoldingTime" SG_ 1128 DPSS_CushInfSw 5000;
BA_ "Version" SG_ 1128 DPSS_CushInfSw "20.03.01";
BA_ "Description" SG_ 1128 DPSS_CushDefSw "운전석 쿠션 공압 조절 배기 버튼";
BA_ "GenSigSendType" SG_ 1128 DPSS_CushDefSw 4;
BA_ "UserSigValidity" SG_ 1128 DPSS_CushDefSw 0;
BA_REL_ "GenSigTimeoutTime" BU_SG_REL_ DSAU SG_ 1128 DPSS_CushDefSw 1500;
BA_ "NetworkRequest" SG_ 1128 DPSS_CushDefSw 0;
BA_ "NetworkRequestHoldingTime" SG_ 1128 DPSS_CushDefSw 5000;
BA_ "Version" SG_ 1128 DPSS_CushDefSw "20.03.01";
BA_ "GenMsgSendType" BO_ 1129 0;
BA_ "Description" SG_ 1129 DPSS_Crc3Val "The data area for CRC calculation is based on the data length (DLC) of the message DB.

The CRC shall be calculated over the entire data block (excluding the CRC bytes) including the user data, alive counter and Data ID 

 

- CRC Polynomial (0x1D) , Initial Value : 0x00, XOR value : 0xFF, Data ID Mode : Both, Data ID : Message ID + 0xF800 

- The initial value is for CRC calculation and the message should be sent with the calculated result value. 

The mathematical expression to 8 bit CRC polynomial is given here. G(x) = x8 + x4 + x3 + x2 + 1";
BA_ "GenSigSendType" SG_ 1129 DPSS_Crc3Val 4;
BA_ "GenSigStartValue" SG_ 1129 DPSS_Crc3Val 255;
BA_ "UserSigValidity" SG_ 1129 DPSS_Crc3Val 3;
BA_REL_ "GenSigTimeoutTime" BU_SG_REL_ CGW_CCU SG_ 1129 DPSS_Crc3Val 1500;
BA_ "Version" SG_ 1129 DPSS_Crc3Val "19.01.01";
BA_ "Description" SG_ 1129 DPSS_AlvCnt3Val "For the first transmission request for a data element the counter shall be initialized with 0 and shall be incremented by 1

for every subsequent send request. When the counter reaches the maximum value(0xE), then it shall restart with 0 for the next send request";
BA_ "GenSigSendType" SG_ 1129 DPSS_AlvCnt3Val 4;
BA_ "UserSigValidity" SG_ 1129 DPSS_AlvCnt3Val 3;
BA_REL_ "GenSigTimeoutTime" BU_SG_REL_ CGW_CCU SG_ 1129 DPSS_AlvCnt3Val 1500;
BA_ "Version" SG_ 1129 DPSS_AlvCnt3Val "19.01.01";
BA_ "Description" SG_ 1129 DPSS_SldTch "터치 스위치 정보";
BA_ "GenSigSendType" SG_ 1129 DPSS_SldTch 4;
BA_ "UserSigValidity" SG_ 1129 DPSS_SldTch 3;
BA_REL_ "GenSigTimeoutTime" BU_SG_REL_ CGW_CCU SG_ 1129 DPSS_SldTch 1500;
BA_ "NetworkRequest" SG_ 1129 DPSS_SldTch 0;
BA_ "NetworkRequestHoldingTime" SG_ 1129 DPSS_SldTch 5000;
BA_ "Version" SG_ 1129 DPSS_SldTch "19.01.01";
BA_ "Description" SG_ 1129 DPSS_RclTch "터치 스위치 정보";
BA_ "GenSigSendType" SG_ 1129 DPSS_RclTch 4;
BA_ "UserSigValidity" SG_ 1129 DPSS_RclTch 3;
BA_REL_ "GenSigTimeoutTime" BU_SG_REL_ CGW_CCU SG_ 1129 DPSS_RclTch 1500;
BA_ "NetworkRequest" SG_ 1129 DPSS_RclTch 0;
BA_ "NetworkRequestHoldingTime" SG_ 1129 DPSS_RclTch 5000;
BA_ "Version" SG_ 1129 DPSS_RclTch "19.01.01";
BA_ "Description" SG_ 1129 DPSS_ExtTch "터치 스위치 정보";
BA_ "GenSigSendType" SG_ 1129 DPSS_ExtTch 4;
BA_ "UserSigValidity" SG_ 1129 DPSS_ExtTch 3;
BA_REL_ "GenSigTimeoutTime" BU_SG_REL_ CGW_CCU SG_ 1129 DPSS_ExtTch 1500;
BA_ "NetworkRequest" SG_ 1129 DPSS_ExtTch 0;
BA_ "NetworkRequestHoldingTime" SG_ 1129 DPSS_ExtTch 5000;
BA_ "Version" SG_ 1129 DPSS_ExtTch "19.01.01";
BA_ "Description" SG_ 1129 DPSS_LmbrTch "터치 스위치 정보";
BA_ "GenSigSendType" SG_ 1129 DPSS_LmbrTch 4;
BA_ "UserSigValidity" SG_ 1129 DPSS_LmbrTch 3;
BA_REL_ "GenSigTimeoutTime" BU_SG_REL_ CGW_CCU SG_ 1129 DPSS_LmbrTch 1500;
BA_ "NetworkRequest" SG_ 1129 DPSS_LmbrTch 0;
BA_ "NetworkRequestHoldingTime" SG_ 1129 DPSS_LmbrTch 5000;
BA_ "Version" SG_ 1129 DPSS_LmbrTch "19.01.01";
BA_ "Description" SG_ 1129 DPSS_CushOnOffTch "터치 스위치 정보";
BA_ "GenSigSendType" SG_ 1129 DPSS_CushOnOffTch 4;
BA_ "UserSigValidity" SG_ 1129 DPSS_CushOnOffTch 3;
BA_REL_ "GenSigTimeoutTime" BU_SG_REL_ CGW_CCU SG_ 1129 DPSS_CushOnOffTch 1500;
BA_ "NetworkRequest" SG_ 1129 DPSS_CushOnOffTch 0;
BA_ "NetworkRequestHoldingTime" SG_ 1129 DPSS_CushOnOffTch 5000;
BA_ "Version" SG_ 1129 DPSS_CushOnOffTch "19.09.00";
BA_ "Description" SG_ 1129 DPSS_HRestTch "헤드레스트 스위치 터치 정보";
BA_ "GenSigSendType" SG_ 1129 DPSS_HRestTch 4;
BA_ "UserSigValidity" SG_ 1129 DPSS_HRestTch 3;
BA_REL_ "GenSigTimeoutTime" BU_SG_REL_ CGW_CCU SG_ 1129 DPSS_HRestTch 1500;
BA_ "NetworkRequest" SG_ 1129 DPSS_HRestTch 0;
BA_ "NetworkRequestHoldingTime" SG_ 1129 DPSS_HRestTch 5000;
BA_ "Version" SG_ 1129 DPSS_HRestTch "19.11.09";
BA_ "GenMsgSendType" BO_ 1105 0;
BA_ "GenSigSendType" SG_ 1105 FCS_FrLftStClrSwSta 4;
BA_ "UserSigValidity" SG_ 1105 FCS_FrLftStClrSwSta 7;
BA_REL_ "GenSigTimeoutTime" BU_SG_REL_ PSM SG_ 1105 FCS_FrLftStClrSwSta 1500;
BA_REL_ "GenSigTimeoutTime" BU_SG_REL_ APSM SG_ 1105 FCS_FrLftStClrSwSta 1500;
BA_ "NetworkRequest" SG_ 1105 FCS_FrLftStClrSwSta 0;
BA_ "NetworkRequestHoldingTime" SG_ 1105 FCS_FrLftStClrSwSta 5000;
BA_ "Version" SG_ 1105 FCS_FrLftStClrSwSta "19.11.05";
BA_ "Description" SG_ 1105 FCS_DrvDrAtClsSwSta "FCS_DriveDoorAutoClosingSwitchStatus";
BA_ "GenSigSendType" SG_ 1105 FCS_DrvDrAtClsSwSta 4;
BA_ "UserSigValidity" SG_ 1105 FCS_DrvDrAtClsSwSta 0;
BA_ "NetworkRequest" SG_ 1105 FCS_DrvDrAtClsSwSta 0;
BA_ "NetworkRequestHoldingTime" SG_ 1105 FCS_DrvDrAtClsSwSta 5000;
BA_ "Version" SG_ 1105 FCS_DrvDrAtClsSwSta "19.11.05";
BA_ "Description" SG_ 1105 FCS_AstDrAtClsSwSta "FCS_AssistDoorAutoClosingSwitchStatus";
BA_ "GenSigSendType" SG_ 1105 FCS_AstDrAtClsSwSta 4;
BA_ "UserSigValidity" SG_ 1105 FCS_AstDrAtClsSwSta 0;
BA_ "NetworkRequest" SG_ 1105 FCS_AstDrAtClsSwSta 0;
BA_ "NetworkRequestHoldingTime" SG_ 1105 FCS_AstDrAtClsSwSta 5000;
BA_ "Version" SG_ 1105 FCS_AstDrAtClsSwSta "19.11.05";
BA_ "Description" SG_ 1105 FCS_DrvModeSwSta "FCS_DriveModeSwitchStatus";
BA_ "GenSigSendType" SG_ 1105 FCS_DrvModeSwSta 4;
BA_ "UserSigValidity" SG_ 1105 FCS_DrvModeSwSta 3;
BA_ "NetworkRequest" SG_ 1105 FCS_DrvModeSwSta 0;
BA_ "NetworkRequestHoldingTime" SG_ 1105 FCS_DrvModeSwSta 5000;
BA_ "Version" SG_ 1105 FCS_DrvModeSwSta "19.11.05";
BA_ "Description" SG_ 1105 FCS_PDWSwSta "FCS_ParkingAssistSystemSwitchStatus";
BA_ "GenSigSendType" SG_ 1105 FCS_PDWSwSta 4;
BA_ "UserSigValidity" SG_ 1105 FCS_PDWSwSta 3;
BA_ "NetworkRequest" SG_ 1105 FCS_PDWSwSta 0;
BA_ "NetworkRequestHoldingTime" SG_ 1105 FCS_PDWSwSta 5000;
BA_ "Version" SG_ 1105 FCS_PDWSwSta "19.11.05";
BA_ "GenSigSendType" SG_ 1105 FCS_FrLftStHtrSwSta 4;
BA_ "UserSigValidity" SG_ 1105 FCS_FrLftStHtrSwSta 7;
BA_REL_ "GenSigTimeoutTime" BU_SG_REL_ PSM SG_ 1105 FCS_FrLftStHtrSwSta 1500;
BA_REL_ "GenSigTimeoutTime" BU_SG_REL_ APSM SG_ 1105 FCS_FrLftStHtrSwSta 1500;
BA_ "NetworkRequest" SG_ 1105 FCS_FrLftStHtrSwSta 0;
BA_ "NetworkRequestHoldingTime" SG_ 1105 FCS_FrLftStHtrSwSta 5000;
BA_ "Version" SG_ 1105 FCS_FrLftStHtrSwSta "19.11.05";
BA_ "GenSigSendType" SG_ 1105 FCS_FrRtStClrSwSta 4;
BA_ "UserSigValidity" SG_ 1105 FCS_FrRtStClrSwSta 7;
BA_REL_ "GenSigTimeoutTime" BU_SG_REL_ PSM SG_ 1105 FCS_FrRtStClrSwSta 1500;
BA_REL_ "GenSigTimeoutTime" BU_SG_REL_ APSM SG_ 1105 FCS_FrRtStClrSwSta 1500;
BA_ "NetworkRequest" SG_ 1105 FCS_FrRtStClrSwSta 0;
BA_ "NetworkRequestHoldingTime" SG_ 1105 FCS_FrRtStClrSwSta 5000;
BA_ "Version" SG_ 1105 FCS_FrRtStClrSwSta "19.11.05";
BA_ "GenSigSendType" SG_ 1105 FCS_FrRtStHtrSwSta 4;
BA_ "UserSigValidity" SG_ 1105 FCS_FrRtStHtrSwSta 7;
BA_REL_ "GenSigTimeoutTime" BU_SG_REL_ PSM SG_ 1105 FCS_FrRtStHtrSwSta 1500;
BA_REL_ "GenSigTimeoutTime" BU_SG_REL_ APSM SG_ 1105 FCS_FrRtStHtrSwSta 1500;
BA_ "NetworkRequest" SG_ 1105 FCS_FrRtStHtrSwSta 0;
BA_ "NetworkRequestHoldingTime" SG_ 1105 FCS_FrRtStHtrSwSta 5000;
BA_ "Version" SG_ 1105 FCS_FrRtStHtrSwSta "19.11.05";
BA_ "GenMsgSendType" BO_ 2378399489 0;
BA_ "GenMsgCycleTime" BO_ 2378399489 100;
BA_ "GenMsgCycleTimeFast" BO_ 2378399489 0;
BA_ "GenMsgNrOfRepetition" BO_ 2378399489 0;
BA_ "VFrameFormat" BO_ 2378399489 1;
BA_ "Description" SG_ 2378399489 GATEWAY_CrcVal "The data area for CRC calculation is based on the data length (DLC) of the message DB.

The CRC shall be calculated over the entire data block (excluding the CRC bytes) including the user data, alive counter and Data ID 

 

- CRC Polynomial (0x1D) , Initial Value : 0x00, XOR value : 0xFF, Data ID Mode : Both, Data ID : Message ID + 0xF800 

- The initial value is for CRC calculation and the message should be sent with the calculated result value. 

The mathematical expression to 8 bit CRC polynomial is given here. G(x) = x8 + x4 + x3 + x2 + 1";
BA_ "GenSigStartValue" SG_ 2378399489 GATEWAY_CrcVal 255;
BA_ "UserSigValidity" SG_ 2378399489 GATEWAY_CrcVal 0;
BA_REL_ "GenSigTimeoutTime" BU_SG_REL_ vHS_M SG_ 2378399489 GATEWAY_CrcVal 1500;
BA_ "Version" SG_ 2378399489 GATEWAY_CrcVal "18.11.08";
BA_ "Description" SG_ 2378399489 GATEWAY_AlvCntVal "For the first transmission request for a data element the counter shall be initialized with 0 and shall be incremented by 1

for every subsequent send request. When the counter reaches the maximum value(0xE), then it shall restart with 0 for the next send request";
BA_ "UserSigValidity" SG_ 2378399489 GATEWAY_AlvCntVal 0;
BA_ "Version" SG_ 2378399489 GATEWAY_AlvCntVal "18.11.08";
BA_ "UserSigValidity" SG_ 2378399489 GATEWAY_MM_STS 0;
BA_ "Version" SG_ 2378399489 GATEWAY_MM_STS "17.11.00";
BA_ "UserSigValidity" SG_ 2378399489 GATEWAY_HS_B_STS 0;
BA_ "Version" SG_ 2378399489 GATEWAY_HS_B_STS "17.11.00";
BA_ "UserSigValidity" SG_ 2378399489 GATEWAY_HS_D_STS 0;
BA_ "Version" SG_ 2378399489 GATEWAY_HS_D_STS "19.01.12";
BA_ "UserSigValidity" SG_ 2378399489 GATEWAY_FD_P_STS 0;
BA_ "Version" SG_ 2378399489 GATEWAY_FD_P_STS "17.11.00";
BA_ "UserSigValidity" SG_ 2378399489 GATEWAY_FD_C_STS 0;
BA_ "Version" SG_ 2378399489 GATEWAY_FD_C_STS "17.11.00";
BA_ "UserSigValidity" SG_ 2378399489 GATEWAY_FD_E_STS 0;
BA_ "Version" SG_ 2378399489 GATEWAY_FD_E_STS "17.11.00";
BA_ "UserSigValidity" SG_ 2378399489 GATEWAY_FD_I_STS 0;
BA_ "Version" SG_ 2378399489 GATEWAY_FD_I_STS "20.03.01";
BA_ "GenMsgSendType" BO_ 2563128577 0;
BA_ "GenMsgCycleTimeFast" BO_ 2563128577 0;
BA_ "GenMsgNrOfRepetition" BO_ 2563128577 0;
BA_ "VFrameFormat" BO_ 2563128577 1;
BA_ "Description" SG_ 2563128577 AMP_SetMaxMainVolStep "Command for Set AMP's Main Volume max step

0x0 : 35 step;

0x1 : 45 step;

0x2 : 75 step;

0x3 : Invalid";
BA_ "GenSigStartValue" SG_ 2563128577 AMP_SetMaxMainVolStep 3;
BA_ "UserSigValidity" SG_ 2563128577 AMP_SetMaxMainVolStep 1;
BA_REL_ "GenSigTimeoutTime" BU_SG_REL_ AMP SG_ 2563128577 AMP_SetMaxMainVolStep 1500;
BA_ "Version" SG_ 2563128577 AMP_SetMaxMainVolStep "20.04.01";
BA_ "GenMsgCycleTime" BO_ 2315420673 0;
BA_ "VFrameFormat" BO_ 2315420673 1;
BA_ "Description" SG_ 2315420673 AVN_Encrypted_Result4 "This signal is for a send encrypted result of AVN";
BA_ "GenSigSendType" SG_ 2315420673 AVN_Encrypted_Result4 4;
BA_ "UserSigValidity" SG_ 2315420673 AVN_Encrypted_Result4 0;
BA_REL_ "GenSigTimeoutTime" BU_SG_REL_ FPM SG_ 2315420673 AVN_Encrypted_Result4 0;
BA_ "Version" SG_ 2315420673 AVN_Encrypted_Result4 "21.07.05";
BA_ "GenMsgCycleTime" BO_ 1150 0;
BA_ "Description" SG_ 1150 IAU2FPM_EncryptedData1 "This signal is for a send enrypted result of IAU.";
BA_ "GenSigSendType" SG_ 1150 IAU2FPM_EncryptedData1 4;
BA_ "UserSigValidity" SG_ 1150 IAU2FPM_EncryptedData1 0;
BA_REL_ "GenSigTimeoutTime" BU_SG_REL_ FPM SG_ 1150 IAU2FPM_EncryptedData1 0;
BA_ "NetworkRequest" SG_ 1150 IAU2FPM_EncryptedData1 0;
BA_ "NetworkRequestHoldingTime" SG_ 1150 IAU2FPM_EncryptedData1 5000;
BA_ "Version" SG_ 1150 IAU2FPM_EncryptedData1 "20.03.07";
BA_ "GenMsgSendType" BO_ 2449771009 0;
BA_ "GenMsgCycleTime" BO_ 2449771009 1000;
BA_ "GenMsgCycleTimeFast" BO_ 2449771009 0;
BA_ "GenMsgNrOfRepetition" BO_ 2449771009 0;
BA_ "VFrameFormat" BO_ 2449771009 1;
BA_ "Description" SG_ 2449771009 ODS_Crc1Val "The data area for CRC calculation is based on the data length (DLC) of the message DB.

The CRC shall be calculated over the entire data block (excluding the CRC bytes) including the user data, alive counter and Data ID

 

- CRC Polynomial (0x1021) , Initial Value : 0xFFFF, XOR value : 0x0000, Data ID : Message ID + 0xF800 

- The initial value is for CRC calculation and the message should be sent with the calculated result value. 

- The mathematical expression to 16 bit CRC polynomial is given here. G(x) = x16 + x12 + x5 + 1";
BA_ "GenSigStartValue" SG_ 2449771009 ODS_Crc1Val 65535;
BA_ "UserSigValidity" SG_ 2449771009 ODS_Crc1Val 3;
BA_ "Version" SG_ 2449771009 ODS_Crc1Val "18.11.08";
BA_ "Description" SG_ 2449771009 ODS_AlvCnt1Val "For the first transmission request for a data element the counter shall be initialized with 0 and shall be incremented by 1 for every subsequent send request. 

When the counter reaches the maximum value(0xFF), then it shall restart with 0 for the next send request";
BA_ "UserSigValidity" SG_ 2449771009 ODS_AlvCnt1Val 3;
BA_ "Version" SG_ 2449771009 ODS_AlvCnt1Val "18.11.08";
BA_ "Description" SG_ 2449771009 ODS_IdVal "Information of Vehicle seat ID as defined by customer.



※ Initial Value 값(0x0) 무시 (전산 시스템 등록 차 임의로 0x0값 등록)

: Initial(Start) Value : Current Value";
BA_ "UserSigValidity" SG_ 2449771009 ODS_IdVal 3;
BA_ "Version" SG_ 2449771009 ODS_IdVal "17.12.02";
BA_ "Description" SG_ 2449771009 ODS_OccClassSta "Signal Value Table : reference with ODS Communiction instruction";
BA_ "GenSigStartValue" SG_ 2449771009 ODS_OccClassSta 4;
BA_ "UserSigValidity" SG_ 2449771009 ODS_OccClassSta 3;
BA_REL_ "GenSigTimeoutTime" BU_SG_REL_ APSM SG_ 2449771009 ODS_OccClassSta 5000;
BA_REL_ "GenSigTimeoutTime" BU_SG_REL_ ATS SG_ 2449771009 ODS_OccClassSta 5000;
BA_ "Version" SG_ 2449771009 ODS_OccClassSta "17.12.02";
BA_ "Description" SG_ 2449771009 ODS_DiagSta "CR_WCS_Errstat signal describes PODS-G & BOSE system error that is diagnosed by itself. Each Type set Diagnostic Status explains 3 kinds of fault.

[PODS-G]

Bit 1 : If ODS Have some errors, ODS set the bit, sends the ALR Defect signal to ACU and notifies the fault.

Bit 2 : If ODS Have some errors, ODS set the bit, sends the ECU Defect signal to ACU and notifies the fault.

Bit 5 : If ODS Have some errors, ODS set the bit, sends the EOL Error signal to ACU and notifies the fault.



[BOSE]

Bit 1 : If ODS Have some errors, ODS set the bit, sends the Mat Defect signal to ACU and notifies the fault.

Bit 2 : If ODS Have some errors, ODS set the bit, sends the ECU Defect signal to ACU and notifies the fault.

Bit 6 : If ODS Have some errors, ODS set the bit, sends the Algo Cut-off Error signal to ACU and notifies the fault.";
BA_ "UserSigValidity" SG_ 2449771009 ODS_DiagSta 3;
BA_ "Version" SG_ 2449771009 ODS_DiagSta "17.12.02";
BA_ "Description" SG_ 2449771009 ODS_SBRClassSta "Refer to Signal Value table";
BA_ "UserSigValidity" SG_ 2449771009 ODS_SBRClassSta 3;
BA_ "Version" SG_ 2449771009 ODS_SBRClassSta "19.05.02";
BA_ "GenMsgSendType" BO_ 2449771010 0;
BA_ "GenMsgCycleTime" BO_ 2449771010 1000;
BA_ "GenMsgCycleTimeFast" BO_ 2449771010 0;
BA_ "GenMsgNrOfRepetition" BO_ 2449771010 0;
BA_ "VFrameFormat" BO_ 2449771010 1;
BA_ "GenMsgSendType" BO_ 1089 0;
BA_ "Description" SG_ 1089 PSM_RrRtSldStrtSta "This signal indicates the start/finish of rear right slide motor.";
BA_ "GenSigSendType" SG_ 1089 PSM_RrRtSldStrtSta 4;
BA_ "UserSigValidity" SG_ 1089 PSM_RrRtSldStrtSta 0;
BA_REL_ "GenSigTimeoutTime" BU_SG_REL_ APSM SG_ 1089 PSM_RrRtSldStrtSta 1500;
BA_ "NetworkRequest" SG_ 1089 PSM_RrRtSldStrtSta 0;
BA_ "NetworkRequestHoldingTime" SG_ 1089 PSM_RrRtSldStrtSta 5000;
BA_ "Version" SG_ 1089 PSM_RrRtSldStrtSta "17.11.00";
BA_ "Description" SG_ 1089 RRPSM_PersonalLmpOnReq "RL PERSONAL LAMP ON/OFF REQUEST";
BA_ "GenSigSendType" SG_ 1089 RRPSM_PersonalLmpOnReq 4;
BA_ "UserSigValidity" SG_ 1089 RRPSM_PersonalLmpOnReq 0;
BA_REL_ "GenSigTimeoutTime" BU_SG_REL_ ATS SG_ 1089 RRPSM_PersonalLmpOnReq 1500;
BA_ "NetworkRequest" SG_ 1089 RRPSM_PersonalLmpOnReq 0;
BA_ "NetworkRequestHoldingTime" SG_ 1089 RRPSM_PersonalLmpOnReq 5000;
BA_ "Version" SG_ 1089 RRPSM_PersonalLmpOnReq "20.01.01";
BA_ "GenSigSendType" SG_ 1089 RRPSM_APSMBzrOnReq 4;
BA_ "UserSigValidity" SG_ 1089 RRPSM_APSMBzrOnReq 0;
BA_REL_ "GenSigTimeoutTime" BU_SG_REL_ APSM SG_ 1089 RRPSM_APSMBzrOnReq 1500;
BA_REL_ "GenSigTimeoutTime" BU_SG_REL_ ATS SG_ 1089 RRPSM_APSMBzrOnReq 1500;
BA_ "NetworkRequest" SG_ 1089 RRPSM_APSMBzrOnReq 0;
BA_ "NetworkRequestHoldingTime" SG_ 1089 RRPSM_APSMBzrOnReq 5000;
BA_ "Version" SG_ 1089 RRPSM_APSMBzrOnReq "17.11.00";
BA_ "GenSigSendType" SG_ 1089 RRPSM_LimSetSta 4;
BA_ "UserSigValidity" SG_ 1089 RRPSM_LimSetSta 0;
BA_REL_ "GenSigTimeoutTime" BU_SG_REL_ ATS SG_ 1089 RRPSM_LimSetSta 1500;
BA_ "NetworkRequest" SG_ 1089 RRPSM_LimSetSta 0;
BA_ "NetworkRequestHoldingTime" SG_ 1089 RRPSM_LimSetSta 5000;
BA_ "Version" SG_ 1089 RRPSM_LimSetSta "21.04.01";
BA_ "GenSigSendType" SG_ 1089 RRPSM_SeatTyp 4;
BA_ "UserSigValidity" SG_ 1089 RRPSM_SeatTyp 0;
BA_REL_ "GenSigTimeoutTime" BU_SG_REL_ APSM SG_ 1089 RRPSM_SeatTyp 1500;
BA_REL_ "GenSigTimeoutTime" BU_SG_REL_ PSM SG_ 1089 RRPSM_SeatTyp 1500;
BA_ "NetworkRequest" SG_ 1089 RRPSM_SeatTyp 0;
BA_ "NetworkRequestHoldingTime" SG_ 1089 RRPSM_SeatTyp 5000;
BA_ "Version" SG_ 1089 RRPSM_SeatTyp "21.03.11";
BA_ "GenSigSendType" SG_ 1089 RRPSM_RRStEsyAcsUSMSta 4;
BA_ "UserSigValidity" SG_ 1089 RRPSM_RRStEsyAcsUSMSta 0;
BA_REL_ "GenSigTimeoutTime" BU_SG_REL_ ATS SG_ 1089 RRPSM_RRStEsyAcsUSMSta 1500;
BA_REL_ "GenSigTimeoutTime" BU_SG_REL_ CGW_CCU SG_ 1089 RRPSM_RRStEsyAcsUSMSta 1500;
BA_ "NetworkRequest" SG_ 1089 RRPSM_RRStEsyAcsUSMSta 0;
BA_ "NetworkRequestHoldingTime" SG_ 1089 RRPSM_RRStEsyAcsUSMSta 5000;
BA_ "Version" SG_ 1089 RRPSM_RRStEsyAcsUSMSta "19.10.07";
BA_ "Description" SG_ 1089 RRPSM_LegSupportOpt "Leg Support Option Signal";
BA_ "GenSigSendType" SG_ 1089 RRPSM_LegSupportOpt 4;
BA_ "UserSigValidity" SG_ 1089 RRPSM_LegSupportOpt 0;
BA_REL_ "GenSigTimeoutTime" BU_SG_REL_ ATS SG_ 1089 RRPSM_LegSupportOpt 1500;
BA_REL_ "GenSigTimeoutTime" BU_SG_REL_ CGW_CCU SG_ 1089 RRPSM_LegSupportOpt 1500;
BA_ "NetworkRequest" SG_ 1089 RRPSM_LegSupportOpt 0;
BA_ "NetworkRequestHoldingTime" SG_ 1089 RRPSM_LegSupportOpt 5000;
BA_ "Version" SG_ 1089 RRPSM_LegSupportOpt "19.11.05";
BA_ "Description" SG_ 1089 RRPSM_RRSlidePosition "ASSIST SEAT SLIDE POSITION (UNIT: mm)";
BA_ "GenSigSendType" SG_ 1089 RRPSM_RRSlidePosition 4;
BA_ "UserSigValidity" SG_ 1089 RRPSM_RRSlidePosition 0;
BA_REL_ "GenSigTimeoutTime" BU_SG_REL_ APSM SG_ 1089 RRPSM_RRSlidePosition 1500;
BA_ "NetworkRequest" SG_ 1089 RRPSM_RRSlidePosition 0;
BA_ "NetworkRequestHoldingTime" SG_ 1089 RRPSM_RRSlidePosition 5000;
BA_ "Version" SG_ 1089 RRPSM_RRSlidePosition "19.08.08";
BA_ "Description" SG_ 1089 RRPSM_RearModeState "Rear Seat State For One Touch Mode";
BA_ "GenSigSendType" SG_ 1089 RRPSM_RearModeState 4;
BA_ "UserSigValidity" SG_ 1089 RRPSM_RearModeState 3;
BA_REL_ "GenSigTimeoutTime" BU_SG_REL_ APSM SG_ 1089 RRPSM_RearModeState 1500;
BA_REL_ "GenSigTimeoutTime" BU_SG_REL_ ATS SG_ 1089 RRPSM_RearModeState 1500;
BA_REL_ "GenSigTimeoutTime" BU_SG_REL_ RDC SG_ 1089 RRPSM_RearModeState 1500;
BA_REL_ "GenSigTimeoutTime" BU_SG_REL_ CGW_CCU SG_ 1089 RRPSM_RearModeState 1500;
BA_ "NetworkRequest" SG_ 1089 RRPSM_RearModeState 0;
BA_ "NetworkRequestHoldingTime" SG_ 1089 RRPSM_RearModeState 5000;
BA_ "Version" SG_ 1089 RRPSM_RearModeState "20.07.05";
BA_ "Description" SG_ 1089 RRPSM_RRLegRestPosition "Rear SEAT Leg Rest UP/DOWN POSITION (UNIT: º)";
BA_ "GenSigSendType" SG_ 1089 RRPSM_RRLegRestPosition 4;
BA_ "UserSigValidity" SG_ 1089 RRPSM_RRLegRestPosition 0;
BA_REL_ "GenSigTimeoutTime" BU_SG_REL_ APSM SG_ 1089 RRPSM_RRLegRestPosition 1500;
BA_ "NetworkRequest" SG_ 1089 RRPSM_RRLegRestPosition 0;
BA_ "NetworkRequestHoldingTime" SG_ 1089 RRPSM_RRLegRestPosition 5000;
BA_ "Version" SG_ 1089 RRPSM_RRLegRestPosition "20.09.00";
BA_ "Description" SG_ 1089 PSM_RearRightLegSpprtPosVal "RR REG SUPPORT UP DOWN POSITION (UNIT: ˚)";
BA_ "GenSigSendType" SG_ 1089 PSM_RearRightLegSpprtPosVal 4;
BA_ "UserSigValidity" SG_ 1089 PSM_RearRightLegSpprtPosVal 0;
BA_REL_ "GenSigTimeoutTime" BU_SG_REL_ APSM SG_ 1089 PSM_RearRightLegSpprtPosVal 1500;
BA_ "NetworkRequest" SG_ 1089 PSM_RearRightLegSpprtPosVal 0;
BA_ "NetworkRequestHoldingTime" SG_ 1089 PSM_RearRightLegSpprtPosVal 5000;
BA_ "Version" SG_ 1089 PSM_RearRightLegSpprtPosVal "17.11.00";
BA_ "GenMsgSendType" BO_ 1107 0;
BA_ "Description" SG_ 1107 RR_SHVU_SeatOptSta "후석 RH 시트에 적용된 히터/통풍 옵션 사양";
BA_ "GenSigSendType" SG_ 1107 RR_SHVU_SeatOptSta 4;
BA_ "UserSigValidity" SG_ 1107 RR_SHVU_SeatOptSta 3;
BA_REL_ "GenSigTimeoutTime" BU_SG_REL_ ASAU SG_ 1107 RR_SHVU_SeatOptSta 1500;
BA_REL_ "GenSigTimeoutTime" BU_SG_REL_ ATS SG_ 1107 RR_SHVU_SeatOptSta 1500;
BA_REL_ "GenSigTimeoutTime" BU_SG_REL_ CGW_CCU SG_ 1107 RR_SHVU_SeatOptSta 1500;
BA_REL_ "GenSigTimeoutTime" BU_SG_REL_ ATS SG_ 1107 RR_SHVU_SeatOptSta 1500;
BA_REL_ "GenSigTimeoutTime" BU_SG_REL_ CGW_CCU SG_ 1107 RR_SHVU_SeatOptSta 1500;
BA_ "NetworkRequest" SG_ 1107 RR_SHVU_SeatOptSta 0;
BA_ "NetworkRequestHoldingTime" SG_ 1107 RR_SHVU_SeatOptSta 5000;
BA_ "Version" SG_ 1107 RR_SHVU_SeatOptSta "17.12.03";
BA_ "Description" SG_ 1107 RR_SHVU_HtAutoDownRVal "RH 히터 오토다운 Enable/Disable 설정 정보";
BA_ "GenSigSendType" SG_ 1107 RR_SHVU_HtAutoDownRVal 4;
BA_ "UserSigValidity" SG_ 1107 RR_SHVU_HtAutoDownRVal 3;
BA_REL_ "GenSigTimeoutTime" BU_SG_REL_ ASAU SG_ 1107 RR_SHVU_HtAutoDownRVal 1500;
BA_REL_ "GenSigTimeoutTime" BU_SG_REL_ ATS SG_ 1107 RR_SHVU_HtAutoDownRVal 1500;
BA_REL_ "GenSigTimeoutTime" BU_SG_REL_ ASAU SG_ 1107 RR_SHVU_HtAutoDownRVal 1500;
BA_REL_ "GenSigTimeoutTime" BU_SG_REL_ ATS SG_ 1107 RR_SHVU_HtAutoDownRVal 1500;
BA_REL_ "GenSigTimeoutTime" BU_SG_REL_ CGW_CCU SG_ 1107 RR_SHVU_HtAutoDownRVal 1500;
BA_REL_ "GenSigTimeoutTime" BU_SG_REL_ CGW_CCU SG_ 1107 RR_SHVU_HtAutoDownRVal 1500;
BA_ "NetworkRequest" SG_ 1107 RR_SHVU_HtAutoDownRVal 0;
BA_ "NetworkRequestHoldingTime" SG_ 1107 RR_SHVU_HtAutoDownRVal 5000;
BA_ "Version" SG_ 1107 RR_SHVU_HtAutoDownRVal "17.12.03";
BA_ "Description" SG_ 1107 RR_SHVU_VntTurboSta "후석 RH 시트 통풍 터보모드 진입 정보";
BA_ "GenSigSendType" SG_ 1107 RR_SHVU_VntTurboSta 4;
BA_ "UserSigValidity" SG_ 1107 RR_SHVU_VntTurboSta 3;
BA_REL_ "GenSigTimeoutTime" BU_SG_REL_ ASAU SG_ 1107 RR_SHVU_VntTurboSta 1500;
BA_REL_ "GenSigTimeoutTime" BU_SG_REL_ ATS SG_ 1107 RR_SHVU_VntTurboSta 1500;
BA_REL_ "GenSigTimeoutTime" BU_SG_REL_ ASAU SG_ 1107 RR_SHVU_VntTurboSta 1500;
BA_REL_ "GenSigTimeoutTime" BU_SG_REL_ ATS SG_ 1107 RR_SHVU_VntTurboSta 1500;
BA_REL_ "GenSigTimeoutTime" BU_SG_REL_ CGW_CCU SG_ 1107 RR_SHVU_VntTurboSta 1500;
BA_REL_ "GenSigTimeoutTime" BU_SG_REL_ CGW_CCU SG_ 1107 RR_SHVU_VntTurboSta 1500;
BA_ "NetworkRequest" SG_ 1107 RR_SHVU_VntTurboSta 0;
BA_ "NetworkRequestHoldingTime" SG_ 1107 RR_SHVU_VntTurboSta 5000;
BA_ "Version" SG_ 1107 RR_SHVU_VntTurboSta "17.12.03";
BA_ "Description" SG_ 1107 RR_SHVU_SeatHtOperSta "후석 RH 시트 현재 작동 중인 히터/통풍 단수 상태";
BA_ "GenSigSendType" SG_ 1107 RR_SHVU_SeatHtOperSta 4;
BA_ "UserSigValidity" SG_ 1107 RR_SHVU_SeatHtOperSta 3;
BA_REL_ "GenSigTimeoutTime" BU_SG_REL_ APSM SG_ 1107 RR_SHVU_SeatHtOperSta 1500;
BA_REL_ "GenSigTimeoutTime" BU_SG_REL_ ASAU SG_ 1107 RR_SHVU_SeatHtOperSta 1500;
BA_REL_ "GenSigTimeoutTime" BU_SG_REL_ ATS SG_ 1107 RR_SHVU_SeatHtOperSta 1500;
BA_REL_ "GenSigTimeoutTime" BU_SG_REL_ CGW_CCU SG_ 1107 RR_SHVU_SeatHtOperSta 1500;
BA_REL_ "GenSigTimeoutTime" BU_SG_REL_ ASAU SG_ 1107 RR_SHVU_SeatHtOperSta 1500;
BA_REL_ "GenSigTimeoutTime" BU_SG_REL_ ATS SG_ 1107 RR_SHVU_SeatHtOperSta 1500;
BA_REL_ "GenSigTimeoutTime" BU_SG_REL_ CGW_CCU SG_ 1107 RR_SHVU_SeatHtOperSta 1500;
BA_REL_ "GenSigTimeoutTime" BU_SG_REL_ ATS SG_ 1107 RR_SHVU_SeatHtOperSta 1500;
BA_REL_ "GenSigTimeoutTime" BU_SG_REL_ CGW_CCU SG_ 1107 RR_SHVU_SeatHtOperSta 1500;
BA_ "NetworkRequest" SG_ 1107 RR_SHVU_SeatHtOperSta 0;
BA_ "NetworkRequestHoldingTime" SG_ 1107 RR_SHVU_SeatHtOperSta 5000;
BA_ "Version" SG_ 1107 RR_SHVU_SeatHtOperSta "17.12.03";
BA_ "Description" SG_ 1107 RR_SHVU_SeatOptSta_RHD "후석 RH 시트에 적용된 히터/통풍 옵션 사양 (RHD)";
BA_ "GenSigSendType" SG_ 1107 RR_SHVU_SeatOptSta_RHD 4;
BA_ "UserSigValidity" SG_ 1107 RR_SHVU_SeatOptSta_RHD 3;
BA_REL_ "GenSigTimeoutTime" BU_SG_REL_ ASAU SG_ 1107 RR_SHVU_SeatOptSta_RHD 1500;
BA_REL_ "GenSigTimeoutTime" BU_SG_REL_ ATS SG_ 1107 RR_SHVU_SeatOptSta_RHD 1500;
BA_REL_ "GenSigTimeoutTime" BU_SG_REL_ CGW_CCU SG_ 1107 RR_SHVU_SeatOptSta_RHD 1500;
BA_REL_ "GenSigTimeoutTime" BU_SG_REL_ ATS SG_ 1107 RR_SHVU_SeatOptSta_RHD 1500;
BA_REL_ "GenSigTimeoutTime" BU_SG_REL_ CGW_CCU SG_ 1107 RR_SHVU_SeatOptSta_RHD 1500;
BA_ "NetworkRequest" SG_ 1107 RR_SHVU_SeatOptSta_RHD 0;
BA_ "NetworkRequestHoldingTime" SG_ 1107 RR_SHVU_SeatOptSta_RHD 5000;
BA_ "Version" SG_ 1107 RR_SHVU_SeatOptSta_RHD "19.08.05";
BA_ "Description" SG_ 1107 RR_SHVU_SeatHtOperSta_RHD "후석 RH 시트 현재 작동 중인 히터/통풍 단수 상태 (RHD)";
BA_ "GenSigSendType" SG_ 1107 RR_SHVU_SeatHtOperSta_RHD 4;
BA_ "UserSigValidity" SG_ 1107 RR_SHVU_SeatHtOperSta_RHD 3;
BA_REL_ "GenSigTimeoutTime" BU_SG_REL_ ASAU SG_ 1107 RR_SHVU_SeatHtOperSta_RHD 1500;
BA_REL_ "GenSigTimeoutTime" BU_SG_REL_ ATS SG_ 1107 RR_SHVU_SeatHtOperSta_RHD 1500;
BA_REL_ "GenSigTimeoutTime" BU_SG_REL_ CGW_CCU SG_ 1107 RR_SHVU_SeatHtOperSta_RHD 1500;
BA_REL_ "GenSigTimeoutTime" BU_SG_REL_ ATS SG_ 1107 RR_SHVU_SeatHtOperSta_RHD 1500;
BA_REL_ "GenSigTimeoutTime" BU_SG_REL_ CGW_CCU SG_ 1107 RR_SHVU_SeatHtOperSta_RHD 1500;
BA_ "NetworkRequest" SG_ 1107 RR_SHVU_SeatHtOperSta_RHD 0;
BA_ "NetworkRequestHoldingTime" SG_ 1107 RR_SHVU_SeatHtOperSta_RHD 5000;
BA_ "Version" SG_ 1107 RR_SHVU_SeatHtOperSta_RHD "19.08.05";
BA_ "Description" SG_ 1107 RR_SHVU_HtSwHiIndSta_RHD "RR 시트 열선 스위치 High Indicator 정보 (RHD)

-2nd RH Seat heater high Information";
BA_ "GenSigSendType" SG_ 1107 RR_SHVU_HtSwHiIndSta_RHD 4;
BA_ "UserSigValidity" SG_ 1107 RR_SHVU_HtSwHiIndSta_RHD 3;
BA_REL_ "GenSigTimeoutTime" BU_SG_REL_ ASAU SG_ 1107 RR_SHVU_HtSwHiIndSta_RHD 1500;
BA_REL_ "GenSigTimeoutTime" BU_SG_REL_ ATS SG_ 1107 RR_SHVU_HtSwHiIndSta_RHD 1500;
BA_REL_ "GenSigTimeoutTime" BU_SG_REL_ CGW_CCU SG_ 1107 RR_SHVU_HtSwHiIndSta_RHD 1500;
BA_REL_ "GenSigTimeoutTime" BU_SG_REL_ ATS SG_ 1107 RR_SHVU_HtSwHiIndSta_RHD 1500;
BA_REL_ "GenSigTimeoutTime" BU_SG_REL_ CGW_CCU SG_ 1107 RR_SHVU_HtSwHiIndSta_RHD 1500;
BA_ "NetworkRequest" SG_ 1107 RR_SHVU_HtSwHiIndSta_RHD 0;
BA_ "NetworkRequestHoldingTime" SG_ 1107 RR_SHVU_HtSwHiIndSta_RHD 5000;
BA_ "Version" SG_ 1107 RR_SHVU_HtSwHiIndSta_RHD "19.08.05";
BA_ "Description" SG_ 1107 RR_SHVU_HtSwMidIndSta_RHD "RL 시트 열선 스위치 Mid Indicator 정보 (RHD)

-2nd LH Seat heater mid Information";
BA_ "GenSigSendType" SG_ 1107 RR_SHVU_HtSwMidIndSta_RHD 4;
BA_ "UserSigValidity" SG_ 1107 RR_SHVU_HtSwMidIndSta_RHD 3;
BA_REL_ "GenSigTimeoutTime" BU_SG_REL_ ASAU SG_ 1107 RR_SHVU_HtSwMidIndSta_RHD 1500;
BA_REL_ "GenSigTimeoutTime" BU_SG_REL_ ATS SG_ 1107 RR_SHVU_HtSwMidIndSta_RHD 1500;
BA_REL_ "GenSigTimeoutTime" BU_SG_REL_ CGW_CCU SG_ 1107 RR_SHVU_HtSwMidIndSta_RHD 1500;
BA_REL_ "GenSigTimeoutTime" BU_SG_REL_ ATS SG_ 1107 RR_SHVU_HtSwMidIndSta_RHD 1500;
BA_REL_ "GenSigTimeoutTime" BU_SG_REL_ CGW_CCU SG_ 1107 RR_SHVU_HtSwMidIndSta_RHD 1500;
BA_ "NetworkRequest" SG_ 1107 RR_SHVU_HtSwMidIndSta_RHD 0;
BA_ "NetworkRequestHoldingTime" SG_ 1107 RR_SHVU_HtSwMidIndSta_RHD 5000;
BA_ "Version" SG_ 1107 RR_SHVU_HtSwMidIndSta_RHD "19.08.05";
BA_ "Description" SG_ 1107 RR_SHVU_HtSwLowIndSta_RHD "RR 시트 열선 스위치 Low Indicator 정보 (RHD)

-2nd RH Seat heater low Information";
BA_ "GenSigSendType" SG_ 1107 RR_SHVU_HtSwLowIndSta_RHD 4;
BA_ "UserSigValidity" SG_ 1107 RR_SHVU_HtSwLowIndSta_RHD 3;
BA_REL_ "GenSigTimeoutTime" BU_SG_REL_ ASAU SG_ 1107 RR_SHVU_HtSwLowIndSta_RHD 1500;
BA_REL_ "GenSigTimeoutTime" BU_SG_REL_ ATS SG_ 1107 RR_SHVU_HtSwLowIndSta_RHD 1500;
BA_REL_ "GenSigTimeoutTime" BU_SG_REL_ CGW_CCU SG_ 1107 RR_SHVU_HtSwLowIndSta_RHD 1500;
BA_REL_ "GenSigTimeoutTime" BU_SG_REL_ ATS SG_ 1107 RR_SHVU_HtSwLowIndSta_RHD 1500;
BA_REL_ "GenSigTimeoutTime" BU_SG_REL_ CGW_CCU SG_ 1107 RR_SHVU_HtSwLowIndSta_RHD 1500;
BA_ "NetworkRequest" SG_ 1107 RR_SHVU_HtSwLowIndSta_RHD 0;
BA_ "NetworkRequestHoldingTime" SG_ 1107 RR_SHVU_HtSwLowIndSta_RHD 5000;
BA_ "Version" SG_ 1107 RR_SHVU_HtSwLowIndSta_RHD "19.08.05";
BA_ "Description" SG_ 1107 RR_SHVU_VntSwHiIndSta_RHD "RR 시트 통풍 스위치 High Indicator 정보 (RHD)

-2nd RH Seat vent high Information";
BA_ "GenSigSendType" SG_ 1107 RR_SHVU_VntSwHiIndSta_RHD 4;
BA_ "UserSigValidity" SG_ 1107 RR_SHVU_VntSwHiIndSta_RHD 3;
BA_REL_ "GenSigTimeoutTime" BU_SG_REL_ ASAU SG_ 1107 RR_SHVU_VntSwHiIndSta_RHD 1500;
BA_REL_ "GenSigTimeoutTime" BU_SG_REL_ ATS SG_ 1107 RR_SHVU_VntSwHiIndSta_RHD 1500;
BA_REL_ "GenSigTimeoutTime" BU_SG_REL_ CGW_CCU SG_ 1107 RR_SHVU_VntSwHiIndSta_RHD 1500;
BA_REL_ "GenSigTimeoutTime" BU_SG_REL_ ATS SG_ 1107 RR_SHVU_VntSwHiIndSta_RHD 1500;
BA_REL_ "GenSigTimeoutTime" BU_SG_REL_ CGW_CCU SG_ 1107 RR_SHVU_VntSwHiIndSta_RHD 1500;
BA_ "NetworkRequest" SG_ 1107 RR_SHVU_VntSwHiIndSta_RHD 0;
BA_ "NetworkRequestHoldingTime" SG_ 1107 RR_SHVU_VntSwHiIndSta_RHD 5000;
BA_ "Version" SG_ 1107 RR_SHVU_VntSwHiIndSta_RHD "19.08.05";
BA_ "Description" SG_ 1107 RR_SHVU_VntSwMidIndSta_RHD "RR 시트 통풍 스위치 Mid Indicator 정보 (RHD)

-2nd RH Seat vent mid Information";
BA_ "GenSigSendType" SG_ 1107 RR_SHVU_VntSwMidIndSta_RHD 4;
BA_ "UserSigValidity" SG_ 1107 RR_SHVU_VntSwMidIndSta_RHD 3;
BA_REL_ "GenSigTimeoutTime" BU_SG_REL_ ASAU SG_ 1107 RR_SHVU_VntSwMidIndSta_RHD 1500;
BA_REL_ "GenSigTimeoutTime" BU_SG_REL_ ATS SG_ 1107 RR_SHVU_VntSwMidIndSta_RHD 1500;
BA_REL_ "GenSigTimeoutTime" BU_SG_REL_ CGW_CCU SG_ 1107 RR_SHVU_VntSwMidIndSta_RHD 1500;
BA_REL_ "GenSigTimeoutTime" BU_SG_REL_ ATS SG_ 1107 RR_SHVU_VntSwMidIndSta_RHD 1500;
BA_REL_ "GenSigTimeoutTime" BU_SG_REL_ CGW_CCU SG_ 1107 RR_SHVU_VntSwMidIndSta_RHD 1500;
BA_ "NetworkRequest" SG_ 1107 RR_SHVU_VntSwMidIndSta_RHD 0;
BA_ "NetworkRequestHoldingTime" SG_ 1107 RR_SHVU_VntSwMidIndSta_RHD 5000;
BA_ "Version" SG_ 1107 RR_SHVU_VntSwMidIndSta_RHD "19.08.05";
BA_ "Description" SG_ 1107 RR_SHVU_VntSwLowIndSta_RHD "RR 시트 통풍 스위치 Low Indicator 정보 (RHD)

-2nd RH Seat vent low Information";
BA_ "GenSigSendType" SG_ 1107 RR_SHVU_VntSwLowIndSta_RHD 4;
BA_ "UserSigValidity" SG_ 1107 RR_SHVU_VntSwLowIndSta_RHD 3;
BA_REL_ "GenSigTimeoutTime" BU_SG_REL_ ASAU SG_ 1107 RR_SHVU_VntSwLowIndSta_RHD 1500;
BA_REL_ "GenSigTimeoutTime" BU_SG_REL_ ATS SG_ 1107 RR_SHVU_VntSwLowIndSta_RHD 1500;
BA_REL_ "GenSigTimeoutTime" BU_SG_REL_ CGW_CCU SG_ 1107 RR_SHVU_VntSwLowIndSta_RHD 1500;
BA_REL_ "GenSigTimeoutTime" BU_SG_REL_ ATS SG_ 1107 RR_SHVU_VntSwLowIndSta_RHD 1500;
BA_REL_ "GenSigTimeoutTime" BU_SG_REL_ CGW_CCU SG_ 1107 RR_SHVU_VntSwLowIndSta_RHD 1500;
BA_ "NetworkRequest" SG_ 1107 RR_SHVU_VntSwLowIndSta_RHD 0;
BA_ "NetworkRequestHoldingTime" SG_ 1107 RR_SHVU_VntSwLowIndSta_RHD 5000;
BA_ "Version" SG_ 1107 RR_SHVU_VntSwLowIndSta_RHD "19.08.05";
BA_ "Description" SG_ 1107 RR_SHVU_SeatHtFail "후석 RH 시트 FailSafe 발생 상태";
BA_ "GenSigSendType" SG_ 1107 RR_SHVU_SeatHtFail 4;
BA_ "UserSigValidity" SG_ 1107 RR_SHVU_SeatHtFail 3;
BA_REL_ "GenSigTimeoutTime" BU_SG_REL_ ASAU SG_ 1107 RR_SHVU_SeatHtFail 1500;
BA_REL_ "GenSigTimeoutTime" BU_SG_REL_ ATS SG_ 1107 RR_SHVU_SeatHtFail 1500;
BA_REL_ "GenSigTimeoutTime" BU_SG_REL_ CGW_CCU SG_ 1107 RR_SHVU_SeatHtFail 1500;
BA_REL_ "GenSigTimeoutTime" BU_SG_REL_ CGW_CCU SG_ 1107 RR_SHVU_SeatHtFail 1500;
BA_ "NetworkRequest" SG_ 1107 RR_SHVU_SeatHtFail 0;
BA_ "NetworkRequestHoldingTime" SG_ 1107 RR_SHVU_SeatHtFail 5000;
BA_ "Version" SG_ 1107 RR_SHVU_SeatHtFail "17.12.03";
BA_ "GenMsgSendType" BO_ 1092 0;
BA_ "Description" SG_ 1092 SMK_Crc2Val "The data area for CRC calculation is based on the data length (DLC) of the message DB.

The CRC shall be calculated over the entire data block (excluding the CRC bytes) including the user data, alive counter and Data ID 

 

- CRC Polynomial (0x1D) , Initial Value : 0x00, XOR value : 0xFF, Data ID Mode : Both, Data ID : Message ID + 0xF800 

- The initial value is for CRC calculation and the message should be sent with the calculated result value. 

The mathematical expression to 8 bit CRC polynomial is given here. G(x) = x8 + x4 + x3 + x2 + 1";
BA_ "GenSigSendType" SG_ 1092 SMK_Crc2Val 4;
BA_ "GenSigStartValue" SG_ 1092 SMK_Crc2Val 255;
BA_ "UserSigValidity" SG_ 1092 SMK_Crc2Val 0;
BA_ "Version" SG_ 1092 SMK_Crc2Val "18.11.08";
BA_ "Description" SG_ 1092 SMK_AlvCnt2Val "For the first transmission request for a data element the counter shall be initialized with 0 and shall be incremented by 1

for every subsequent send request. When the counter reaches the maximum value(0xE), then it shall restart with 0 for the next send request";
BA_ "GenSigSendType" SG_ 1092 SMK_AlvCnt2Val 4;
BA_ "UserSigValidity" SG_ 1092 SMK_AlvCnt2Val 0;
BA_ "Version" SG_ 1092 SMK_AlvCnt2Val "18.11.08";
BA_ "Description" SG_ 1092 SSB_StrtStpBtnSw1Sta "StartStop button switch #1 status";
BA_ "GenSigSendType" SG_ 1092 SSB_StrtStpBtnSw1Sta 4;
BA_ "UserSigValidity" SG_ 1092 SSB_StrtStpBtnSw1Sta 0;
BA_ "Version" SG_ 1092 SSB_StrtStpBtnSw1Sta "17.12.00";
BA_ "Description" SG_ 1092 SSB_StrtStpBtnSw2Sta "StartStop button switch #2 status";
BA_ "GenSigSendType" SG_ 1092 SSB_StrtStpBtnSw2Sta 4;
BA_ "UserSigValidity" SG_ 1092 SSB_StrtStpBtnSw2Sta 0;
BA_ "Version" SG_ 1092 SSB_StrtStpBtnSw2Sta "17.12.00";
BA_ "Description" SG_ 1092 SMK_TrmnlCtrlSta "Mirror value of TerminalControlState";
BA_ "GenSigSendType" SG_ 1092 SMK_TrmnlCtrlSta 4;
BA_ "UserSigValidity" SG_ 1092 SMK_TrmnlCtrlSta 0;
BA_ "Version" SG_ 1092 SMK_TrmnlCtrlSta "17.12.00";
BA_ "Description" SG_ 1092 SMK_TrmnlMngrSta "Mirror valeu of TerminalsManager Stat";
BA_ "GenSigSendType" SG_ 1092 SMK_TrmnlMngrSta 4;
BA_ "UserSigValidity" SG_ 1092 SMK_TrmnlMngrSta 0;
BA_REL_ "GenSigTimeoutTime" BU_SG_REL_ FPM SG_ 1092 SMK_TrmnlMngrSta 1500;
BA_ "Version" SG_ 1092 SMK_TrmnlMngrSta "19.03.05";
BA_ "GenSigSendType" SG_ 1092 SMK_AuthSta 4;
BA_ "UserSigValidity" SG_ 1092 SMK_AuthSta 0;
BA_REL_ "GenSigTimeoutTime" BU_SG_REL_ PSM SG_ 1092 SMK_AuthSta 1500;
BA_REL_ "GenSigTimeoutTime" BU_SG_REL_ APSM SG_ 1092 SMK_AuthSta 1500;
BA_REL_ "GenSigTimeoutTime" BU_SG_REL_ RLPSM SG_ 1092 SMK_AuthSta 1500;
BA_REL_ "GenSigTimeoutTime" BU_SG_REL_ RRPSM SG_ 1092 SMK_AuthSta 1500;
BA_ "Version" SG_ 1092 SMK_AuthSta "17.12.00";
BA_ "Description" SG_ 1092 SMK_Ign1InSta "Ignition1 Input Status at SMK";
BA_ "GenSigSendType" SG_ 1092 SMK_Ign1InSta 4;
BA_ "UserSigValidity" SG_ 1092 SMK_Ign1InSta 0;
BA_ "Version" SG_ 1092 SMK_Ign1InSta "17.12.00";
BA_ "Description" SG_ 1092 SMK_Ign1RlySta "Development for SMK";
BA_ "GenSigSendType" SG_ 1092 SMK_Ign1RlySta 4;
BA_ "UserSigValidity" SG_ 1092 SMK_Ign1RlySta 0;
BA_ "Version" SG_ 1092 SMK_Ign1RlySta "17.12.00";
BA_ "Description" SG_ 1092 SMK_Ign2InSta "Ignition2 Input Status at SMK";
BA_ "GenSigSendType" SG_ 1092 SMK_Ign2InSta 4;
BA_ "UserSigValidity" SG_ 1092 SMK_Ign2InSta 0;
BA_ "Version" SG_ 1092 SMK_Ign2InSta "17.12.00";
BA_ "Description" SG_ 1092 SMK_Ign2RlySta "Development for SMK";
BA_ "GenSigSendType" SG_ 1092 SMK_Ign2RlySta 4;
BA_ "UserSigValidity" SG_ 1092 SMK_Ign2RlySta 0;
BA_ "Version" SG_ 1092 SMK_Ign2RlySta "17.12.00";
BA_ "Description" SG_ 1092 SMK_StrtFdbckSta "Mirror value of L_StartFeedback";
BA_ "GenSigSendType" SG_ 1092 SMK_StrtFdbckSta 4;
BA_ "UserSigValidity" SG_ 1092 SMK_StrtFdbckSta 0;
BA_ "Version" SG_ 1092 SMK_StrtFdbckSta "17.12.00";
BA_ "Description" SG_ 1092 SMK_StrtrRlyOutSta "-(Old)C_StarterRelayStatus";
BA_ "GenSigSendType" SG_ 1092 SMK_StrtrRlyOutSta 4;
BA_ "UserSigValidity" SG_ 1092 SMK_StrtrRlyOutSta 0;
BA_ "Version" SG_ 1092 SMK_StrtrRlyOutSta "17.12.00";
BA_ "Description" SG_ 1092 SMK_AccInSta "ACC Input Status at SMK";
BA_ "GenSigSendType" SG_ 1092 SMK_AccInSta 4;
BA_ "UserSigValidity" SG_ 1092 SMK_AccInSta 0;
BA_ "Version" SG_ 1092 SMK_AccInSta "17.12.00";
BA_ "Description" SG_ 1092 SMK_AccRlySta "Development for SMK";
BA_ "GenSigSendType" SG_ 1092 SMK_AccRlySta 4;
BA_ "UserSigValidity" SG_ 1092 SMK_AccRlySta 0;
BA_ "Version" SG_ 1092 SMK_AccRlySta "17.12.00";
BA_ "Description" SG_ 1092 SMK_CLUAccIndOnReq "Request to Cluster ACC Indicator On

(This is only used for CLU)";
BA_ "GenSigSendType" SG_ 1092 SMK_CLUAccIndOnReq 4;
BA_ "UserSigValidity" SG_ 1092 SMK_CLUAccIndOnReq 0;
BA_ "Version" SG_ 1092 SMK_CLUAccIndOnReq "17.12.00";
BA_ "GenSigSendType" SG_ 1092 SMK_TlEngRunSta 4;
BA_ "UserSigValidity" SG_ 1092 SMK_TlEngRunSta 0;
BA_REL_ "GenSigTimeoutTime" BU_SG_REL_ PSM SG_ 1092 SMK_TlEngRunSta 1500;
BA_REL_ "GenSigTimeoutTime" BU_SG_REL_ APSM SG_ 1092 SMK_TlEngRunSta 1500;
BA_REL_ "GenSigTimeoutTime" BU_SG_REL_ RLPSM SG_ 1092 SMK_TlEngRunSta 1500;
BA_REL_ "GenSigTimeoutTime" BU_SG_REL_ RRPSM SG_ 1092 SMK_TlEngRunSta 1500;
BA_REL_ "GenSigTimeoutTime" BU_SG_REL_ RLHV SG_ 1092 SMK_TlEngRunSta 1500;
BA_REL_ "GenSigTimeoutTime" BU_SG_REL_ RRHV SG_ 1092 SMK_TlEngRunSta 1500;
BA_REL_ "GenSigTimeoutTime" BU_SG_REL_ SHVU_RR SG_ 1092 SMK_TlEngRunSta 1500;
BA_REL_ "GenSigTimeoutTime" BU_SG_REL_ DPSS SG_ 1092 SMK_TlEngRunSta 1500;
BA_REL_ "GenSigTimeoutTime" BU_SG_REL_ FPM SG_ 1092 SMK_TlEngRunSta 1500;
BA_REL_ "GenSigTimeoutTime" BU_SG_REL_ ATS SG_ 1092 SMK_TlEngRunSta 1500;
BA_REL_ "GenSigTimeoutTime" BU_SG_REL_ DSAU SG_ 1092 SMK_TlEngRunSta 1500;
BA_REL_ "GenSigTimeoutTime" BU_SG_REL_ ASAU SG_ 1092 SMK_TlEngRunSta 1500;
BA_ "Version" SG_ 1092 SMK_TlEngRunSta "17.12.00";
BA_ "GenSigSendType" SG_ 1092 SMK_TlCrnkModSta 4;
BA_ "UserSigValidity" SG_ 1092 SMK_TlCrnkModSta 0;
BA_REL_ "GenSigTimeoutTime" BU_SG_REL_ PSM SG_ 1092 SMK_TlCrnkModSta 1500;
BA_REL_ "GenSigTimeoutTime" BU_SG_REL_ APSM SG_ 1092 SMK_TlCrnkModSta 1500;
BA_REL_ "GenSigTimeoutTime" BU_SG_REL_ RLPSM SG_ 1092 SMK_TlCrnkModSta 1500;
BA_REL_ "GenSigTimeoutTime" BU_SG_REL_ RRPSM SG_ 1092 SMK_TlCrnkModSta 1500;
BA_REL_ "GenSigTimeoutTime" BU_SG_REL_ DPSS SG_ 1092 SMK_TlCrnkModSta 1500;
BA_REL_ "GenSigTimeoutTime" BU_SG_REL_ ATS SG_ 1092 SMK_TlCrnkModSta 1500;
BA_REL_ "GenSigTimeoutTime" BU_SG_REL_ DSAU SG_ 1092 SMK_TlCrnkModSta 1500;
BA_REL_ "GenSigTimeoutTime" BU_SG_REL_ ASAU SG_ 1092 SMK_TlCrnkModSta 1500;
BA_ "Version" SG_ 1092 SMK_TlCrnkModSta "17.12.00";
BA_ "GenSigSendType" SG_ 1092 SMK_RmtKeyEngRunSta 4;
BA_ "UserSigValidity" SG_ 1092 SMK_RmtKeyEngRunSta 0;
BA_ "Version" SG_ 1092 SMK_RmtKeyEngRunSta "17.11.00";
BA_ "GenMsgSendType" BO_ 1108 0;
BA_ "Description" SG_ 1108 SMK_Crc3Val "The data area for CRC calculation is based on the data length (DLC) of the message DB.

The CRC shall be calculated over the entire data block (excluding the CRC bytes) including the user data, alive counter and Data ID 

 

- CRC Polynomial (0x1D) , Initial Value : 0x00, XOR value : 0xFF, Data ID Mode : Both, Data ID : Message ID + 0xF800 

- The initial value is for CRC calculation and the message should be sent with the calculated result value. 

The mathematical expression to 8 bit CRC polynomial is given here. G(x) = x8 + x4 + x3 + x2 + 1";
BA_ "GenSigSendType" SG_ 1108 SMK_Crc3Val 4;
BA_ "GenSigStartValue" SG_ 1108 SMK_Crc3Val 255;
BA_ "UserSigValidity" SG_ 1108 SMK_Crc3Val 0;
BA_ "Version" SG_ 1108 SMK_Crc3Val "18.11.08";
BA_ "Description" SG_ 1108 SMK_AlvCnt3Val "For the first transmission request for a data element the counter shall be initialized with 0 and shall be incremented by 1

for every subsequent send request. When the counter reaches the maximum value(0xE), then it shall restart with 0 for the next send request";
BA_ "GenSigSendType" SG_ 1108 SMK_AlvCnt3Val 4;
BA_ "UserSigValidity" SG_ 1108 SMK_AlvCnt3Val 0;
BA_ "Version" SG_ 1108 SMK_AlvCnt3Val "18.11.08";
BA_ "Description" SG_ 1108 ESCL_EsclMngrSta "ESCL manager state";
BA_ "GenSigSendType" SG_ 1108 ESCL_EsclMngrSta 4;
BA_ "UserSigValidity" SG_ 1108 ESCL_EsclMngrSta 0;
BA_ "Version" SG_ 1108 ESCL_EsclMngrSta "17.12.00";
BA_ "Description" SG_ 1108 ESCL_EsclPwrSupSta "ESCL GND & BAT supply line status";
BA_ "GenSigSendType" SG_ 1108 ESCL_EsclPwrSupSta 4;
BA_ "UserSigValidity" SG_ 1108 ESCL_EsclPwrSupSta 0;
BA_ "Version" SG_ 1108 ESCL_EsclPwrSupSta "17.12.00";
BA_ "Description" SG_ 1108 ESCL_EsclEnaSta "SMK ESCL Enable output status";
BA_ "GenSigSendType" SG_ 1108 ESCL_EsclEnaSta 4;
BA_ "UserSigValidity" SG_ 1108 ESCL_EsclEnaSta 0;
BA_ "Version" SG_ 1108 ESCL_EsclEnaSta "17.12.00";
BA_ "Description" SG_ 1108 ESCL_EsclUnitSta "ESCL unit status";
BA_ "GenSigSendType" SG_ 1108 ESCL_EsclUnitSta 4;
BA_ "UserSigValidity" SG_ 1108 ESCL_EsclUnitSta 0;
BA_ "Version" SG_ 1108 ESCL_EsclUnitSta "17.12.00";
BA_ "Description" SG_ 1108 ESCL_EsclBoltSta "ESCL bolt status";
BA_ "GenSigSendType" SG_ 1108 ESCL_EsclBoltSta 4;
BA_ "UserSigValidity" SG_ 1108 ESCL_EsclBoltSta 0;
BA_ "Version" SG_ 1108 ESCL_EsclBoltSta "17.12.00";
BA_ "Description" SG_ 1108 Fob_FoundExtrnlIntArea "Exterior and Interior FOB Position recognize for Approach close function";
BA_ "GenSigSendType" SG_ 1108 Fob_FoundExtrnlIntArea 4;
BA_ "UserSigValidity" SG_ 1108 Fob_FoundExtrnlIntArea 0;
BA_ "Version" SG_ 1108 Fob_FoundExtrnlIntArea "20.06.02";
BA_ "Description" SG_ 1108 ESCL_EsclLoBattSta "Mirror value of ESCL Low Battery bit in ESCL Status bytes";
BA_ "GenSigSendType" SG_ 1108 ESCL_EsclLoBattSta 4;
BA_ "UserSigValidity" SG_ 1108 ESCL_EsclLoBattSta 0;
BA_ "Version" SG_ 1108 ESCL_EsclLoBattSta "17.12.00";
BA_ "Description" SG_ 1108 ESCL_EsclUnLkSwSta "ESCL unlock switch status";
BA_ "GenSigSendType" SG_ 1108 ESCL_EsclUnLkSwSta 4;
BA_ "UserSigValidity" SG_ 1108 ESCL_EsclUnLkSwSta 0;
BA_ "Version" SG_ 1108 ESCL_EsclUnLkSwSta "17.12.00";
BA_ "Description" SG_ 1108 SMK_DigitalKeyPosReq "This signal is to request Positioning of DigitalKey";
BA_ "GenSigSendType" SG_ 1108 SMK_DigitalKeyPosReq 4;
BA_ "UserSigValidity" SG_ 1108 SMK_DigitalKeyPosReq 0;
BA_ "NetworkRequest" SG_ 1108 SMK_DigitalKeyPosReq 0;
BA_ "NetworkRequestHoldingTime" SG_ 1108 SMK_DigitalKeyPosReq 5;
BA_ "Version" SG_ 1108 SMK_DigitalKeyPosReq "20.05.03";
BA_ "Description" SG_ 1108 SMK_OTACrankInhState "Crank inhibit control state of OTA";
BA_ "GenSigSendType" SG_ 1108 SMK_OTACrankInhState 4;
BA_ "UserSigValidity" SG_ 1108 SMK_OTACrankInhState 0;
BA_REL_ "GenSigTimeoutTime" BU_SG_REL_ AMP SG_ 1108 SMK_OTACrankInhState 1500;
BA_ "Version" SG_ 1108 SMK_OTACrankInhState "20.05.03";
BA_ "Description" SG_ 1108 Fob_FoundRrLftArea "This Signal Indicates direction of user approach to vehicle.

If Approach Open function is enabled and user Approach to vehicle Rear Left direction, 

This signal set On.";
BA_ "GenSigSendType" SG_ 1108 Fob_FoundRrLftArea 4;
BA_ "UserSigValidity" SG_ 1108 Fob_FoundRrLftArea 0;
BA_ "Version" SG_ 1108 Fob_FoundRrLftArea "20.06.02";
BA_ "Description" SG_ 1108 Fob_FoundRrRtArea "This Signal Indicates direction of user approach to vehicle.

If Approach Open function is enabled and user Approach to vehicle Rear Right direction, 

This signal set On.";
BA_ "GenSigSendType" SG_ 1108 Fob_FoundRrRtArea 4;
BA_ "UserSigValidity" SG_ 1108 Fob_FoundRrRtArea 0;
BA_ "Version" SG_ 1108 Fob_FoundRrRtArea "20.06.02";
BA_ "GenMsgSendType" BO_ 1093 0;
BA_ "Description" SG_ 1093 SMK_Crc6Val "The data area for CRC calculation is based on the data length (DLC) of the message DB.

The CRC shall be calculated over the entire data block (excluding the CRC bytes) including the user data, alive counter and Data ID 

 

- CRC Polynomial (0x1D) , Initial Value : 0x00, XOR value : 0xFF, Data ID Mode : Both, Data ID : Message ID + 0xF800 

- The initial value is for CRC calculation and the message should be sent with the calculated result value. 

The mathematical expression to 8 bit CRC polynomial is given here. G(x) = x8 + x4 + x3 + x2 + 1";
BA_ "GenSigSendType" SG_ 1093 SMK_Crc6Val 4;
BA_ "GenSigStartValue" SG_ 1093 SMK_Crc6Val 255;
BA_ "UserSigValidity" SG_ 1093 SMK_Crc6Val 0;
BA_ "Version" SG_ 1093 SMK_Crc6Val "18.11.08";
BA_ "Description" SG_ 1093 SMK_AlvCnt6Val "For the first transmission request for a data element the counter shall be initialized with 0 and shall be incremented by 1

for every subsequent send request. When the counter reaches the maximum value(0xE), then it shall restart with 0 for the next send request";
BA_ "GenSigSendType" SG_ 1093 SMK_AlvCnt6Val 4;
BA_ "UserSigValidity" SG_ 1093 SMK_AlvCnt6Val 0;
BA_ "Version" SG_ 1093 SMK_AlvCnt6Val "18.11.08";
BA_ "Description" SG_ 1093 Lamp_HzrdBlnkngSta "Hazard Signal for Hands Free Trunk/Tailgate";
BA_ "GenSigSendType" SG_ 1093 Lamp_HzrdBlnkngSta 4;
BA_ "UserSigValidity" SG_ 1093 Lamp_HzrdBlnkngSta 0;
BA_ "Version" SG_ 1093 Lamp_HzrdBlnkngSta "17.12.00";
BA_ "Description" SG_ 1093 RSPA_LearntSta "IBU RSPA learnt state signal.

This signal is used only for ADAS_PRK.";
BA_ "GenSigSendType" SG_ 1093 RSPA_LearntSta 4;
BA_ "UserSigValidity" SG_ 1093 RSPA_LearntSta 0;
BA_ "Version" SG_ 1093 RSPA_LearntSta "19.07.01";
BA_ "Description" SG_ 1093 Lamp_SmrtWlcmLtOnReq "Smart Key welcome light on request.";
BA_ "GenSigSendType" SG_ 1093 Lamp_SmrtWlcmLtOnReq 4;
BA_ "UserSigValidity" SG_ 1093 Lamp_SmrtWlcmLtOnReq 0;
BA_ "NetworkRequest" SG_ 1093 Lamp_SmrtWlcmLtOnReq 0;
BA_ "NetworkRequestHoldingTime" SG_ 1093 Lamp_SmrtWlcmLtOnReq 5000;
BA_ "Version" SG_ 1093 Lamp_SmrtWlcmLtOnReq "17.12.00";
BA_ "Description" SG_ 1093 Fob_BattStaInfo "Received Fob Battery Status for Telematics Vehicle Information Service";
BA_ "GenSigSendType" SG_ 1093 Fob_BattStaInfo 4;
BA_ "UserSigValidity" SG_ 1093 Fob_BattStaInfo 0;
BA_ "Version" SG_ 1093 Fob_BattStaInfo "17.12.00";
BA_ "Description" SG_ 1093 Fob_FoundDrvWlcmArea "This Signal Indicates direction of user approach to vehicle.

If User Approach to vehicle Driver direction, This signal set On.";
BA_ "GenSigSendType" SG_ 1093 Fob_FoundDrvWlcmArea 4;
BA_ "UserSigValidity" SG_ 1093 Fob_FoundDrvWlcmArea 0;
BA_ "Version" SG_ 1093 Fob_FoundDrvWlcmArea "17.12.00";
BA_ "Description" SG_ 1093 Fob_FoundAsstWlcmArea "This Signal Indicates direction of user approach to vehicle.

If User Approach to vehicle Assistant direction, This signal set On.";
BA_ "GenSigSendType" SG_ 1093 Fob_FoundAsstWlcmArea 4;
BA_ "UserSigValidity" SG_ 1093 Fob_FoundAsstWlcmArea 0;
BA_ "Version" SG_ 1093 Fob_FoundAsstWlcmArea "17.12.00";
BA_ "Description" SG_ 1093 Fob_FoundExtrnlArea "Exterior FOB Position recognize";
BA_ "GenSigSendType" SG_ 1093 Fob_FoundExtrnlArea 4;
BA_ "UserSigValidity" SG_ 1093 Fob_FoundExtrnlArea 0;
BA_ "Version" SG_ 1093 Fob_FoundExtrnlArea "17.12.00";
BA_ "Description" SG_ 1093 Fob_FoundIntArea "Interior FOB Position recognize";
BA_ "GenSigSendType" SG_ 1093 Fob_FoundIntArea 4;
BA_ "UserSigValidity" SG_ 1093 Fob_FoundIntArea 0;
BA_ "Version" SG_ 1093 Fob_FoundIntArea "17.12.00";
BA_ "Description" SG_ 1093 Fob_LearntSta "Fob key registration status information";
BA_ "GenSigSendType" SG_ 1093 Fob_LearntSta 4;
BA_ "GenSigStartValue" SG_ 1093 Fob_LearntSta 1;
BA_ "UserSigValidity" SG_ 1093 Fob_LearntSta 0;
BA_ "NetworkRequest" SG_ 1093 Fob_LearntSta 0;
BA_ "NetworkRequestHoldingTime" SG_ 1093 Fob_LearntSta 5000;
BA_ "Version" SG_ 1093 Fob_LearntSta "17.12.00";
BA_ "Description" SG_ 1093 RSPA_RFSigErrSta "Error status of RKE_BtnReq signal.



If RF frame data from FOB defferent with CAN signal data(RKE_BtnReq), 

RSPA_RFSigErrSta signal send 0x1 Signal Invalid.";
BA_ "GenSigSendType" SG_ 1093 RSPA_RFSigErrSta 4;
BA_ "UserSigValidity" SG_ 1093 RSPA_RFSigErrSta 0;
BA_ "NetworkRequest" SG_ 1093 RSPA_RFSigErrSta 0;
BA_ "NetworkRequestHoldingTime" SG_ 1093 RSPA_RFSigErrSta 5000;
BA_ "Version" SG_ 1093 RSPA_RFSigErrSta "18.05.02";
BA_ "Description" SG_ 1093 RSPA_CanErrSta "Error status of RSPA control signals.(From ADAS_PRK)";
BA_ "GenSigSendType" SG_ 1093 RSPA_CanErrSta 4;
BA_ "UserSigValidity" SG_ 1093 RSPA_CanErrSta 0;
BA_ "Version" SG_ 1093 RSPA_CanErrSta "18.05.02";
BA_ "Description" SG_ 1093 LFAnt_FltSta "This signal represents LF ANT's Error condition. 

If one of LF ANT has Fault(ex, timeout), signal has fault value.";
BA_ "GenSigSendType" SG_ 1093 LFAnt_FltSta 4;
BA_ "UserSigValidity" SG_ 1093 LFAnt_FltSta 0;
BA_ "Version" SG_ 1093 LFAnt_FltSta "17.12.00";
BA_ "Description" SG_ 1093 LFAnt_SrchSta "SMK LF Searching Status



This signal indicates that SMK operates LF searching for finding FOB.

WPC uses this signal for suspending wirless charging.";
BA_ "GenSigSendType" SG_ 1093 LFAnt_SrchSta 4;
BA_ "UserSigValidity" SG_ 1093 LFAnt_SrchSta 0;
BA_REL_ "GenSigTimeoutTime" BU_SG_REL_ RWPC SG_ 1093 LFAnt_SrchSta 1500;
BA_ "Version" SG_ 1093 LFAnt_SrchSta "17.12.00";
BA_ "Description" SG_ 1093 Auth_ISKLearnSta "This signal is State of IAU Learning";
BA_ "GenSigSendType" SG_ 1093 Auth_ISKLearnSta 4;
BA_ "UserSigValidity" SG_ 1093 Auth_ISKLearnSta 0;
BA_ "Version" SG_ 1093 Auth_ISKLearnSta "19.02.07";
BA_ "Description" SG_ 1093 RSPA_ModSta_SMK "State of RSPA system operate";
BA_ "GenSigSendType" SG_ 1093 RSPA_ModSta_SMK 4;
BA_ "UserSigValidity" SG_ 1093 RSPA_ModSta_SMK 0;
BA_REL_ "GenSigTimeoutTime" BU_SG_REL_ PSM SG_ 1093 RSPA_ModSta_SMK 1500;
BA_ "Version" SG_ 1093 RSPA_ModSta_SMK "19.03.08";
BA_ "Description" SG_ 1093 RSPA_FobBattSta "FOB Battery's Low Battery(discharge) state.

Low Battery condition is same with 'C_KeyBATDischargeWarn' Signal";
BA_ "GenSigSendType" SG_ 1093 RSPA_FobBattSta 4;
BA_ "UserSigValidity" SG_ 1093 RSPA_FobBattSta 0;
BA_ "Version" SG_ 1093 RSPA_FobBattSta "17.12.00";
BA_ "Description" SG_ 1093 Fob_BtnReleasedSta "this signal indicate fob butten released state during RSPA mode. 

##2G##IBU##SMK18##C_FobButtenReleased";
BA_ "GenSigSendType" SG_ 1093 Fob_BtnReleasedSta 4;
BA_ "UserSigValidity" SG_ 1093 Fob_BtnReleasedSta 0;
BA_ "Version" SG_ 1093 Fob_BtnReleasedSta "18.10.09";
BA_ "GenSigSendType" SG_ 1093 USM_SmrtTrnkTlgtModSta 4;
BA_ "UserSigValidity" SG_ 1093 USM_SmrtTrnkTlgtModSta 0;
BA_ "Version" SG_ 1093 USM_SmrtTrnkTlgtModSta "18.05.01";
BA_ "Description" SG_ 1093 USM_WALModSta "Current USM Setting value of Walk Away Lock(WAL) mode";
BA_ "GenSigSendType" SG_ 1093 USM_WALModSta 4;
BA_ "UserSigValidity" SG_ 1093 USM_WALModSta 0;
BA_ "Version" SG_ 1093 USM_WALModSta "17.12.00";
BA_ "Description" SG_ 1093 Fob_FoundWlcmArea "This signal indicates that there is Fob around the welcome area. 

 -to inform the door handle (Lock/Unlock touch sensor)";
BA_ "GenSigSendType" SG_ 1093 Fob_FoundWlcmArea 4;
BA_ "UserSigValidity" SG_ 1093 Fob_FoundWlcmArea 0;
BA_ "Version" SG_ 1093 Fob_FoundWlcmArea "19.03.09";
VAL_ 2223057409 LKA_OptUsmSta 0 "None LKA/LDW Option (Default)" 1 "LDW" 2 "LKA" 3 "Reserved" 4 "LDW Only (None LKA)" 5 "LDW only OFF (None LKA)" 6 "LDW/LKA OFF" 7 "Invalid" ;
VAL_ 2223057409 LKA_RcgSta 0 "Not Recognized" 1 "Left Lane Recognition" 2 "Right Lane Recognition" 3 "Full Lane Recognition" 4 "Reserved" 5 "Reserved" 6 "Reserved" 7 "Reserved" ;
VAL_ 2223057409 LKA_LHLnWrnSta 0 "No Warning" 1 "Lane Departure Warning" 2 "Reserved" 3 "Reserved" ;
VAL_ 2223057409 LKA_RHLnWrnSta 0 "No Warning" 1 "Lane Departure Warning" 2 "Reserved" 3 "Reserved" ;
VAL_ 2223057409 LKA_HndsoffSnd 0 "Off" 1 "Hands-off Sound Warning" 2 "Reserved" 3 "Reserved" ;
VAL_ 2223057409 LKA_SysIndReq 0 "Off" 1 "Unavailable_(Grey On)" 2 "Lane Recognized_(Green On)" 3 "Lane Departure_(Green Blink)" 4 "System Fail_(Orange On)" 5 "Not Calibrated_(Orange Blink)" 6 "Regulation_(Orange On)" 7 "Reserved" ;
VAL_ 2223057409 ADAS_StrTqReqVal 0 "0x0x000~0x7FD:0~2045" 2045 "0x0x000~0x7FD:0~2045" 2046 "Reserved" 2047 "Invalid" ;
VAL_ 2223057409 ADAS_ActToiSta 0 "De-activate TOI" 1 "Activate TOI" 2 "Reserved" 3 "Error indicator" ;
VAL_ 2223057409 ADAS_ToiFltSta 0 "No Fault" 1 "Fault" 2 "Reserved" 3 "Error indicatorr" ;
VAL_ 2223057409 LKA_SysWrn 0 "No Info" 1 "Reserved" 2 "Reserved" 3 "Reserved" 4 "Hands-Off Warning 1" 5 "Hands-Off Warning 2" 6 "Hands-Off Warning 3" 7 "Reserved" 8 "Reserved" 9 "System Automatic off" 10 "Reserved" 11 "Reserved" 12 "Reserved" 13 "Reserved" 14 "Reserved" 15 "System Fail" ;
VAL_ 2223057410 FCA_LO_WrnSta 0 "No Warning" 1 "Left Warning" 2 "Right Warning" 3 "Left Control" 4 "Right Control" 5 "Reserved" 6 "Reserved" 7 "Error indicator" ;
VAL_ 2223057410 LKA_UsmMod 0 "NONE" 1 "LKA 1 mode" 2 "Reserved" 3 "LDW" ;
VAL_ 2223057410 ELK_SysFlrSta 0 "No Warning" 1 "Temp, Unavailable by Camera" 2 "Temp, Unavailable by Radar" 3 "Service Required" 4 "Reserved" 5 "Reserved" 6 "Reserved" 7 "Reserved" ;
VAL_ 2223057410 ELK_SymbDisp 0 "Default" 1 "No warning" 2 "ELK Amber warning on" 3 "ELK Red warning blingking" 4 "ELK Gray warning on" 5 "Reserved" 6 "Reserved" 7 "Reserved" ;
VAL_ 2223057410 FCA_ESA_WrnSta 0 "No Warning" 1 "Reserved" 2 "Reserved" 3 "Left Control" 4 "Right Control" 5 "Reserved" 6 "Reserved" 7 "Error Indicator" ;
VAL_ 2223057410 ADAS_ActAciSta 0 "INIT" 1 "INACTIVE" 2 "ACTIVE30(ACTIVE)" 3 "ACTIVE33(Redundancy)" ;
VAL_ 2223057410 FCA_ESA_CtrlSta 0 "No Control" 1 "FCA 1st Warning" 2 "FCA w/ ESA Driver Initiated Control" 3 "FCA w/ ESA Auto Control Step 1" 4 "FCA w/ ESA Auto Control Step 2" 5 "FCA w/ ESA Auto Control Step 3" 6 "Reserved" 7 "Error Indicator" ;
VAL_ 2223057410 FCA_LS_WrnSta 0 "No Warning" 1 "Left Warning" 2 "Right Warning" 3 "Left Control" 4 "Right Control" 5 "Reserved" 6 "Reserved" 7 "Error indicator" ;
VAL_ 2223057410 ADAS_Damping_Gain 0 "Reserved" 1 "Reserved" 2 "Reserved" 3 "0x3~0xC8:3 ~ 200%" 200 "0x3~0xC8:3 ~ 200%" 201 "Reserved" 202 "Reserved" 203 "Reserved" 204 "Reserved" 205 "Reserved" 206 "Reserved" 207 "Reserved" 208 "Reserved" 209 "Reserved" 210 "Reserved" 211 "Reserved" 212 "Reserved" 213 "Reserved" 214 "Reserved" 215 "Reserved" 216 "Reserved" 217 "Reserved" 218 "Reserved" 219 "Reserved" 220 "Reserved" 221 "Reserved" 222 "Reserved" 223 "Reserved" 224 "Reserved" 225 "Reserved" 226 "Reserved" 227 "Reserved" 228 "Reserved" 229 "Reserved" 230 "Reserved" 231 "Reserved" 232 "Reserved" 233 "Reserved" 234 "Reserved" 235 "Reserved" 236 "Reserved" 237 "Reserved" 238 "Reserved" 239 "Reserved" 240 "Reserved" 241 "Reserved" 242 "Reserved" 243 "Reserved" 244 "Reserved" 245 "Reserved" 246 "Reserved" 247 "Reserved" 248 "Reserved" 249 "Reserved" 250 "Reserved" 251 "Reserved" 252 "Reserved" 253 "Reserved" 254 "Reserved" 255 "Reserved" ;
VAL_ 2260843009 BCW_Sta 0 "Default" 1 "System is Off" 2 "System Passive" 3 "System Active" 4 "System Failure" 5 "System Blockage" 6 "System minor failure" 7 "Reserved" 8 "Reserved" 9 "Reserved" 10 "Reserved" 11 "Reserved" 12 "Reserved" 13 "Reserved" 14 "Reserved" ;
VAL_ 2260843009 BCW_LtIndSta 0 "Indicator output off" 1 "Indicator on (information)" 2 "Indicator blinking(warning)" 3 "Error Indicator" ;
VAL_ 2260843009 BCW_RtIndSta 0 "Indicator output off" 1 "Indicator on (information)" 2 "Indicator blinking(warning)" 3 "Error Indicator" ;
VAL_ 2260843009 BCW_LtSndWrngSta 0 "Speaker is Off" 1 "Speaker On" 2 "Not used" 3 "Error Indicator" ;
VAL_ 2260843009 BCW_RtSndWrngSta 0 "Speaker is Off" 1 "Speaker On" 2 "Not used" 3 "Error Indicator" ;
VAL_ 2260843009 BCW_SnstvtyModRetVal 0 "Default" 1 "Late" 2 "Normal" 3 "Early" 4 "Reserved" 5 "Reserved" 6 "Reserved" 7 "Invalid" ;
VAL_ 2260843009 BCW_IndSta 0 "Default" 1 "Normal" 2 "Inidicator Failure" 3 "Reserved" ;
VAL_ 2260843010 BCA_Sta 0 "Default" 1 "BCA Function is off" 2 "BCA Function is passive" 3 "BCA Function active" 4 "BCA Function failure" 5 "BCA Function Blockage" 6 ":BCA Function minor failure" 7 "Failure low priority" 8 "Reserved" 9 "Reserved" 10 "Reserved" 11 "Reserved" 12 "Reserved" 13 "Reserved" 14 "Reserved" ;
VAL_ 2260843010 BCA_DRV_WarnSta 0 "No Warning" 1 "Left Warning" 2 "Right Warning" 3 "Left Control (Braking)" 4 "Right Control (Braking)" 5 "Left Control (Steering)" 6 "Right Control (Steering)" 7 "Error Indicator" ;
VAL_ 2260843010 BCA_Plus_BrkCmdSta 0 "BCA_Plus Brake off" 1 "BCA_Plus Brake on" 2 "Not used" 3 "Error Indicator" ;
VAL_ 2260843010 BCA_Plus_LtWrngSta 0 "BCA_Plus Left Warning is Off" 1 "BCA_Plus Left Warning is On" 2 "BCA_Plus Left Control is On" 3 "BCA_Plus Left Control is Ended" ;
VAL_ 2260843010 BCA_Plus_RtWrngSta 0 "BCA_Plus Right Warning is Off" 1 "BCA_Plus Right Warning is On" 2 "BCA_Plus Right Control is On" 3 "BCA_Plus Right Control is Ended" ;
VAL_ 2260843010 BCA_OnOffEquipSta 0 "Default" 1 "Off" 2 "Warning" 3 "Assist" 4 "Reserved" 5 "Reserved" 6 "Reserved" 7 "Invalid" ;
VAL_ 2260843011 OSMrrLamp_LtIndSta 0 "Indicator output off" 1 "Indicator on (information)" 2 "Indicator blinking(warning)" 3 "Indicator output check" ;
VAL_ 2260843011 OSMrrLamp_RtIndSta 0 "Indicator output off" 1 "Indicator on (information)" 2 "Indicator blinking(warning)" 3 "Indicator output check" ;
VAL_ 1100 APSM_LegRestCloseSta 0 "Default" 1 "Off" 2 "On(Close)" 3 "Invalid" ;
VAL_ 1100 APSM_ReadingModeState 0 "Off" 1 "Stop" 2 "Moving" 3 "Finish" 4 "RESERVED" 5 "RESERVED" 6 "RESERVED" 7 "Invalid" ;
VAL_ 1100 APSM_CoveringMirrorPosition 0 "Default" 1 "No" 2 "Covering" 3 "Ivalid" ;
VAL_ 1095 ATS_BeepSound 0 "Off" 1 "On" 2 "Reserved" 3 "Invalid" ;
VAL_ 1095 ATS_RRMsgTimeSW 0 "Default" 1 "Short" 2 "Medium" 3 "Long" 4 "Reserved" 5 "Reserved" 6 "Reserved" 7 "Invalid" ;
VAL_ 1095 ATS_FAUMsgModeSW 0 "Default" 1 "Off" 2 "On" 3 "Invalid" ;
VAL_ 1095 ATS_FAUMsgHeatModeSW 0 "Default" 1 "Off" 2 "On" 3 "Invalid" ;
VAL_ 1095 ATS_RLMsgMod1SW 0 "Default" 1 "Short On" 2 "Long On" 3 "Invalid" ;
VAL_ 1095 ATS_RWPC_RWPCNValueSet 0 "Default" 1 "Off" 2 "On" 3 "Invalid" ;
VAL_ 1095 ATS_RLMsgMod2SW 0 "Default" 1 "Short On" 2 "Long On" 3 "Invalid" ;
VAL_ 1095 ATS_RLMsgMod3SW 0 "Default" 1 "Short On" 2 "Long On" 3 "Invalid" ;
VAL_ 1095 ATS_RLMsgMod4SW 0 "Default" 1 "Short On" 2 "Long On" 3 "Invalid" ;
VAL_ 1095 ATS_RRMsgMod1SW 0 "Default" 1 "Short On" 2 "Long On" 3 "Invalid" ;
VAL_ 1095 ATS_RRMsgMod2SW 0 "Default" 1 "Short On" 2 "Long On" 3 "Invalid" ;
VAL_ 1095 ATS_RRMsgMod3SW 0 "Default" 1 "Short On" 2 "Long On" 3 "Invalid" ;
VAL_ 1095 ATS_RRMsgMod4SW 0 "Default" 1 "Short On" 2 "Long On" 3 "Invalid" ;
VAL_ 1095 ATS_RLEasyAccessSW 0 "Default" 1 "Off" 2 "On" 3 "Invalid" ;
VAL_ 1095 ATS_RREasyAccessSW 0 "Default" 1 "Off" 2 "On" 3 "Invalid" ;
VAL_ 1095 ATS_RLMsgTimeSW 0 "Default" 1 "Short" 2 "Medium" 3 "Long" 4 "Reserved" 5 "Reserved" 6 "Reserved" 7 "Invalid" ;
VAL_ 527 ATS_DrvStRseFwdBtn 0 "Default" 1 "Off" 2 "On" 3 "Reserved" ;
VAL_ 527 ATS_DrvStRseBwdBtn 0 "Default" 1 "Off" 2 "On" 3 "Reserved" ;
VAL_ 527 ATS_RRRestModBtn 0 "Default" 1 "Off" 2 "On" 3 "Reserved" ;
VAL_ 527 ATS_RRResetModBtn 0 "Default" 1 "Off" 2 "On" 3 "Reserved" ;
VAL_ 527 ATS_RRAvWtcModBtn 0 "Default" 1 "Off" 2 "On" 3 "Reserved" ;
VAL_ 527 ATS_RRReadingModBtn 0 "Default" 1 "Off" 2 "On" 3 "Reserved" ;
VAL_ 527 ATS_RLRestModBtn 0 "Default" 1 "Off" 2 "On" 3 "Reserved" ;
VAL_ 527 ATS_RLResetModBtn 0 "Default" 1 "Off" 2 "On" 3 "Reserved" ;
VAL_ 1090 BCM_CntryConfgTyp 0 "Dom" 1 "Na" 2 "Eu" 3 "Aus" 4 "China" 5 "Gen,Mes" 6 "India" 7 "Reserved" 8 "Reserved" 9 "Reserved" 10 "Reserved" 11 "Reserved" 12 "Reserved" 13 "Reserved" 14 "Not Used" 15 "Error Indicator" ;
VAL_ 1090 BCM_SmkOptTyp 0 "Non SMK Option" 1 "SMK Option" 2 "Not Used" 3 "Error Indicator" ;
VAL_ 1090 BCM_SunRoofOptTyp 0 "NONE" 1 "Sunroof applied" 2 "reserved" 3 "Invalid" ;
VAL_ 1090 BCM_SafetyWdwOptTyp 0 "NONE" 1 "All Safety Window Applied" 2 "Driver Safety Window Applied" 3 "Invalid" ;
VAL_ 1090 Window_DrvrSdWdwSta_BCM 0 "Window Close" 1 "Window Open" 2 "Not Used" 3 "Error Indicator" ;
VAL_ 1090 Window_AsstSdWdwSta_BCM 0 "Window Close" 1 "Window Open" 2 "Not Used" 3 "Error Indicator" ;
VAL_ 1090 Window_RrLftWdwSta_BCM 0 "Window Close" 1 "Window Open" 2 "Not Used" 3 "Error Indicator" ;
VAL_ 1090 Window_RrRtWdwSta_BCM 0 "Window Close" 1 "Window Open" 2 "Not Used" 3 "Error Indicator" ;
VAL_ 1090 SunRoof_GlassPosSta 0 "Glass Tilt up" 1 "Glass Vent area" 2 "Glass Anti pinch in vent" 3 "Glass Fully close" 4 "Glass Anti pinch in partially slide" 5 "Glass Partially slide" 6 "Glass Fully open" 7 "Glass Uninitialized" 8 "Reserved" 9 "Reserved" 10 "Reserved" 11 "Reserved" 12 "Reserved" 13 "Reserved" 14 "Reserved" 15 "invalid" ;
VAL_ 1090 SunRoof_BlindPosSta 0 "BLIND_HALF_OPEN" 1 "BLIND_LESS_THEN_HALF_OPEN" 2 "BLIND_ANTIPINCH_LESS_THAN_HALF_OPEN" 3 "BLIND_FULLY_CLOSE" 4 "BLIND_ANTIPINCH_MORE_THAN_HALF_OPEN" 5 "BLIND_MORE_THAN_HALF_OPEN" 6 "BLIND_FULLY_OPEN" 7 "BLIND_UNINITIALIZED" 8 "Reserved" 9 "Reserved" 10 "Reserved" 11 "Reserved" 12 "Reserved" 13 "Reserved" 14 "Reserved" 15 "invalid" ;
VAL_ 1090 SunRoof_GlassErrSta 0 "Glass No error" 1 "Glass Thermal Protection Active" 2 "Glass Initialized Status" 3 "Glass Undefined ECU Error" 4 "Glass Switch Error" 5 "Glass Voltage error" 6 "Complex Error" 7 "invalid" ;
VAL_ 1090 SunRoof_BlindErrSta 0 "Roll Blind No error" 1 "Roll Blind Thermal Protection Active" 2 "Roll Blind Initialized Status" 3 "Roll Blind Undefined ECU Error" 4 "Roll Blind Switch Error" 5 "Roll Blind Voltage error" 6 "Complex Error" 7 "invalid" ;
VAL_ 1098 Window_RrLftWdwSwSta_RrRt 0 "No Action" 1 "Manual Down" 2 "Manual Up" 3 "Stuck" 4 "Not Used" 5 "Auto Down" 6 "Auto Up" 7 "Invalid" ;
VAL_ 1098 Window_RrRtWdwSwSta_RrLft 0 "No Action" 1 "Manual Down" 2 "Manual Up" 3 "Stuck" 4 "Not Used" 5 "Auto Down" 6 "Auto Up" 7 "Invalid" ;
VAL_ 1124 Window_DrvrSdWdwActSta 0 "No Action" 1 "Manual Down" 2 "Manual Up" 3 "RLY Stuck/FET Error" 4 "Motor Stop Error" 5 "Auto Down" 6 "Auto Up" 7 "Reverse" 8 "Reserved" 9 "Reserved" 10 "Reserved" 11 "Reserved" 12 "Reserved" 13 "Reserved" 14 "Reserved" 15 "Invalid" ;
VAL_ 1124 Window_AsstSdWdwActSta 0 "No Action" 1 "Manual Down" 2 "Manual Up" 3 "RLY Stuck/FET Error" 4 "Motor Stop Error" 5 "Auto Down" 6 "Auto Up" 7 "Reverse" 8 "Reserved" 9 "Reserved" 10 "Reserved" 11 "Reserved" 12 "Reserved" 13 "Reserved" 14 "Reserved" 15 "Invalid" ;
VAL_ 1124 Window_RrLftWdwActSta 0 "No Action" 1 "Manual Down" 2 "Manual Up" 3 "RLY Stuck/FET Error" 4 "Motor Stop Error" 5 "Auto Down" 6 "Auto Up" 7 "Reverse" 8 "Reserved" 9 "Reserved" 10 "Reserved" 11 "Reserved" 12 "Reserved" 13 "Reserved" 14 "Reserved" 15 "Invalid" ;
VAL_ 1124 Window_RrRtWdwActSta 0 "No Action" 1 "Manual Down" 2 "Manual Up" 3 "RLY Stuck/FET Error" 4 "Motor Stop Error" 5 "Auto Down" 6 "Auto Up" 7 "Reverse" 8 "Reserved" 9 "Reserved" 10 "Reserved" 11 "Reserved" 12 "Reserved" 13 "Reserved" 14 "Reserved" 15 "Invalid" ;
VAL_ 1124 Window_DrvrSdWdwDetailOpnSta 0 "Full Close" 1 "1~30% Open" 2 "31~99% Open" 3 "Full Open" 4 "Reserved" 5 "Reserved" 6 "Reserved" 7 "Invalid" ;
VAL_ 1124 Window_AsstSdWdwDetailOpnSta 0 "Full Close" 1 "1~30% Open" 2 "31~99% Open" 3 "Full Open" 4 "Reserved" 5 "Reserved" 6 "Reserved" 7 "Invalid" ;
VAL_ 1124 Window_DrvrSdWdwErrAntPinch 0 "Calibrated" 1 "De-Calibrated" 2 "Reserved" 3 "Invalid" ;
VAL_ 1124 Window_RrLftWdwDetailOpnSta 0 "Full Close" 1 "1~30% Open" 2 "31~99% Open" 3 "Full Open" 4 "Reserved" 5 "Reserved" 6 "Reserved" 7 "Invalid" ;
VAL_ 1124 Window_RrRtWdwDetailOpnSta 0 "Full Close" 1 "1~30% Open" 2 "31~99% Open" 3 "Full Open" 4 "Reserved" 5 "Reserved" 6 "Reserved" 7 "Invalid" ;
VAL_ 1124 Window_AsstSdWdwErrAntPinch 0 "Calibrated" 1 "De-Calibrated" 2 "Reserved" 3 "Invalid" ;
VAL_ 1124 Window_RrLftWdwErrAntPinch 0 "Calibrated" 1 "De-Calibrated" 2 "Reserved" 3 "Invalid" ;
VAL_ 1124 Window_RrRtWdwErrAntPinch 0 "Calibrated" 1 "De-Calibrated" 2 "Reserved" 3 "Invalid" ;
VAL_ 1124 SunRoof_RrBlindPosSta 0 "BLIND_HALF_OPEN" 1 "BLIND_LESS_THEN_HALF_OPEN" 2 "BLIND_ANTIPINCH_LESS_THAN_HALF_OPEN" 3 "BLIND_FULLY_CLOSE" 4 "BLIND_ANTIPINCH_MORE_THAN_HALF_OPEN" 5 "BLIND_MORE_THAN_HALF_OPEN" 6 "BLIND_FULLY_OPEN" 7 "BLIND_UNINITIALIZED" 8 "Reserved" 9 "Reserved" 10 "Reserved" 11 "Reserved" 12 "Reserved" 13 "Reserved" 14 "Reserved" 15 "invalid" ;
VAL_ 1124 Window_RrLftWdwSwSta 0 "No Action" 1 "Manual Down" 2 "Manual Up" 3 "Stuck" 4 "Not Used" 5 "Auto Down" 6 "Auto Up" 7 "Invalid" ;
VAL_ 1124 Window_RrRtWdwSwSta 0 "No Action" 1 "Manual Down" 2 "Manual Up" 3 "Stuck" 4 "Not Used" 5 "Auto Down" 6 "Auto Up" 7 "Invalid" ;
VAL_ 2395189505 DATC_RrBlwDis 0 "OFF" 1 "Blank Display(Blower 단수 미표시, 예)Auto 시)" 2 "1 Step" 3 "2 Step" 4 "3 Step" 5 "4 Step" 6 "5 Step" 7 "6 Step" 8 "7 Step" 9 "8 Step" 10 "BLOWER AUTO" 11 "Reserved" 12 "Reserved" 13 "Reserved" 14 "Reserved" 15 "Error Indicator" ;
VAL_ 2395189505 DATC_ArClnStepClr 0 "Default (Initial Value)" 1 "Mono Color" 2 "Blue Color" 3 "Green Color" 4 "Orange Color" 5 "Red Color" 6 "Yellow Color" 7 "Reserved" 8 "Reserved" 9 "Reserved" 10 "Reserved" 11 "Reserved" 12 "Reserved" 13 "Reserved" 14 "Gray Color (Deactivate)" 15 "Invalid" ;
VAL_ 2395189505 DATC_ArClnSmblTyp 0 "Default" 1 "Blank (Initial Display)" 2 "Wood" 3 "Wood & Fixed Arrow" 4 "Wood & Rotating Arrow" 5 "White Wood & Fixed Arrow" 6 "White Wood & Rotating Arrow" 7 "Invaild" ;
VAL_ 2395189505 DATC_AfterBlowUSMSta 0 "Default" 1 "After Blow USM OFF" 2 "After Blow USM ON" 3 "Error Indicator" ;
VAL_ 2395189505 DATC_SchdldVntUSMSta 0 "Default" 1 "OFF" 2 "ON" 3 "Error Indicator" ;
VAL_ 2395189505 DATC_SchdldVntHrSta 0 "Default" 1 "0hr" 2 "1hr" 3 "2hr" 4 "3hr" 5 "4hr" 6 "5hr" 7 "6hr" 8 "7hr" 9 "8hr" 10 "9hr" 11 "10hr" 12 "11hr" 13 "12hr" 14 "13hr" 15 "14hr" 16 "15hr" 17 "16hr" 18 "17hr" 19 "18hr" 20 "19hr" 21 "20hr" 22 "21hr" 23 "22hr" 24 "23hr" 25 "Reserved" 26 "Reserved" 27 "Reserved" 28 "Reserved" 29 "Reserved" 30 "Reserved" 31 "Error Indicator" ;
VAL_ 2395189505 DATC_SchdldVntMinSta 0 "Default" 1 "0 Min" 2 "10 Min" 3 "20 Min" 4 "30 Min" 5 "40 Min" 6 "50 Min" 7 "Error Indicator" ;
VAL_ 1127 DPSS_StExtFwdMvBtn 0 "Default" 1 "Off" 2 "On" 3 "Invalid" ;
VAL_ 1127 DPSS_StExtBwdMvBtn 0 "Default" 1 "Off" 2 "On" 3 "Invaild" ;
VAL_ 1127 DPSS_StSldFwdMvBtn 0 "Default" 1 "Off" 2 "On" 3 "Invalid" ;
VAL_ 1127 DPSS_StSldBwdMvBtn 0 "Default" 1 "Off" 2 "On" 3 "Invalid" ;
VAL_ 1127 DPSS_StRclFwdMvBtn 0 "Default" 1 "Off" 2 "On" 3 "Invaild" ;
VAL_ 1127 DPSS_StRclBwdMvBtn 0 "Default" 1 "Off" 2 "On" 3 "Invalid" ;
VAL_ 1127 DPSS_StHgtUpMvBtn 0 "Default" 1 "Off" 2 "On" 3 "Invaild" ;
VAL_ 1127 DPSS_StHgtDnMvBtn 0 "Default" 1 "Off" 2 "On" 3 "Invalid" ;
VAL_ 1127 DPSS_StTltUpMvBtn 0 "Default" 1 "Off" 2 "On" 3 "Invalid" ;
VAL_ 1127 DPSS_StTltDnMvBtn 0 "Default" 1 "Off" 2 "On" 3 "Invalid" ;
VAL_ 1127 DPSS_StHRestUpMvBtn 0 "Default" 1 "Off" 2 "On" 3 "Invalid" ;
VAL_ 1127 DPSS_StHRestDnMvBtn 0 "Default" 1 "Off" 2 "On" 3 "Invalid" ;
VAL_ 1127 DPSS_StHRestFwdMvBtn 0 "Default" 1 "Off" 2 "On" 3 "Invalid" ;
VAL_ 1127 DPSS_StHRestBwdMvBtn 0 "Default" 1 "Off" 2 "On" 3 "Invalid" ;
VAL_ 1127 DPSS_StLegUpMvBtn 0 "Default" 1 "Off" 2 "On" 3 "Invalid" ;
VAL_ 1127 DPSS_StLegDnMvBtn 0 "Default" 1 "Off" 2 "On" 3 "Invalid" ;
VAL_ 1127 DPSS_StRlxModeBtn 0 "Default" 1 "Off" 2 "On" 3 "Invalid" ;
VAL_ 1127 DPSS_StRlxReturnBtn 0 "Default" 1 "Off" 2 "On" 3 "Invalid" ;
VAL_ 1127 DPSS_RlxStTltUpMvBtn 0 "Default" 1 "Off" 2 "On" 3 "Invalid" ;
VAL_ 1127 DPSS_RlxStTltDnMvBtn 0 "Default" 1 "Off" 2 "On" 3 "Invalid" ;
VAL_ 1128 DPSS_LumbarUpSw 0 "Default" 1 "Off" 2 "On" 3 "Invalid" ;
VAL_ 1128 DPSS_LumbarMidSw 0 "Default" 1 "Off" 2 "On" 3 "Invalid" ;
VAL_ 1128 DPSS_LumbarLowSw 0 "Default" 1 "Off" 2 "On" 3 "Invalid" ;
VAL_ 1128 DPSS_LumbarDefSw 0 "Default" 1 "Off" 2 "On" 3 "Invalid" ;
VAL_ 1128 DPSS_BolsterInfSw 0 "Default" 1 "Off" 2 "On" 3 "Invalid" ;
VAL_ 1128 DPSS_BolsterDefSw 0 "Default" 1 "Off" 2 "On" 3 "Invalid" ;
VAL_ 1128 DPSS_ActiveSw 0 "Default" 1 "Off" 2 "On" 3 "Invalid" ;
VAL_ 1128 DPSS_CushInfSw 0 "Default" 1 "Off" 2 "On" 3 "Invaild" ;
VAL_ 1128 DPSS_CushDefSw 0 "Default" 1 "Off" 2 "On" 3 "Invalid" ;
VAL_ 1129 DPSS_SldTch 0 "Default" 1 "Off" 2 "On" 3 "Invalid" ;
VAL_ 1129 DPSS_RclTch 0 "Default" 1 "Off" 2 "On" 3 "Invalid" ;
VAL_ 1129 DPSS_ExtTch 0 "Default" 1 "Off" 2 "On" 3 "Invalid" ;
VAL_ 1129 DPSS_LmbrTch 0 "Default" 1 "Off" 2 "On" 3 "Invalid" ;
VAL_ 1129 DPSS_CushOnOffTch 0 "Default" 1 "Off" 2 "On(Off State)" 3 "On(Mode1 State)" 4 "On(Mode2 State)" 5 "On(Mode3 State)" 6 "Reserved" 7 "Invalid" ;
VAL_ 1129 DPSS_HRestTch 0 "Default" 1 "Off" 2 "On" 3 "Invalid" ;
VAL_ 1105 FCS_FrLftStClrSwSta 0 "Default" 1 "Off" 2 "On" 3 "Error Indicator" ;
VAL_ 1105 FCS_DrvDrAtClsSwSta 0 "Default" 1 "OFF" 2 "ON" 3 "Error Indicator" ;
VAL_ 1105 FCS_AstDrAtClsSwSta 0 "Default" 1 "Off" 2 "On" 3 "Error Indicator" ;
VAL_ 1105 FCS_DrvModeSwSta 0 "Default" 1 "Off" 2 "On" 3 "Error Indicator" ;
VAL_ 1105 FCS_PDWSwSta 0 "Default" 1 "Off" 2 "On" 3 "Error Indicator" ;
VAL_ 1105 FCS_FrLftStHtrSwSta 0 "Default" 1 "Off" 2 "On" 3 "Error Indicator" ;
VAL_ 1105 FCS_FrRtStClrSwSta 0 "Default" 1 "Off" 2 "On" 3 "Error Indicator" ;
VAL_ 1105 FCS_FrRtStHtrSwSta 0 "Default" 1 "Off" 2 "On" 3 "Error Indicator" ;
VAL_ 2378399489 GATEWAY_MM_STS 0 "Default" 1 "Inactive" 2 "Active" 3 "Bus Off" 4 "Reserved" 5 "Reserved" 6 "Reserved" 7 "Error" ;
VAL_ 2378399489 GATEWAY_HS_B_STS 0 "Default" 1 "Inactive" 2 "Active" 3 "Bus Off" 4 "Reserved" 5 "Reserved" 6 "Reserved" 7 "Error" ;
VAL_ 2378399489 GATEWAY_HS_D_STS 0 "Default" 1 "DiagMsgNotExist" 2 "DiagMsgExist" 3 "Reserved" 4 "Reserved" 5 "Reserved" 6 "Reserved" 7 "Error" ;
VAL_ 2378399489 GATEWAY_FD_P_STS 0 "Default" 1 "Inactive" 2 "Active" 3 "Bus Off" 4 "Reserved" 5 "Reserved" 6 "Reserved" 7 "Error" ;
VAL_ 2378399489 GATEWAY_FD_C_STS 0 "Default" 1 "Inactive" 2 "Active" 3 "Bus Off" 4 "Reserved" 5 "Reserved" 6 "Reserved" 7 "Error" ;
VAL_ 2378399489 GATEWAY_FD_E_STS 0 "Default" 1 "Inactive" 2 "Active" 3 "Bus Off" 4 "Reserved" 5 "Reserved" 6 "Reserved" 7 "Error" ;
VAL_ 2378399489 GATEWAY_FD_I_STS 0 "Default" 1 "Inactive" 2 "Active" 3 "Bus Off" 4 "Reserved" 5 "Reserved" 6 "Reserved" 7 "Error" ;
VAL_ 2563128577 AMP_SetMaxMainVolStep 0 "35 Step" 1 "45 Steps" 2 "75 Steps" 3 "Invalid" ;
VAL_ 2449771009 ODS_OccClassSta 1 "Class1" 2 "Class2" 4 "Indeterminate" ;
VAL_ 2449771009 ODS_SBRClassSta 0 "Empty / Indeterminate" 1 "Occupied" ;
VAL_ 1089 PSM_RrRtSldStrtSta 0 "OFF" 1 "ON(SLIDE START)" 2 "STOP" 3 "FINISH" ;
VAL_ 1089 RRPSM_APSMBzrOnReq 0 "off" 1 "on (1)" 2 "on (2)" 3 "reserved" ;
VAL_ 1089 RRPSM_LimSetSta 0 "Default" 1 "Initialized" 2 "Not Initialized" 3 "reserved" ;
VAL_ 1089 RRPSM_SeatTyp 0 "Default" 1 "SEDAN" 2 "LIMOUSINE" 3 "Ivalid" ;
VAL_ 1089 RRPSM_RRStEsyAcsUSMSta 0 "Default" 1 "Off" 2 "On" 3 "Invalid" ;
VAL_ 1089 RRPSM_LegSupportOpt 0 "Default" 1 "Off" 2 "On(legsupport OPT)" 3 "Invalid" ;
VAL_ 1089 RRPSM_RRSlidePosition 0 "0x0x00~0xFE:POSITION" 254 "0x0x00~0xFE:POSITION" 255 "invalid" ;
VAL_ 1089 RRPSM_RearModeState 0 "Default" 1 "Off" 2 "Relax Mode" 3 "Relax Mode(rear only)" 4 "Return Mode" 5 "Monitor Mode" 6 "Reading Mode" 7 "Reserved" 8 "Reserved" 9 "Reserved" 10 "Reserved" 11 "Reserved" 12 "Reserved" 13 "Reserved" 14 "Reserved" 15 "Invalid" ;
VAL_ 1089 RRPSM_RRLegRestPosition 0 "0x0x00~0xFE:POSITION" 254 "0x0x00~0xFE:POSITION" 255 "invalid" ;
VAL_ 1089 PSM_RearRightLegSpprtPosVal 0 "0≤x≤30" 1 "30<x≤45" 2 "45<x≤60" 3 "60<x" 4 "reserved" 5 "reserved" 6 "reserved" 7 "invalid" ;
VAL_ 1107 RR_SHVU_SeatOptSta 0 "Init" 1 "Heater only 2step" 2 "Heater only 3step" 3 "Vent only 2step" 4 "Vent only 3step" 5 "Heater and Vent 2step" 6 "Heater and Vent 3step" 7 "Invalid" ;
VAL_ 1107 RR_SHVU_HtAutoDownRVal 0 "Init" 1 "Disable" 2 "Enable" 3 "Invalid" ;
VAL_ 1107 RR_SHVU_VntTurboSta 0 "Off(Initial Value)" 1 "Turbo Mode" 2 "Not Used" 3 "Error Indicator" ;
VAL_ 1107 RR_SHVU_SeatHtOperSta 0 "Init" 1 "Unused" 2 "Heater & Vent OFF" 3 "Vent Low" 4 "Vent Mid" 5 "Vent High" 6 "Heater Low" 7 "Heater Mid" 8 "Heater High" 9 "Unused" 10 "Unused" 11 "Unused" 12 "Unused" 13 "Unused" 14 "Unused" 15 "Invalid" ;
VAL_ 1107 RR_SHVU_SeatOptSta_RHD 0 "Init" 1 "Heater only 2step" 2 "Heater only 3step" 3 "Vent only 2step" 4 "Vent only 3step" 5 "Heater and Vent 2step" 6 "Heater and Vent 3step" 7 "Invalid" ;
VAL_ 1107 RR_SHVU_SeatHtOperSta_RHD 0 "Init" 1 "Unused" 2 "Heater & Vent OFF" 3 "Vent Low" 4 "Vent Mid" 5 "Vent High" 6 "Heater Low" 7 "Heater Mid" 8 "Heater High" 9 "Unused" 10 "Unused" 11 "Unused" 12 "Unused" 13 "Unused" 14 "Unused" 15 "Invalid" ;
VAL_ 1107 RR_SHVU_HtSwHiIndSta_RHD 0 "OFF" 1 "ON" 2 "Not used" 3 "Error indicator" ;
VAL_ 1107 RR_SHVU_HtSwMidIndSta_RHD 0 "OFF" 1 "ON" 2 "Not used" 3 "Error Indicator" ;
VAL_ 1107 RR_SHVU_HtSwLowIndSta_RHD 0 "OFF" 1 "ON" 2 "Not used" 3 "Error Indicator" ;
VAL_ 1107 RR_SHVU_VntSwHiIndSta_RHD 0 "OFF" 1 "ON" 2 "Not used" 3 "Error Indictor" ;
VAL_ 1107 RR_SHVU_VntSwMidIndSta_RHD 0 "OFF" 1 "ON" 2 "Not used" 3 "Error Indicator" ;
VAL_ 1107 RR_SHVU_VntSwLowIndSta_RHD 0 "OFF" 1 "ON" 2 "Not used" 3 "Error Indicator" ;
VAL_ 1107 RR_SHVU_SeatHtFail 0 "No Fail(Initial Value)" 1 "Fail" 2 "Not Used" 3 "Error Indicator" ;
VAL_ 1092 SSB_StrtStpBtnSw1Sta 0 "Released" 1 "Pressed" 2 "Not Used" 3 "Error Indicator" ;
VAL_ 1092 SSB_StrtStpBtnSw2Sta 0 "Released" 1 "Pressed" 2 "Not Used" 3 "Error Indicator" ;
VAL_ 1092 SMK_TrmnlCtrlSta 0 "Off" 1 "ACC" 2 "IGN" 3 "START" 4 "Reserved/" 5 "Reseved" 6 "Reseved" 7 "Reserved" 8 "Reserved" 9 "Reserved" 10 "Reserved" 11 "Reserved" 12 "Reserved" 13 "Reserved" 14 "Not Used" 15 "Error Indicator" ;
VAL_ 1092 SMK_TrmnlMngrSta 0 "Off" 1 "OFF_TO_START" 16 "ENGINE_RUNNING" 17 "Reserved" 18 "Reserved" 19 "Reserved" 20 "Reserved" 21 "Reserved" 22 "Reserved" 23 "Reserved" 24 "Reserved" 25 "Reserved" 26 "Reserved" 27 "Reserved" 28 "Reserved" 29 "Reserved" 30 "Not Used" 31 "Error Indicator" 2 "WAIT_ESCL_UNLOCK_ACC" 3 "ACC" 4 "ACC_SEARCH" 5 "ACC_TO_START" 6 "IGN" 7 "IGN_SEARCH" 8 "WAIT_ESCL_UNLOCK_OFF_TO_START" 9 "WAIT_ESCL_UNLOCK_START" 10 "WAIT_IGN1_ACC" 11 "WAIT_IGN1_ACC_SEARCH" 12 "WAIT_IGN1_ACC_TO_START" 13 "WAIT_IGN1_UNLOCK_OFF_TO_START" 14 "WAIT_IGN1_UNLOCK_START" 15 "START" ;
VAL_ 1092 SMK_AuthSta 0 "No Auth" 1 "Preauthentication" 2 "Authentication" 3 "Fast Restart" 4 "Reserved" 5 "Reseved" 6 "Not Used" 7 "Error Indicator" ;
VAL_ 1092 SMK_Ign1InSta 0 "IGN1 Off" 1 "IGN1 On" 2 "Not Used" 3 "Error Indicator" ;
VAL_ 1092 SMK_Ign1RlySta 0 "Off" 1 "On" 2 "Not Used" 3 "Error Indicator" ;
VAL_ 1092 SMK_Ign2InSta 0 "IGN2 Off" 1 "IGN2 On" 2 "Not Used" 3 "Error Indicator" ;
VAL_ 1092 SMK_Ign2RlySta 0 "Off" 1 "On" 2 "Not Used" 3 "Error Indicator" ;
VAL_ 1092 SMK_StrtFdbckSta 0 "Off" 1 "On" 2 "Not Used" 3 "Error Indicator" ;
VAL_ 1092 SMK_StrtrRlyOutSta 0 "Starter Relay Output Off" 1 "Starter Relay Output On" 2 "Not Used" 3 "Error Indicator" ;
VAL_ 1092 SMK_AccInSta 0 "ACC OFF" 1 "ACC ON" 2 "Not Used" 3 "Error Indicator" ;
VAL_ 1092 SMK_AccRlySta 0 "Off" 1 "On" 2 "Not Used" 3 "Error Indicator" ;
VAL_ 1092 SMK_CLUAccIndOnReq 0 "Cluster ACC Indicator Off" 1 "Cluster ACC Indicator On" 2 "Not Used" 3 "Error Indicator" ;
VAL_ 1092 SMK_TlEngRunSta 0 "Off" 1 "Tele Engine Running" 2 "Not Used" 3 "Error Indicator" ;
VAL_ 1092 SMK_TlCrnkModSta 0 "Normal Mode" 1 "Tele Cranking Mode" 2 "Not Used" 3 "Error Indicator" ;
VAL_ 1092 SMK_RmtKeyEngRunSta 0 "Off" 1 "Remote Key Engine Running" 2 "Not Used" 3 "Error Indicator" ;
VAL_ 1108 ESCL_EsclMngrSta 0 "NOT_POWER_SUPPLIED" 1 "POWER_SUPPLIED_FOR_UNLOCK" 2 "POWER_SUPPLIED_FOR_LOCK" 3 "PWR_SUPPL_FOR_LEARNIGN_NEUTRAL" 4 "UNLOCK_IN_PROGRESS" 5 "LOCK_IN_PROGRESS" 6 "POWER_OFF_CONFIRMATION" 7 "ANTI_SCANNING" 8 "Reserved" 9 "Reserved" 10 "Reserved" 11 "Reserved" 12 "Reserved" 13 "Reserved" 14 "Not Used" 15 "Error Indicator" ;
VAL_ 1108 ESCL_EsclPwrSupSta 0 "Off" 1 "On" 2 "Not Used" 3 "Error Indicator" ;
VAL_ 1108 ESCL_EsclEnaSta 0 "Off" 1 "On" 2 "Not Used" 3 "Error Indicator" ;
VAL_ 1108 ESCL_EsclUnitSta 0 "Retry (Fault)" 1 "In progress (Busy)" 2 "Reserved" 3 "OK" 4 "Unknown" 5 "Reseved" 6 "Not Used" 7 "Error Indicator" ;
VAL_ 1108 ESCL_EsclBoltSta 0 "Intermediate" 1 "Locked" 2 "Unlocked" 3 "Failure" 4 "Unknown" 5 "Reseved" 6 "Not Used" 7 "Error Indicator" ;
VAL_ 1108 Fob_FoundExtrnlIntArea 0 "Default" 1 "Can't recognize" 2 "Fob recognized" 3 "Error Indicator" ;
VAL_ 1108 ESCL_EsclLoBattSta 0 "ESCL Low Battery Bit = 0" 1 "ESCL Low Battery Bit = 1" 2 "Unknown" 3 "Reserved" 4 "Reserved" 5 "Reseved" 6 "Not Used" 7 "Error Indicator" ;
VAL_ 1108 ESCL_EsclUnLkSwSta 0 "EsclNotPowerSupplied" 1 "EsclPowerSupplied&Unlocked" 2 "EsclPowerSupplied&NotUnlocked" 3 "Reserved" 4 "Reserved" 5 "Reseved" 6 "Not Used" 7 "Error Indicator" ;
VAL_ 1108 SMK_DigitalKeyPosReq 0 "DeFault" 1 "Localizing Request" 2 "Not Used" 3 "Error Indicator" ;
VAL_ 1108 SMK_OTACrankInhState 0 "Default" 1 "Cranking inhibit" 2 "IGN,Cranking inhibit" 3 "Reserved" 4 "Reserved" 5 "Reserved" 6 "Reserved" 7 "Error Indicator" ;
VAL_ 1108 Fob_FoundRrLftArea 0 "Default" 1 "Fob Found(RrLft)" 2 "Not Used" 3 "Error Indicator" ;
VAL_ 1108 Fob_FoundRrRtArea 0 "Default" 1 "Fob Found(RrRt)" 2 "Not Used" 3 "Error Indicator" ;
VAL_ 1093 Lamp_HzrdBlnkngSta 0 "Off" 1 "Single Blinking" 2 "Double Blinking" 3 "Reserved" 4 "Reserved" 5 "Reseved" 6 "Not Used" 7 "Error Indicator" ;
VAL_ 1093 RSPA_LearntSta 0 "Non-RSPA Learnt" 1 "RSPA Learnt" 2 "Reserved" 3 "Error Indicator" ;
VAL_ 1093 Lamp_SmrtWlcmLtOnReq 0 "Off" 1 "On" 2 "Not Used" 3 "Error Indicator" ;
VAL_ 1093 Fob_BattStaInfo 0 "Normal or No Information" 1 "Recent used FOB is in discharge warning voltage level" 2 "Not Used" 3 "Error Indicator" ;
VAL_ 1093 Fob_FoundDrvWlcmArea 0 "Default" 1 "Fob Found(Drv)" 2 "Not Used" 3 "Error Indicator" ;
VAL_ 1093 Fob_FoundAsstWlcmArea 0 "Default" 1 "Fob Found(Ast)" 2 "Not Used" 3 "Error Indicator" ;
VAL_ 1093 Fob_FoundExtrnlArea 0 "Default" 1 "Can't recognize" 2 "Fob recognized" 3 "Search in progress" ;
VAL_ 1093 Fob_FoundIntArea 0 "Default" 1 "Can't recognize" 2 "Fob recognized" 3 "Search in progress" ;
VAL_ 1093 Fob_LearntSta 0 "Learnt" 1 "Virgin" 2 "Not Used" 3 "Error Indicator" ;
VAL_ 1093 RSPA_RFSigErrSta 0 "Default" 1 "Signal Invalid" 2 "In Progress" 3 "Error Indicator" ;
VAL_ 1093 RSPA_CanErrSta 0 "Default" 1 "RSPA CAN Error" 2 "Not Used" 3 "Error Indicator" ;
VAL_ 1093 LFAnt_FltSta 0 "Normal" 1 "Fault" 2 "Not Used" 3 "Error Indicator" ;
VAL_ 1093 LFAnt_SrchSta 0 "Off" 1 "On (LF Searching)" 2 "Not Used" 3 "Error Indicator" ;
VAL_ 1093 Auth_ISKLearnSta 0 "Default(Normal)" 1 "Learning" 2 "Invalid" 3 "Neutral" 4 "Reserved" 5 "Reserved" 6 "Not used" 7 "Error Indicator" ;
VAL_ 1093 RSPA_ModSta_SMK 0 "RSPA Off" 1 "RSPA On" 2 "Reserved" 3 "Reserved" 4 "Reserved" 5 "Reseved" 6 "Not Used" 7 "Error Indicator" ;
VAL_ 1093 RSPA_FobBattSta 0 "Normal" 1 "Low Battery" 2 "Reserved" 3 "Reserved" 4 "Reserved" 5 "Reseved" 6 "Not Used" 7 "Error Indicator" ;
VAL_ 1093 Fob_BtnReleasedSta 0 "Default" 1 "Butten Released" 2 "Not used" 3 "Error Indicator" ;
VAL_ 1093 USM_SmrtTrnkTlgtModSta 0 "Default Value" 1 "HandsFree Off" 2 "HandsFree On" 3 "Reserved" 4 "Invalid" 5 "Reserved" 6 "Not Used" 7 "Error Indicator" ;
VAL_ 1093 USM_WALModSta 0 "Default" 1 "WAL Off" 2 "WAL On" 3 "Invalid" 4 "Reserved" 5 "Reseved" 6 "Not Used" 7 "Error Indicator" ;
VAL_ 1093 Fob_FoundWlcmArea 0 "Default (Off)" 1 "Fob Found" 2 "Not Used" 3 "Error Indicator" ;
